VERSION ""

NS_ :

BS_:

BU_: A_IVC BLM CGW VKM

BO_ 32 ACU_A102: 8 CGW
  SG_ AirbagCrashOrder_v3 : 5|6@0+ (1,0) [0|0] "" A_IVC
  SG_ DirectionRear2ndCollision : 8|1@0+ (1,0) [0|0] "" A_IVC
  SG_ DirectionRollover2ndCollision : 9|1@0+ (1,0) [0|0] "" A_IVC
  SG_ DataSetCollisionValidity : 10|1@0+ (1,0) [0|0] "" A_IVC
  SG_ SeatBeltStatusDriver1stCollision : 12|2@0+ (1,0) [0|0] "" A_IVC
  SG_ SeatBeltStatusPass1stCollision : 14|2@0+ (1,0) [0|0] "" A_IVC
  SG_ DirectionLeft1stCollision : 15|1@0+ (1,0) [0|0] "" A_IVC
  SG_ SeatBeltStatusDriver2ndCollision : 18|2@0+ (1,0) [0|0] "" A_IVC
  SG_ SeatBeltStatusPass2ndcollision : 20|2@0+ (1,0) [0|0] "" A_IVC
  SG_ DirectionLeft2ndCollision : 21|1@0+ (1,0) [0|0] "" A_IVC
  SG_ DirectionRight2ndCollision : 22|1@0+ (1,0) [0|0] "" A_IVC
  SG_ DirectionFront2ndCollision : 23|1@0+ (1,0) [0|0] "" A_IVC
  SG_ MaxDeltaVLongi1stCollision : 31|8@0+ (1,-100) [-100|100] "Kph" A_IVC
  SG_ MaxDeltaVLat1stCollision : 39|8@0+ (1,-100) [-100|100] "Kph" A_IVC
  SG_ MaxDeltaVLongi2ndCollision : 47|8@0+ (1,-100) [-100|100] "Kph" A_IVC
  SG_ MaxDeltaVLat2ndCollision : 55|8@0+ (1,-100) [-100|100] "Kph" A_IVC
  SG_ DirectionRollover1stCollision : 56|1@0+ (1,0) [0|0] "" A_IVC
  SG_ RolloverDetection : 57|1@0+ (1,0) [0|0] "" A_IVC
  SG_ DirectionRight1stCollision : 61|1@0+ (1,0) [0|0] "" A_IVC
  SG_ DirectionFront1stCollision : 62|1@0+ (1,0) [0|0] "" A_IVC
  SG_ DirectionRear1stCollision : 63|1@0+ (1,0) [0|0] "" A_IVC

BO_ 116 ECM_A110: 8 CGW
  SG_ PowerTrainSetPoint : 11|10@0+ (0.125,0) [0|125] "%" A_IVC
  SG_ RawSensor : 17|10@0+ (0.125,0) [0|125] "%" A_IVC
  SG_ StopAutoPhase : 47|3@0+ (1,0) [0|0] "" A_IVC

BO_ 117 ECM_A112: 8 CGW
  SG_ ECM_EstimatedPWTWheelTorque : 11|15@0+ (2,-20000) [-20000|20000] "Nm" A_IVC
  SG_ PowerTrainStatus : 25|2@0+ (1,0) [0|0] "" A_IVC
  SG_ EngineStopRequestOrigin : 28|3@0+ (1,0) [0|0] "" A_IVC
  SG_ EngineRPM : 39|16@0+ (0.125,0) [0|8191.75] "rpm" A_IVC
  SG_ MeanEffectiveTorque : 55|12@0+ (0.5,-400) [-400|1647] "Nm" A_IVC

BO_ 168 STRG_A1: 7 CGW
  SG_ SteeringWheelRotationSpeed : 47|16@0+ (0.1,-3276.7) [-3276.7|3276.7] "°/s" A_IVC

BO_ 171 VDC_A6: 8 CGW
  SG_ YawRateCorrected : 10|11@0+ (0.1,-100) [-100|100] "°/s" A_IVC
  SG_ BrakingPressure : 31|8@0+ (0.5,0) [0|126] "bar" A_IVC
  SG_ SteerRackPinionAngleCorrect : 39|15@0+ (0.1,-1080) [-1080|1080] "°" A_IVC
  SG_ YawRateRaw : 55|11@0+ (0.1,-100) [-100|100] "°/s" A_IVC

BO_ 180 VDC_A5: 8 CGW
  SG_ LongitudinalAccelCorrected : 23|12@0+ (0.001,-2) [-2|2] "G" A_IVC
  SG_ LongitudinalAccelRaw : 27|12@0+ (0.001,-2) [-2|2] "G" A_IVC
  SG_ TransversalAccelCorrected : 47|12@0+ (0.001,-2) [-2|2] "G" A_IVC
  SG_ TransversalAccelRaw : 51|12@0+ (0.001,-2) [-2|2] "G" A_IVC

BO_ 255 VDC_A10: 6 CGW
  SG_ MastervacPressure_v2 : 23|7@0+ (1,0) [0|100] "kPa" A_IVC

BO_ 303 ATCU_A108: 7 CGW
  SG_ GearLeverPosition_v2 : 20|4@0+ (1,0) [0|0] "" A_IVC

BO_ 380 STRG_A2: 7 CGW
  SG_ SteeringWheelRotationSpeed_EPS : 47|16@0+ (0.1,-3276.7) [-3276.7|3276.7] "°/s" A_IVC

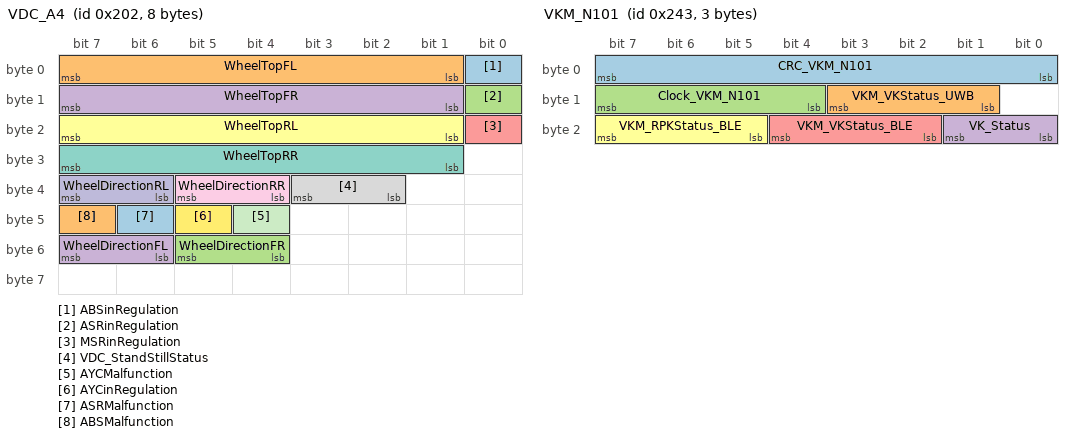
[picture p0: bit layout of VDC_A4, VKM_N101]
BO_ 514 VDC_A4: 8 CGW
  SG_ ABSinRegulation : 0|1@0+ (1,0) [0|0] "" A_IVC
  SG_ WheelTopFL : 7|7@0+ (1,0) [0|96] "top" A_IVC
  SG_ ASRinRegulation : 8|1@0+ (1,0) [0|0] "" A_IVC
  SG_ WheelTopFR : 15|7@0+ (1,0) [0|96] "top" A_IVC
  SG_ MSRinRegulation : 16|1@0+ (1,0) [0|0] "" A_IVC
  SG_ WheelTopRL : 23|7@0+ (1,0) [0|96] "top" A_IVC
  SG_ WheelTopRR : 31|7@0+ (1,0) [0|96] "top" A_IVC
  SG_ VDC_StandStillStatus : 35|2@0+ (1,0) [0|0] "" A_IVC
  SG_ WheelDirectionRR : 37|2@0+ (1,0) [0|0] "" A_IVC
  SG_ WheelDirectionRL : 39|2@0+ (1,0) [0|0] "" A_IVC
  SG_ AYCMalfunction : 44|1@0+ (1,0) [0|0] "" A_IVC
  SG_ AYCinRegulation : 45|1@0+ (1,0) [0|0] "" A_IVC
  SG_ ASRMalfunction : 46|1@0+ (1,0) [0|0] "" A_IVC
  SG_ ABSMalfunction : 47|1@0+ (1,0) [0|0] "" A_IVC
  SG_ WheelDirectionFR : 53|2@0+ (1,0) [0|0] "" A_IVC
  SG_ WheelDirectionFL : 55|2@0+ (1,0) [0|0] "" A_IVC

BO_ 534 EPS_A101: 4 CGW
  SG_ EPSWarning : 19|2@0+ (1,0) [0|0] "" A_IVC

BO_ 546 USM_A102: 4 CGW
  SG_ ProducerVoltageRequest : 7|8@0+ (0.025,11.7) [11.7|16] "V" A_IVC
  SG_ BatteryCurrentSensorValue : 15|10@0+ (1,-320) [-320|320] "A" A_IVC
  SG_ ACCompClutchStatus : 31|1@0+ (1,0) [0|0] "" A_IVC

BO_ 552 TCU_N103: 8 A_IVC
  SG_ TerminationReq_Offboard : 7|64@0+ (1,0) [0|0] "" VKM

BO_ 579 VKM_N101: 3 VKM
  SG_ CRC_VKM_N101 : 7|8@0+ (1,0) [0|255] "" CGW
  SG_ VKM_VKStatus_UWB : 11|3@0+ (1,0) [0|0] "" CGW
  SG_ Clock_VKM_N101 : 15|4@0+ (1,0) [0|15] "" CGW
  SG_ VK_Status : 17|2@0+ (1,0) [0|0] "" CGW
  SG_ VKM_VKStatus_BLE : 20|3@0+ (1,0) [0|0] "" CGW
  SG_ VKM_RPKStatus_BLE : 23|3@0+ (1,0) [0|0] "" CGW

BO_ 649 VDC_A3: 8 CGW
  SG_ WheelSpeedRL : 23|16@0+ (0.0416666667,0) [0|2730.583333] "rpm" A_IVC
  SG_ WheelSpeedRR : 39|16@0+ (0.0416666667,0) [0|2730.583333] "rpm" A_IVC
  SG_ VehicleSpeedBody : 55|16@0+ (0.01,0) [0|655.34] "km/h" A_IVC

BO_ 650 VDC_A9: 8 CGW
  SG_ WheelSpeedFR : 7|16@0+ (0.0416666667,0) [0|2730.583333] "rpm" A_IVC
  SG_ WheelSpeedFL : 23|16@0+ (0.0416666667,0) [0|2730.583333] "rpm" A_IVC
  SG_ VehicleSpeed : 39|16@0+ (0.01,0) [0|655.34] "km/h" A_IVC,BLM,VKM

BO_ 696 ECM_R104: 4 CGW
  SG_ LPGFuelConsumption : 7|8@0+ (0.000020,0) [0|0.00508] "L" A_IVC

BO_ 711 TCU_A105: 8 A_IVC
  SG_ PnCcertificateData_v3 : 7|48@0+ (1,0) [0|2.81474976710655E14] "" CGW
  SG_ PnCcertificateDataBlockNumber_v2 : 51|12@0+ (1,0) [0|4095] "" CGW
  SG_ CertificateDataBlockSize : 55|4@0+ (1,0) [0|15] "byte" CGW

BO_ 748 AVM_N110: 8 CGW
  SG_ RPK_VEHTOVKM_A1 : 7|64@0+ (1,0) [0|0] "" VKM

BO_ 749 AVM_N111: 8 CGW
  SG_ RPK_VEHTOVKM_A2 : 7|64@0+ (1,0) [0|0] "" VKM

BO_ 750 AVM_N112: 8 CGW
  SG_ RPK_VEHTOVKM_A3 : 7|64@0+ (1,0) [0|0] "" VKM

BO_ 751 AVM_N113: 8 CGW
  SG_ RPK_VEHTOVKM_A4 : 7|64@0+ (1,0) [0|0] "" VKM

BO_ 764 VKM_N102: 8 VKM
  SG_ RPK_VKMTOVEH_A1 : 7|64@0+ (1,0) [0|0] "" CGW

BO_ 765 VKM_N103: 8 VKM
  SG_ RPK_VKMTOVEH_A2 : 7|64@0+ (1,0) [0|0] "" CGW

BO_ 766 VKM_N104: 8 VKM
  SG_ RPK_VKMTOVEH_A3 : 7|64@0+ (1,0) [0|0] "" CGW

BO_ 767 VKM_N105: 8 VKM
  SG_ RPK_VKMTOVEH_A4 : 7|64@0+ (1,0) [0|0] "" CGW

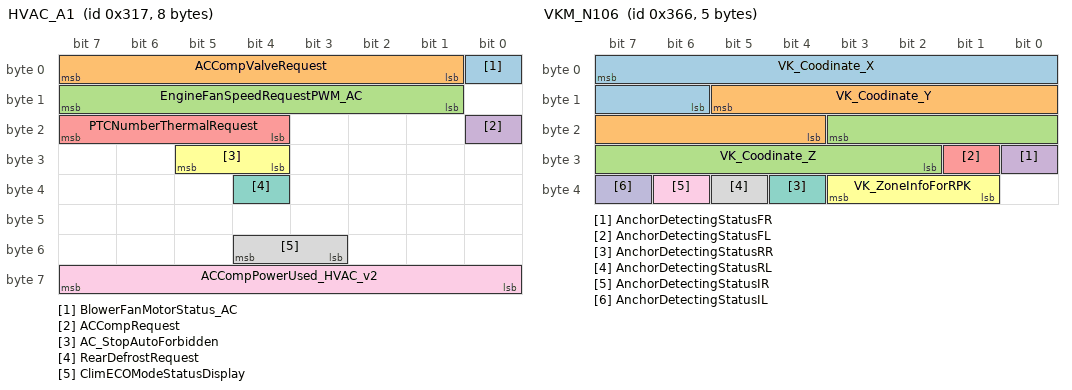
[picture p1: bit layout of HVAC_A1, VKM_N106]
BO_ 791 HVAC_A1: 8 CGW
  SG_ BlowerFanMotorStatus_AC : 0|1@0+ (1,0) [0|0] "" A_IVC
  SG_ ACCompValveRequest : 7|7@0+ (0.01,0) [0|1] "A" A_IVC
  SG_ EngineFanSpeedRequestPWM_AC : 15|7@0+ (1,0) [0|100] "%" A_IVC
  SG_ ACCompRequest : 16|1@0+ (1,0) [0|0] "" A_IVC
  SG_ PTCNumberThermalRequest : 23|4@0+ (1,0) [0|0] "" A_IVC
  SG_ AC_StopAutoForbidden : 29|2@0+ (1,0) [0|0] "" A_IVC
  SG_ RearDefrostRequest : 36|1@0+ (1,0) [0|0] "" A_IVC
  SG_ ClimECOModeStatusDisplay : 52|2@0+ (1,0) [0|0] "" A_IVC
  SG_ ACCompPowerUsed_HVAC_v2 : 63|8@0+ (25,0) [0|6350] "W" A_IVC

BO_ 823 HVAC_R4: 5 CGW
  SG_ ClimForcedRecyDisplay : 17|2@0+ (1,0) [0|0] "" A_IVC
  SG_ ClimAutoRecyclingDisplay : 31|2@0+ (1,0) [0|0] "" A_IVC

BO_ 867 AVM_N109: 1 CGW
  SG_ RPK_UWBRequest : 7|1@0+ (1,0) [0|0] "" VKM

BO_ 870 VKM_N106: 5 VKM
  SG_ VK_Coodinate_X : 7|10@0+ (4,-2048) [-2048|2044] "cm" CGW
  SG_ VK_Coodinate_Y : 13|10@0+ (4,-2048) [-2048|2044] "cm" CGW
  SG_ VK_Coodinate_Z : 19|10@0+ (4,-2048) [-2048|2044] "cm" CGW
  SG_ AnchorDetectingStatusFR : 24|1@0+ (1,0) [0|0] "" CGW
  SG_ AnchorDetectingStatusFL : 25|1@0+ (1,0) [0|0] "" CGW
  SG_ VK_ZoneInfoForRPK : 35|3@0+ (1,0) [0|0] "" CGW
  SG_ AnchorDetectingStatusRR : 36|1@0+ (1,0) [0|0] "" CGW
  SG_ AnchorDetectingStatusRL : 37|1@0+ (1,0) [0|0] "" CGW
  SG_ AnchorDetectingStatusIR : 38|1@0+ (1,0) [0|0] "" CGW
  SG_ AnchorDetectingStatusIL : 39|1@0+ (1,0) [0|0] "" CGW

BO_ 878 ECM_INIT_INFO_RN1: 7 CGW
  SG_ StarterActivationCounter : 7|16@0+ (10,0) [0|600000] "" A_IVC
  SG_ HPPumpActivationCounter : 23|16@0+ (10,0) [0|600000] "" A_IVC
  SG_ BSGActivationCounter : 39|21@0+ (1,0) [0|1500000] "nb of restart" A_IVC

BO_ 893 EPS_A103: 3 CGW
  SG_ LDW_VibrationIntensityState : 2|2@0+ (1,0) [0|0] "" A_IVC
  SG_ CDU_SteeringWheelTorqueLevel : 21|2@0+ (1,0) [0|0] "" A_IVC

BO_ 896 TCO1: 3 CGW
  SG_ DTCO_Driver1TimeRelatedStates : 11|4@0+ (1,0) [0|0] "" A_IVC
  SG_ DTCO_OverSpeed : 15|2@0+ (1,0) [0|0] "" A_IVC
  SG_ DTCO_Driver2TimeRelatedStates : 19|4@0+ (1,0) [0|0] "" A_IVC

BO_ 909 VKM_N113: 8 VKM
  SG_ NFCframe_VKM_to_NFC_Inside : 7|64@0+ (1,0) [0|0] "" CGW

BO_ 944 BCM_A117: 3 CGW
  SG_ HeavyRain_Status : 19|1@0+ (1,0) [0|0] "" A_IVC
  SG_ BCM_ContextSteeringSwitchStatus : 20|1@0+ (1,0) [0|0] "" A_IVC

BO_ 955 ECM_R102: 8 CGW
  SG_ RST_Boost_Duration_MMI : 7|7@0+ (1,0) [0|100] "%" A_IVC
  SG_ RST_Boost_Activation_MMI : 15|2@0+ (1,0) [0|0] "" A_IVC
  SG_ LPGLevelForDisplay : 23|8@0+ (0.25,0) [0|63.5] "L" A_IVC

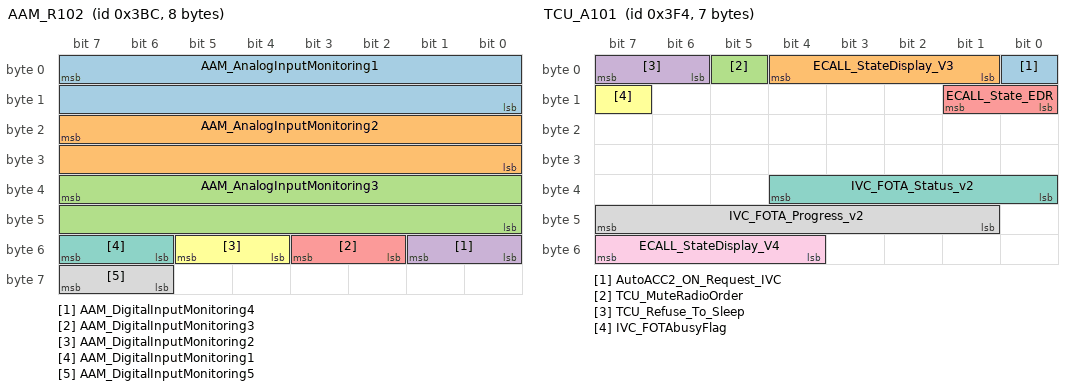
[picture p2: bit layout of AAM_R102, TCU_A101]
BO_ 956 AAM_R102: 8 CGW
  SG_ AAM_AnalogInputMonitoring1 : 7|16@0+ (1,0) [0|65534] "wu" A_IVC
  SG_ AAM_AnalogInputMonitoring2 : 23|16@0+ (1,0) [0|65534] "wu" A_IVC
  SG_ AAM_AnalogInputMonitoring3 : 39|16@0+ (1,0) [0|65534] "wu" A_IVC
  SG_ AAM_DigitalInputMonitoring4 : 49|2@0+ (1,0) [0|0] "" A_IVC
  SG_ AAM_DigitalInputMonitoring3 : 51|2@0+ (1,0) [0|0] "" A_IVC
  SG_ AAM_DigitalInputMonitoring2 : 53|2@0+ (1,0) [0|0] "" A_IVC
  SG_ AAM_DigitalInputMonitoring1 : 55|2@0+ (1,0) [0|0] "" A_IVC
  SG_ AAM_DigitalInputMonitoring5 : 63|2@0+ (1,0) [0|0] "" A_IVC

BO_ 960 PSD_A101: 3 CGW
  SG_ PSD_R_LatchStatus : 9|2@0+ (1,0) [0|0] "" VKM
  SG_ PSD_R_FailureStatus : 12|3@0+ (1,0) [0|0] "" VKM
  SG_ PSD_R_ZoningPosition : 15|3@0+ (1,0) [0|0] "" VKM
  SG_ PSD_R_MovementAuthorizationState : 23|2@0+ (1,0) [0|0] "" VKM

BO_ 967 IVI_A5: 8 CGW
  SG_ SwitchRequest_AVM : 16|1@0+ (1,0) [0|0] "" A_IVC
  SG_ PassengerHeatingRequest : 33|2@0+ (1,0) [0|0] "" A_IVC

BO_ 970 BLM_A101: 1 BLM
  SG_ VirtualKeyState : 4|1@0+ (1,0) [0|0] "" A_IVC,CGW
  SG_ VirtualKeyActivationStatus : 5|1@0+ (1,0) [0|0] "" CGW
  SG_ BLM_RefuseToSleep : 7|2@0+ (1,0) [0|0] "" CGW

BO_ 996 DSMU_A101: 3 CGW
  SG_ DriverMassageProgramState_v3 : 20|4@0+ (1,0) [0|0] "" A_IVC

BO_ 1000 HFM_A101: 7 CGW
  SG_ RemoteLight_HFM : 2|1@0+ (1,0) [0|0] "" A_IVC
  SG_ IKeyRemoteUnProtectStatus : 16|1@0+ (1,0) [0|0] "" A_IVC
  SG_ IkeyfobInsideVehicleFound_VK : 42|3@0+ (1,0) [0|0] "" VKM
  SG_ VKAuthRequest : 45|1@0+ (1,0) [0|0] "" VKM

BO_ 1001 PSCU_A102: 1 CGW
  SG_ PassengerMassageProgramState_v3 : 3|4@0+ (1,0) [0|0] "" A_IVC

BO_ 1011 VKM_N107: 6 VKM
  SG_ VKM_RefuseToSleep : 44|2@0+ (1,0) [0|0] "" CGW
  SG_ NFC_Inside_activation_frame : 45|1@0+ (1,0) [0|0] "" CGW
  SG_ InsideIkeyfobSearchRequest : 47|1@0+ (1,0) [0|0] "" CGW

BO_ 1012 TCU_A101: 7 A_IVC
  SG_ AutoACC2_ON_Request_IVC : 0|1@0+ (1,0) [0|0] "" CGW
  SG_ ECALL_StateDisplay_V3 : 4|4@0+ (1,0) [0|0] "" CGW
  SG_ TCU_MuteRadioOrder : 5|1@0+ (1,0) [0|0] "" CGW
  SG_ TCU_Refuse_To_Sleep : 7|2@0+ (1,0) [0|0] "" CGW
  SG_ ECALL_State_EDR : 9|2@0+ (1,0) [0|0] "" CGW
  SG_ IVC_FOTAbusyFlag : 15|1@0+ (1,0) [0|0] "" CGW
  SG_ IVC_FOTA_Status_v2 : 36|5@0+ (1,0) [0|0] "" CGW
  SG_ IVC_FOTA_Progress_v2 : 47|7@0+ (1,0) [0|100] "%" CGW
  SG_ ECALL_StateDisplay_V4 : 55|4@0+ (1,0) [0|0] "" CGW

BO_ 1030 AVM_N106: 6 CGW
  SG_ RPK_RegistAddress3 : 7|48@0+ (1,0) [0|2.81474976710655E14] "-" VKM

BO_ 1031 AVM_N107: 6 CGW
  SG_ RPK_RegistAddress4 : 7|48@0+ (1,0) [0|2.81474976710655E14] "-" VKM

BO_ 1036 AVM_N108: 6 CGW
  SG_ RPK_RegistAddress5 : 7|48@0+ (1,0) [0|2.81474976710655E14] "-" VKM

BO_ 1047 AVM_A119: 3 CGW
  SG_ HFP_ExtendedInstrContentDisplay2 : 23|5@0+ (1,0) [0|0] "" A_IVC

BO_ 1049 AAM_R101: 2 CGW
  SG_ AAM_StopAutoForbidden : 2|2@0+ (1,0) [0|0] "" A_IVC

BO_ 1055 HEVC_R129: 8 CGW
  SG_ RE_ElecMaxGenTorque_BLMS : 6|10@0+ (0.5,0) [0|500] "Nm" A_IVC
  SG_ RE_ElecMaxMotorTorque_BLMS : 12|10@0+ (0.5,0) [0|500] "Nm" A_IVC

BO_ 1064 HEVC_A104: 7 CGW
  SG_ EcoNavFuelSaving : 0|10@0+ (0.01,0) [0|10] "L" A_IVC
  SG_ HVbatteryTemperature : 7|7@0+ (1,-40) [-40|80] "°C" A_IVC
  SG_ VehicleAutonomyZEV : 22|10@0+ (1,0) [0|1022] "km" A_IVC
  SG_ HVBatConditionningMode : 28|2@0+ (1,0) [0|0] "" A_IVC

BO_ 1065 HEVC_A105: 8 CGW
  SG_ HVBatteryCoolingLoopTemperature : 7|8@0+ (1,-50) [-50|130] "°C" A_IVC
  SG_ HVBatteryLow : 8|1@0+ (1,0) [0|0] "" A_IVC
  SG_ HVBatteryEnergyLevel : 15|7@0+ (1,0) [0|100] "%" A_IVC
  SG_ ChargingPlugConnected_v2 : 23|2@0+ (1,0) [0|0] "" A_IVC
  SG_ EcoNavStatus_v2 : 36|4@0+ (1,0) [0|0] "" A_IVC

BO_ 1066 HEVC_A106: 8 CGW
  SG_ ElecMachineSpeed_EDR : 35|12@0+ (10,-20000) [-20000|20000] "rpm" A_IVC
  SG_ HVbatteryChargeType_v2 : 50|3@0+ (1,0) [0|0] "" A_IVC
  SG_ RegenBrakingLevelDisplay : 53|3@0+ (1,0) [0|0] "" A_IVC
  SG_ RelativeEnginePowerv2 : 63|7@0+ (1,0) [0|100] "%" A_IVC

BO_ 1067 HEVC_A107: 8 CGW
  SG_ RE_ElecMachineTemp_BLMS : 26|8@0+ (1,-40) [-40|210] "°C" A_IVC
  SG_ RE_InverterTemp_BLMS : 34|8@0+ (1,-40) [-40|210] "°C" A_IVC
  SG_ RE_ElecMachineSpeed_BLMS : 42|12@0+ (10,-20000) [-20000|20000] "rpm" A_IVC

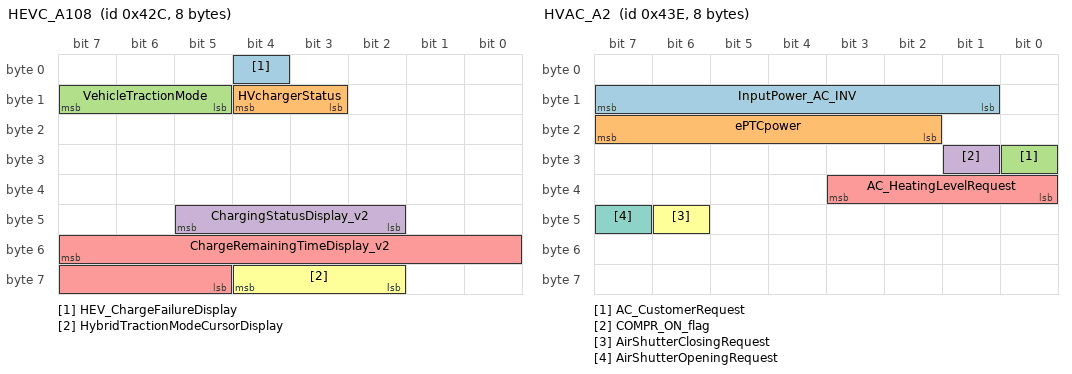
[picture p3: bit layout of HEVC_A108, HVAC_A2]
BO_ 1068 HEVC_A108: 8 CGW
  SG_ HEV_ChargeFailureDisplay : 4|1@0+ (1,0) [0|0] "" A_IVC
  SG_ HVchargerStatus : 12|2@0+ (1,0) [0|0] "" A_IVC
  SG_ VehicleTractionMode : 15|3@0+ (1,0) [0|0] "" A_IVC
  SG_ ChargingStatusDisplay_v2 : 45|4@0+ (1,0) [0|0] "" A_IVC
  SG_ ChargeRemainingTimeDisplay_v2 : 55|11@0+ (1,0) [0|2046] "min" A_IVC
  SG_ HybridTractionModeCursorDisplay : 60|3@0+ (1,0) [0|0] "" A_IVC

BO_ 1070 HEVC_R101: 7 CGW
  SG_ UserSOC : 7|8@0+ (0.392157,0) [0|100] "%" A_IVC

BO_ 1071 HEVC_R103: 3 CGW
  SG_ AvailableEnergy_HEVC : 12|11@0+ (0.05,0) [0|100] "kWh" A_IVC

BO_ 1076 HFM_A104: 8 CGW
  SG_ BadgeBatteryLow : 8|1@0+ (1,0) [0|0] "" A_IVC
  SG_ PushtoStartButton : 51|1@0+ (1,0) [0|0] "" A_IVC

BO_ 1081 VDC_A114: 7 CGW
  SG_ SlopeEstimation : 7|8@0+ (0.2,-15) [-15|15] "°" A_IVC
  SG_ DistanceTotalizer : 15|28@0+ (0.01,0) [0|2600000] "km" A_IVC,BLM,VKM

BO_ 1086 HVAC_A2: 8 CGW
  SG_ InputPower_AC_INV : 15|7@0+ (50,0) [0|5100] "W" A_IVC
  SG_ ePTCpower : 23|6@0+ (250,0) [0|10000] "W" A_IVC
  SG_ AC_CustomerRequest : 24|1@0+ (1,0) [0|0] "" A_IVC
  SG_ COMPR_ON_flag : 25|1@0+ (1,0) [0|0] "" A_IVC
  SG_ AC_HeatingLevelRequest : 35|4@0+ (1,0) [0|10] "wu" A_IVC
  SG_ AirShutterClosingRequest : 46|1@0+ (1,0) [0|0] "" A_IVC
  SG_ AirShutterOpeningRequest : 47|1@0+ (1,0) [0|0] "" A_IVC

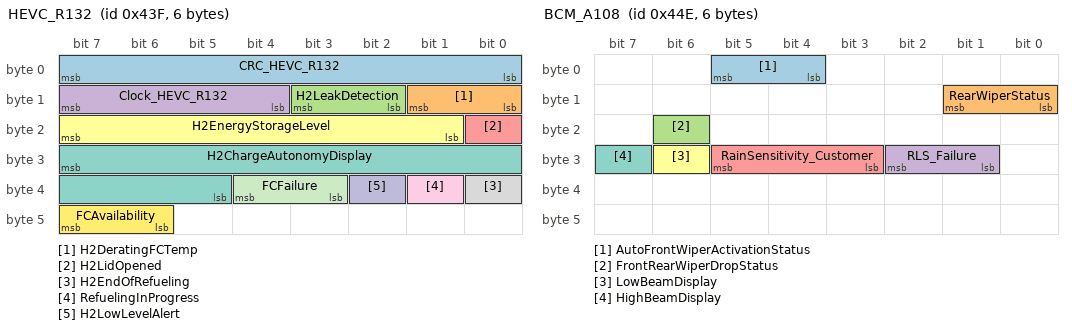
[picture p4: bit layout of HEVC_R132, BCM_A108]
BO_ 1087 HEVC_R132: 6 CGW
  SG_ CRC_HEVC_R132 : 7|8@0+ (1,0) [0|255] "" A_IVC
  SG_ H2DeratingFCTemp : 9|2@0+ (1,0) [0|0] "" A_IVC
  SG_ H2LeakDetection : 11|2@0+ (1,0) [0|0] "" A_IVC
  SG_ Clock_HEVC_R132 : 15|4@0+ (1,0) [0|15] "" A_IVC
  SG_ H2LidOpened : 16|1@0+ (1,0) [0|0] "" A_IVC
  SG_ H2EnergyStorageLevel : 23|7@0+ (1,0) [0|100] "%" A_IVC
  SG_ H2ChargeAutonomyDisplay : 31|11@0+ (1,0) [0|2047] "KM" A_IVC
  SG_ H2EndOfRefueling : 32|1@0+ (1,0) [0|0] "" A_IVC
  SG_ RefuelingInProgress : 33|1@0+ (1,0) [0|0] "" A_IVC
  SG_ H2LowLevelAlert : 34|1@0+ (1,0) [0|0] "" A_IVC
  SG_ FCFailure : 36|2@0+ (1,0) [0|0] "" A_IVC
  SG_ FCAvailability : 47|2@0+ (1,0) [0|0] "" A_IVC

BO_ 1090 PSDL_A101: 3 CGW
  SG_ PSD_L_ZoningPosition : 10|3@0+ (1,0) [0|0] "" VKM
  SG_ PSD_L_MovementAuthorizationState : 15|2@0+ (1,0) [0|0] "" VKM
  SG_ PSD_L_LatchStatus : 20|2@0+ (1,0) [0|0] "" VKM
  SG_ PSD_L_FailureStatus : 23|3@0+ (1,0) [0|0] "" VKM

BO_ 1099 ATCU_A109: 8 CGW
  SG_ RST_LaunchControlReadyMMI : 13|2@0+ (1,0) [0|0] "" A_IVC
  SG_ ATCVT_TowingMode : 14|1@0+ (1,0) [0|0] "" A_IVC
  SG_ ATCVT_RangeIndicationExtended : 44|6@0+ (1,0) [0|0] "" A_IVC

BO_ 1100 ATCU_A110: 6 CGW
  SG_ AT_Parkfailure : 21|1@0+ (1,0) [0|0] "" A_IVC
  SG_ TransmRangeEngaged_Current : 24|4@0+ (1,0) [0|0] "" A_IVC
  SG_ ShifterPosition : 27|3@0+ (1,0) [0|0] "" A_IVC

BO_ 1101 BCM_A107: 5 CGW
  SG_ TurnSwitchStatus : 18|3@0+ (1,0) [0|0] "" A_IVC
  SG_ FlashingIndicatorStatusDisplay : 23|3@0+ (1,0) [0|0] "" A_IVC

BO_ 1102 BCM_A108: 6 CGW
  SG_ AutoFrontWiperActivationStatus : 5|2@0+ (1,0) [0|0] "" A_IVC
  SG_ RearWiperStatus : 9|2@0+ (1,0) [0|0] "" A_IVC
  SG_ FrontRearWiperDropStatus : 22|1@0+ (1,0) [0|0] "" A_IVC
  SG_ RLS_Failure : 26|2@0+ (1,0) [0|0] "" A_IVC
  SG_ RainSensitivity_Customer : 29|3@0+ (1,0) [0|0] "" A_IVC
  SG_ LowBeamDisplay : 30|1@0+ (1,0) [0|0] "" A_IVC
  SG_ HighBeamDisplay : 31|1@0+ (1,0) [0|0] "" A_IVC

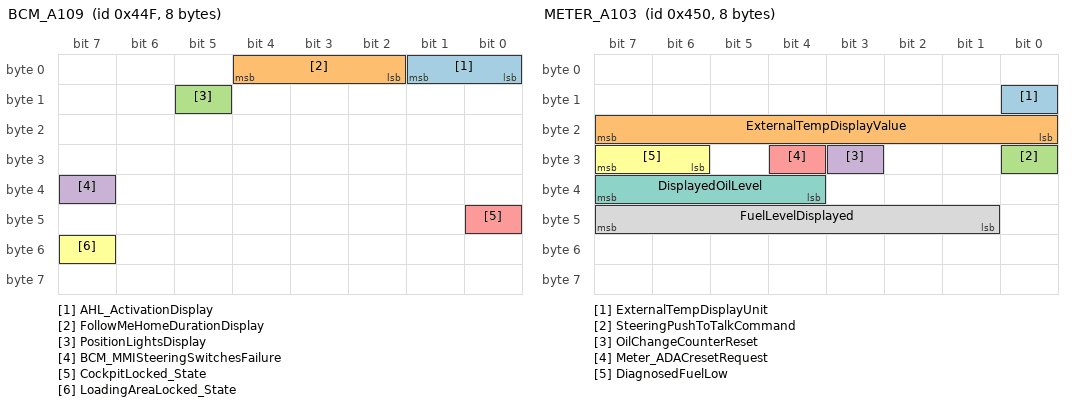
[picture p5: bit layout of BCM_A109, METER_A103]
BO_ 1103 BCM_A109: 8 CGW
  SG_ AHL_ActivationDisplay : 1|2@0+ (1,0) [0|0] "" A_IVC
  SG_ FollowMeHomeDurationDisplay : 4|3@0+ (1,0) [0|0] "" A_IVC
  SG_ PositionLightsDisplay : 13|1@0+ (1,0) [0|0] "" A_IVC
  SG_ BCM_MMISteeringSwitchesFailure : 39|1@0+ (1,0) [0|0] "" A_IVC
  SG_ CockpitLocked_State : 40|1@0+ (1,0) [0|0] "" BLM
  SG_ LoadingAreaLocked_State : 55|1@0+ (1,0) [0|0] "" BLM

BO_ 1104 METER_A103: 8 CGW
  SG_ ExternalTempDisplayUnit : 8|1@0+ (1,0) [0|0] "" A_IVC
  SG_ ExternalTempDisplayValue : 23|8@0+ (1,-40) [-40|140] "" A_IVC
  SG_ SteeringPushToTalkCommand : 24|1@0+ (1,0) [0|0] "" A_IVC
  SG_ OilChangeCounterReset : 27|1@0+ (1,0) [0|0] "" A_IVC
  SG_ Meter_ADACresetRequest : 28|1@0+ (1,0) [0|0] "" A_IVC
  SG_ DiagnosedFuelLow : 31|2@0+ (1,0) [0|0] "" A_IVC
  SG_ DisplayedOilLevel : 39|4@0+ (1,0) [0|0] "" A_IVC
  SG_ FuelLevelDisplayed : 47|7@0+ (1,0) [0|80] "L" A_IVC

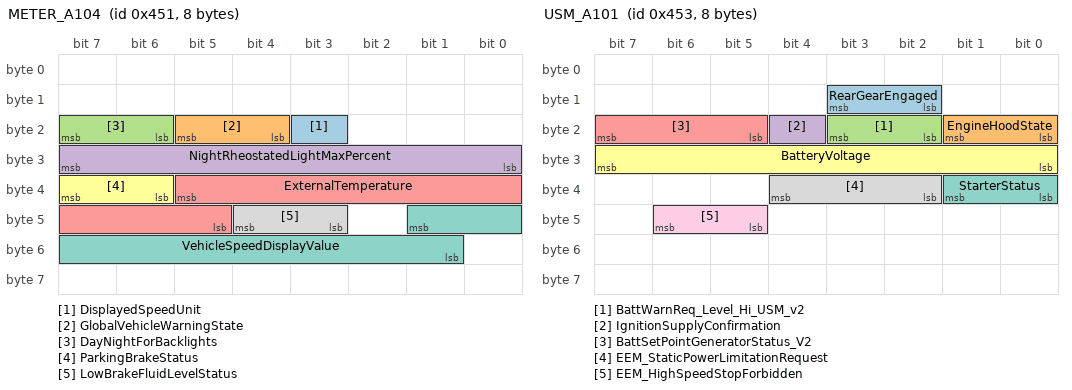
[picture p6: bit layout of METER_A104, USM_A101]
BO_ 1105 METER_A104: 8 CGW
  SG_ DisplayedSpeedUnit : 19|1@0+ (1,0) [0|0] "" A_IVC
  SG_ GlobalVehicleWarningState : 21|2@0+ (1,0) [0|0] "" A_IVC
  SG_ DayNightForBacklights : 23|2@0+ (1,0) [0|0] "" A_IVC
  SG_ NightRheostatedLightMaxPercent : 31|8@0+ (0.4,0) [0|100] "%" A_IVC
  SG_ ExternalTemperature : 37|9@0+ (0.25,-50) [-50|70] "°C" A_IVC
  SG_ ParkingBrakeStatus : 39|2@0+ (1,0) [0|0] "" A_IVC
  SG_ VehicleSpeedDisplayValue : 41|9@0+ (1,0) [0|510] "" A_IVC
  SG_ LowBrakeFluidLevelStatus : 44|2@0+ (1,0) [0|0] "" A_IVC

BO_ 1106 METER_A108: 5 CGW
  SG_ TimeBeforeOverhaul : 15|9@0+ (1,0) [0|511] "day" A_IVC
  SG_ DayNightStatusForB_Switches : 17|1@0+ (1,0) [0|0] "" A_IVC
  SG_ TripAverageSpeed : 31|12@0+ (0.1,0) [0|409.5] "" A_IVC

BO_ 1107 USM_A101: 8 CGW
  SG_ RearGearEngaged : 11|2@0+ (1,0) [0|0] "" A_IVC
  SG_ EngineHoodState : 17|2@0+ (1,0) [0|0] "" A_IVC
  SG_ BattWarnReq_Level_Hi_USM_v2 : 19|2@0+ (1,0) [0|0] "" A_IVC
  SG_ IgnitionSupplyConfirmation : 20|1@0+ (1,0) [0|0] "" A_IVC
  SG_ BattSetPointGeneratorStatus_V2 : 23|3@0+ (1,0) [0|0] "" A_IVC
  SG_ BatteryVoltage : 31|8@0+ (0.06,6) [6|18] "V" A_IVC,BLM,VKM
  SG_ StarterStatus : 33|2@0+ (1,0) [0|0] "" A_IVC
  SG_ EEM_StaticPowerLimitationRequest : 36|3@0+ (1,0) [0|0] "" A_IVC
  SG_ EEM_HighSpeedStopForbidden : 46|2@0+ (1,0) [0|0] "" A_IVC

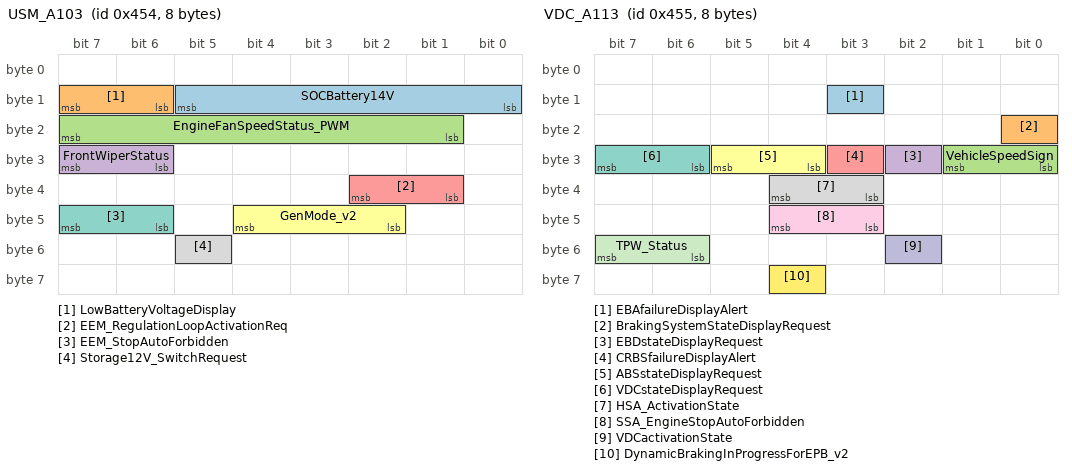
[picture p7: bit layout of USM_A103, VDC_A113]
BO_ 1108 USM_A103: 8 CGW
  SG_ SOCBattery14V : 13|6@0+ (0.5,69) [69|100] "%" A_IVC
  SG_ LowBatteryVoltageDisplay : 15|2@0+ (1,0) [0|0] "" A_IVC
  SG_ EngineFanSpeedStatus_PWM : 23|7@0+ (1,0) [0|100] "%" A_IVC
  SG_ FrontWiperStatus : 31|2@0+ (1,0) [0|0] "" A_IVC
  SG_ EEM_RegulationLoopActivationReq : 34|2@0+ (1,0) [0|0] "" A_IVC
  SG_ GenMode_v2 : 44|3@0+ (1,0) [0|0] "" A_IVC
  SG_ EEM_StopAutoForbidden : 47|2@0+ (1,0) [0|0] "" A_IVC
  SG_ Storage12V_SwitchRequest : 53|1@0+ (1,0) [0|0] "" A_IVC

BO_ 1109 VDC_A113: 8 CGW
  SG_ EBAfailureDisplayAlert : 11|1@0+ (1,0) [0|0] "" A_IVC
  SG_ BrakingSystemStateDisplayRequest : 16|1@0+ (1,0) [0|0] "" A_IVC
  SG_ VehicleSpeedSign : 25|2@0+ (1,0) [0|0] "" A_IVC
  SG_ EBDstateDisplayRequest : 26|1@0+ (1,0) [0|0] "" A_IVC
  SG_ CRBSfailureDisplayAlert : 27|1@0+ (1,0) [0|0] "" A_IVC
  SG_ ABSstateDisplayRequest : 29|2@0+ (1,0) [0|0] "" A_IVC
  SG_ VDCstateDisplayRequest : 31|2@0+ (1,0) [0|0] "" A_IVC
  SG_ HSA_ActivationState : 36|2@0+ (1,0) [0|0] "" A_IVC
  SG_ SSA_EngineStopAutoForbidden : 44|2@0+ (1,0) [0|0] "" A_IVC
  SG_ VDCactivationState : 50|1@0+ (1,0) [0|0] "" A_IVC
  SG_ TPW_Status : 55|2@0+ (1,0) [0|0] "" A_IVC
  SG_ DynamicBrakingInProgressForEPB_v2 : 60|1@0+ (1,0) [0|0] "" A_IVC

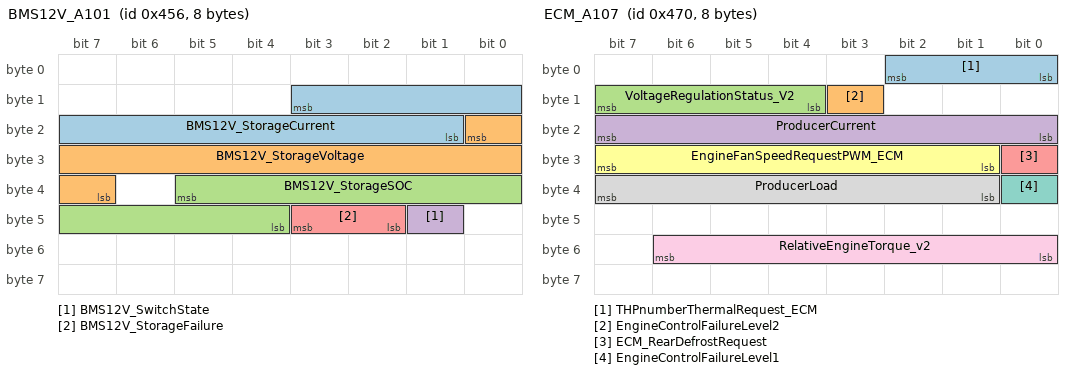
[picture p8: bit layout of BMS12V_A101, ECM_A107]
BO_ 1110 BMS12V_A101: 8 CGW
  SG_ BMS12V_StorageCurrent : 11|11@0+ (0.25,-150) [-150|300] "A" A_IVC
  SG_ BMS12V_StorageVoltage : 16|10@0+ (0.01,9) [9|16] "V" A_IVC
  SG_ BMS12V_StorageSOC : 37|10@0+ (0.1,0) [0|100] "%" A_IVC
  SG_ BMS12V_SwitchState : 41|1@0+ (1,0) [0|0] "" A_IVC
  SG_ BMS12V_StorageFailure : 43|2@0+ (1,0) [0|0] "" A_IVC

BO_ 1119 ECM_A108: 4 CGW
  SG_ BattWarnReq_Level_Hi_ECM_v2 : 11|2@0+ (1,0) [0|0] "" A_IVC
  SG_ EngineCoolantTemp : 23|8@0+ (1,-40) [-40|214] "°C" A_IVC

BO_ 1120 ECM_R101: 8 CGW
  SG_ AccelerationIndicator : 39|7@0+ (1,0) [0|127] "%" A_IVC
  SG_ FluentDrivingIndicator : 47|7@0+ (1,0) [0|127] "%" A_IVC
  SG_ GSI_Respect : 55|7@0+ (1,0) [0|127] "%" A_IVC

BO_ 1136 ECM_A107: 8 CGW
  SG_ THPnumberThermalRequest_ECM : 2|3@0+ (1,0) [0|0] "" A_IVC
  SG_ EngineControlFailureLevel2 : 11|1@0+ (1,0) [0|0] "" A_IVC
  SG_ VoltageRegulationStatus_V2 : 15|4@0+ (1,0) [0|0] "" A_IVC
  SG_ ProducerCurrent : 23|8@0+ (1,0) [0|255] "A" A_IVC
  SG_ ECM_RearDefrostRequest : 24|1@0+ (1,0) [0|0] "" A_IVC
  SG_ EngineFanSpeedRequestPWM_ECM : 31|7@0+ (1,0) [0|100] "%" A_IVC
  SG_ EngineControlFailureLevel1 : 32|1@0+ (1,0) [0|0] "" A_IVC
  SG_ ProducerLoad : 39|7@0+ (1,0) [0|100] "%" A_IVC
  SG_ RelativeEngineTorque_v2 : 54|7@0+ (1,0) [0|100] "%" A_IVC

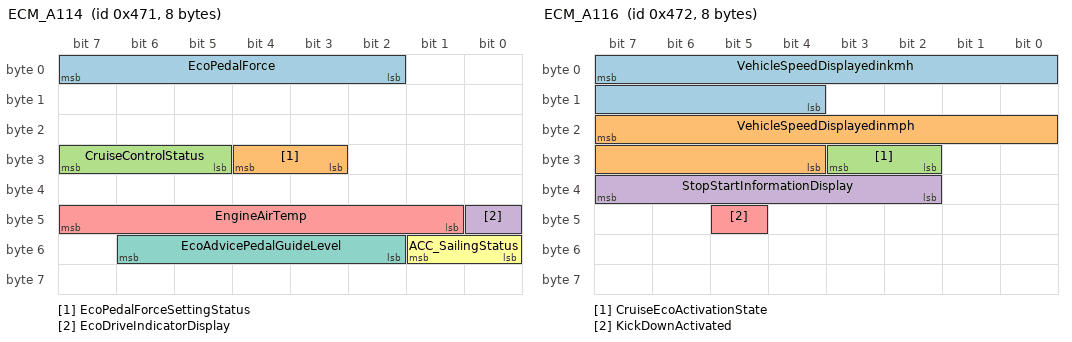
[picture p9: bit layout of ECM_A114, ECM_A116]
BO_ 1137 ECM_A114: 8 CGW
  SG_ EcoPedalForce : 7|6@0+ (0.5,0) [0|15.5] "N" A_IVC
  SG_ EcoPedalForceSettingStatus : 28|2@0+ (1,0) [0|0] "" A_IVC
  SG_ CruiseControlStatus : 31|3@0+ (1,0) [0|0] "" A_IVC
  SG_ EcoDriveIndicatorDisplay : 40|1@0+ (1,0) [0|0] "" A_IVC
  SG_ EngineAirTemp : 47|7@0+ (1,-40) [-40|86] "°C" A_IVC
  SG_ ACC_SailingStatus : 49|2@0+ (1,0) [0|0] "" A_IVC
  SG_ EcoAdvicePedalGuideLevel : 54|5@0+ (1,0) [0|30] "wu" A_IVC

BO_ 1138 ECM_A116: 8 CGW
  SG_ VehicleSpeedDisplayedinkmh : 7|12@0+ (0.1,0) [0|409.4] "km/h" A_IVC
  SG_ VehicleSpeedDisplayedinmph : 23|12@0+ (0.1,0) [0|409.4] "m/h" A_IVC
  SG_ CruiseEcoActivationState : 27|2@0+ (1,0) [0|0] "" A_IVC
  SG_ StopStartInformationDisplay : 39|6@0+ (1,0) [0|0] "" A_IVC
  SG_ KickDownActivated : 45|1@0+ (1,0) [0|0] "" A_IVC

BO_ 1139 ECM_A117: 6 CGW
  SG_ AtmoPressure : 7|10@0+ (0.1,10) [10|110] "kPa" A_IVC
  SG_ DBC_FailureStatus_v2 : 13|2@0+ (1,0) [0|0] "" A_IVC
  SG_ LowPressureACCut : 19|1@0+ (1,0) [0|0] "" A_IVC
  SG_ StopStartActivationStatus : 20|1@0+ (1,0) [0|0] "" A_IVC

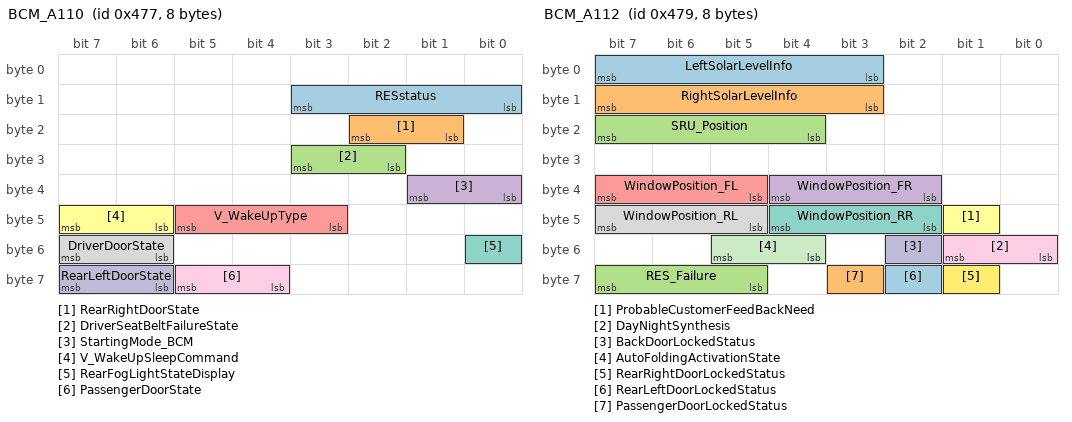
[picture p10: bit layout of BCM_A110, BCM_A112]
BO_ 1143 BCM_A110: 8 CGW
  SG_ RESstatus : 11|4@0+ (1,0) [0|0] "" A_IVC
  SG_ RearRightDoorState : 18|2@0+ (1,0) [0|0] "" A_IVC,BLM,VKM
  SG_ DriverSeatBeltFailureState : 27|2@0+ (1,0) [0|0] "" A_IVC
  SG_ StartingMode_BCM : 33|2@0+ (1,0) [0|0] "" A_IVC
  SG_ V_WakeUpType : 45|3@0+ (1,0) [0|0] "" A_IVC
  SG_ V_WakeUpSleepCommand : 47|2@0+ (1,0) [0|0] "" A_IVC,BLM,VKM
  SG_ RearFogLightStateDisplay : 48|1@0+ (1,0) [0|0] "" A_IVC
  SG_ DriverDoorState : 55|2@0+ (1,0) [0|0] "" A_IVC,BLM,VKM
  SG_ PassengerDoorState : 61|2@0+ (1,0) [0|0] "" A_IVC,BLM,VKM
  SG_ RearLeftDoorState : 63|2@0+ (1,0) [0|0] "" A_IVC,BLM,VKM

BO_ 1144 BCM_A111: 8 CGW
  SG_ ElectricalPowerDrived : 7|5@0+ (100,0) [0|3000] "W" A_IVC
  SG_ TailGateButtonPushed : 10|2@0+ (1,0) [0|0] "" A_IVC
  SG_ WakeUpType : 13|3@0+ (1,0) [0|0] "" A_IVC,BLM,VKM
  SG_ RearDefrostEngaged : 16|1@0+ (1,0) [0|0] "" A_IVC
  SG_ PositionLightsRequest : 17|1@0+ (1,0) [0|0] "" A_IVC
  SG_ FrontFogLightsRequest : 18|1@0+ (1,0) [0|0] "" A_IVC
  SG_ SmartKeylessInformationDisplay : 23|5@0+ (1,0) [0|0] "" BLM
  SG_ PTCNumberThermalStatus : 31|4@0+ (1,0) [0|0] "" A_IVC
  SG_ DriverDoorLockedStatus : 32|1@0+ (1,0) [0|0] "" A_IVC,BLM,VKM
  SG_ DayTimeRunningLightRequest : 33|1@0+ (1,0) [0|0] "" A_IVC
  SG_ HornRequest : 36|3@0+ (1,0) [0|0] "" A_IVC
  SG_ WarningLightsStatus : 41|1@0+ (1,0) [0|0] "" A_IVC
  SG_ VehicleOutsideLockedState : 42|1@0+ (1,0) [0|0] "" A_IVC,BLM,VKM
  SG_ DriverSidePosition : 43|1@0+ (1,0) [0|0] "" A_IVC
  SG_ FrontFogLightsDisplay : 48|1@0+ (1,0) [0|0] "" A_IVC
  SG_ FrontDefrostEngaged : 49|1@0+ (1,0) [0|0] "" A_IVC
  SG_ ManualShiftLeverPosition : 51|2@0+ (1,0) [0|0] "" A_IVC
  SG_ StopStartSwitch : 53|2@0+ (1,0) [0|0] "" A_IVC
  SG_ ShiftPaddleRequest : 55|2@0+ (1,0) [0|0] "" A_IVC
  SG_ BrakeLampStatus : 57|1@0+ (1,0) [0|0] "" A_IVC
  SG_ HeadLampsWasherRequest : 60|1@0+ (1,0) [0|0] "" A_IVC

BO_ 1145 BCM_A112: 8 CGW
  SG_ LeftSolarLevelInfo : 7|5@0+ (50,0) [0|1500] "W" A_IVC
  SG_ RightSolarLevelInfo : 15|5@0+ (50,0) [0|1500] "W" A_IVC
  SG_ SRU_Position : 23|4@0+ (1,0) [0|0] "" A_IVC,VKM
  SG_ WindowPosition_FR : 36|3@0+ (1,0) [0|0] "" A_IVC
  SG_ WindowPosition_FL : 39|3@0+ (1,0) [0|0] "" A_IVC
  SG_ ProbableCustomerFeedBackNeed : 41|1@0+ (1,0) [0|0] "" A_IVC
  SG_ WindowPosition_RR : 44|3@0+ (1,0) [0|0] "" A_IVC
  SG_ WindowPosition_RL : 47|3@0+ (1,0) [0|0] "" A_IVC
  SG_ DayNightSynthesis : 49|2@0+ (1,0) [0|0] "" A_IVC
  SG_ BackDoorLockedStatus : 50|1@0+ (1,0) [0|0] "" A_IVC,BLM,VKM
  SG_ AutoFoldingActivationState : 53|2@0+ (1,0) [0|0] "" A_IVC
  SG_ RearRightDoorLockedStatus : 57|1@0+ (1,0) [0|0] "" A_IVC,BLM,VKM
  SG_ RearLeftDoorLockedStatus : 58|1@0+ (1,0) [0|0] "" A_IVC,BLM,VKM
  SG_ PassengerDoorLockedStatus : 59|1@0+ (1,0) [0|0] "" A_IVC,BLM,VKM
  SG_ RES_Failure : 63|3@0+ (1,0) [0|0] "" A_IVC

BO_ 1146 BCM_A113: 8 CGW
  SG_ IgnitionSwitchPosition : 8|1@0+ (1,0) [0|0] "" A_IVC
  SG_ DriverSafetyBeltBuckleState : 11|2@0+ (1,0) [0|0] "" A_IVC
  SG_ ClutchSwitchMinimumTravel : 17|2@0+ (1,0) [0|0] "" A_IVC
  SG_ TailGateStatus : 19|2@0+ (1,0) [0|0] "" A_IVC,BLM
  SG_ VehicleStates : 23|4@0+ (1,0) [0|0] "" A_IVC,BLM,VKM
  SG_ BrakeInfoStatus : 26|3@0+ (1,0) [0|0] "" A_IVC
  SG_ DeliveryModeInformation_v2 : 28|2@0+ (1,0) [0|0] "" A_IVC
  SG_ FlashingIndicatorCommandPosition : 33|2@0+ (1,0) [0|0] "" A_IVC
  SG_ FlashingIndicatorStatus : 36|3@0+ (1,0) [0|0] "" A_IVC
  SG_ GADE_v2 : 39|3@0+ (1,0) [0|0] "" A_IVC,BLM,VKM
  SG_ StopLampDiagnosis : 41|2@0+ (1,0) [0|0] "" A_IVC
  SG_ FrontWiperStatus_BCM : 43|2@0+ (1,0) [0|0] "" A_IVC
  SG_ FrontWipingRequest : 47|3@0+ (1,0) [0|0] "" A_IVC
  SG_ HighBeamRequest : 49|1@0+ (1,0) [0|0] "" A_IVC
  SG_ HighBeamPassingRequest : 50|1@0+ (1,0) [0|0] "" A_IVC
  SG_ THPNumberThermalRequest : 61|3@0+ (1,0) [0|0] "" A_IVC
  SG_ ClutchSwitchMaximumTravel : 63|2@0+ (1,0) [0|0] "" A_IVC

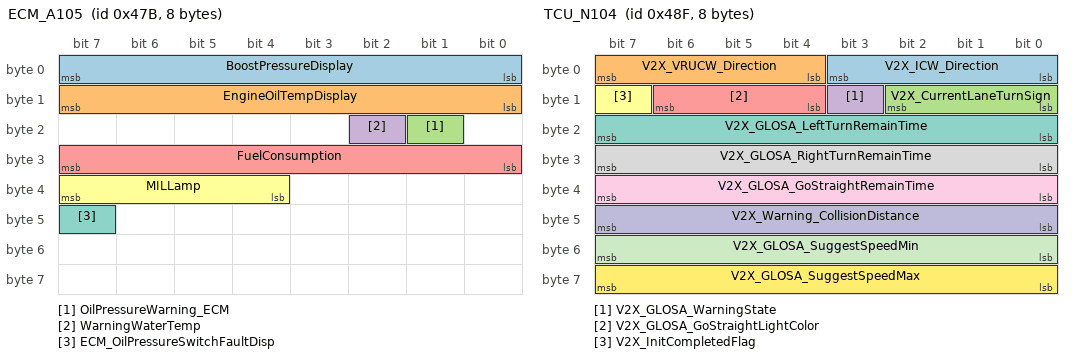
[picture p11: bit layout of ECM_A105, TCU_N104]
BO_ 1147 ECM_A105: 8 CGW
  SG_ BoostPressureDisplay : 7|8@0+ (2,-100) [-100|408] "kPa" A_IVC
  SG_ EngineOilTempDisplay : 15|8@0+ (1,-50) [-50|204] "°C" A_IVC
  SG_ OilPressureWarning_ECM : 17|1@0+ (1,0) [0|0] "" A_IVC
  SG_ WarningWaterTemp : 18|1@0+ (1,0) [0|0] "" A_IVC
  SG_ FuelConsumption : 31|8@0+ (80,0) [0|20400] "mm3" A_IVC
  SG_ MILLamp : 39|4@0+ (1,0) [0|0] "" A_IVC
  SG_ ECM_OilPressureSwitchFaultDisp : 47|1@0+ (1,0) [0|0] "" A_IVC

BO_ 1167 TCU_N104: 8 A_IVC
  SG_ V2X_ICW_Direction : 3|4@0+ (1,0) [0|0] "" CGW
  SG_ V2X_VRUCW_Direction : 7|4@0+ (1,0) [0|0] "" CGW
  SG_ V2X_CurrentLaneTurnSign : 10|3@0+ (1,0) [0|0] "" CGW
  SG_ V2X_GLOSA_WarningState : 11|1@0+ (1,0) [0|0] "" CGW
  SG_ V2X_GLOSA_GoStraightLightColor : 14|3@0+ (1,0) [0|0] "" CGW
  SG_ V2X_InitCompletedFlag : 15|1@0+ (1,0) [0|0] "" CGW
  SG_ V2X_GLOSA_LeftTurnRemainTime : 23|8@0+ (1,0) [0|254] "s" CGW
  SG_ V2X_GLOSA_RightTurnRemainTime : 31|8@0+ (1,0) [0|254] "s" CGW
  SG_ V2X_GLOSA_GoStraightRemainTime : 39|8@0+ (1,0) [0|254] "s" CGW
  SG_ V2X_Warning_CollisionDistance : 47|8@0+ (1,0) [0|254] "m" CGW
  SG_ V2X_GLOSA_SuggestSpeedMin : 55|8@0+ (1,0) [0|254] "km/h" CGW
  SG_ V2X_GLOSA_SuggestSpeedMax : 63|8@0+ (1,0) [0|254] "km/h" CGW

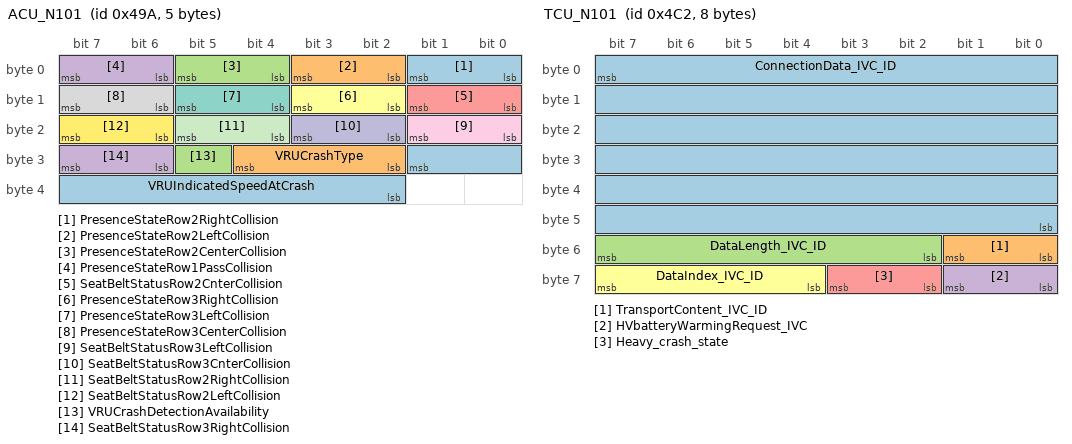
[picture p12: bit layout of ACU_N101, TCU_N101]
BO_ 1178 ACU_N101: 5 CGW
  SG_ PresenceStateRow2RightCollision : 1|2@0+ (1,0) [0|0] "" A_IVC
  SG_ PresenceStateRow2LeftCollision : 3|2@0+ (1,0) [0|0] "" A_IVC
  SG_ PresenceStateRow2CenterCollision : 5|2@0+ (1,0) [0|0] "" A_IVC
  SG_ PresenceStateRow1PassCollision : 7|2@0+ (1,0) [0|0] "" A_IVC
  SG_ SeatBeltStatusRow2CnterCollision : 9|2@0+ (1,0) [0|0] "" A_IVC
  SG_ PresenceStateRow3RightCollision : 11|2@0+ (1,0) [0|0] "" A_IVC
  SG_ PresenceStateRow3LeftCollision : 13|2@0+ (1,0) [0|0] "" A_IVC
  SG_ PresenceStateRow3CenterCollision : 15|2@0+ (1,0) [0|0] "" A_IVC
  SG_ SeatBeltStatusRow3LeftCollision : 17|2@0+ (1,0) [0|0] "" A_IVC
  SG_ SeatBeltStatusRow3CnterCollision : 19|2@0+ (1,0) [0|0] "" A_IVC
  SG_ SeatBeltStatusRow2RightCollision : 21|2@0+ (1,0) [0|0] "" A_IVC
  SG_ SeatBeltStatusRow2LeftCollision : 23|2@0+ (1,0) [0|0] "" A_IVC
  SG_ VRUIndicatedSpeedAtCrash : 25|8@0+ (1,0) [0|200] "km/h" A_IVC
  SG_ VRUCrashType : 28|3@0+ (1,0) [0|0] "" A_IVC
  SG_ VRUCrashDetectionAvailability : 29|1@0+ (1,0) [0|0] "" A_IVC
  SG_ SeatBeltStatusRow3RightCollision : 31|2@0+ (1,0) [0|0] "" A_IVC

BO_ 1182 HEVC_N108: 2 CGW
  SG_ AvailableEnergy_HEVC_v2 : 3|11@0+ (0.1,0) [0|200] "kWh" A_IVC

BO_ 1188 WCBS_N101: 8 CGW
  SG_ NFCframe_NFC_Inside_to_VKM : 7|64@0+ (1,0) [0|0] "" VKM

BO_ 1189 BCM_N101: 8 CGW
  SG_ BCM_Window_SwitchState_FL : 2|3@0+ (1,0) [0|0] "" VKM
  SG_ BCM_Window_SwitchState_FR : 10|3@0+ (1,0) [0|0] "" VKM
  SG_ BCM_Window_SwitchState_RL : 18|3@0+ (1,0) [0|0] "" VKM
  SG_ BCM_Window_SwitchState_RR : 27|3@0+ (1,0) [0|0] "" VKM
  SG_ VK_SSU_SwitchState : 31|4@0+ (1,0) [0|0] "" VKM
  SG_ WindowNormalized_RR : 32|1@0+ (1,0) [0|0] "" VKM
  SG_ WindowNormalized_RL : 33|1@0+ (1,0) [0|0] "" VKM
  SG_ WindowNormalized_FR : 34|1@0+ (1,0) [0|0] "" VKM
  SG_ WindowNormalized_FL : 35|1@0+ (1,0) [0|0] "" VKM
  SG_ UserIdentification_IKeyLink_v2 : 39|4@0+ (1,0) [0|0] "" VKM
  SG_ BCM_Window_ECUDefect_RR : 40|1@0+ (1,0) [0|0] "" VKM
  SG_ BCM_Window_ECUDefect_RL : 41|1@0+ (1,0) [0|0] "" VKM
  SG_ BCM_Window_ECUDefect_FR : 42|1@0+ (1,0) [0|0] "" VKM
  SG_ BCM_Window_ECUDefect_FL : 43|1@0+ (1,0) [0|0] "" VKM
  SG_ WindowThermoprotection_RR : 44|1@0+ (1,0) [0|0] "" VKM
  SG_ WindowThermoprotection_RL : 45|1@0+ (1,0) [0|0] "" VKM
  SG_ WindowThermoprotection_FR : 46|1@0+ (1,0) [0|0] "" VKM
  SG_ WindowThermoprotection_FL : 47|1@0+ (1,0) [0|0] "" VKM
  SG_ VK_SSU_ECUDefect : 48|1@0+ (1,0) [0|0] "" VKM
  SG_ VK_SRU_Normalized : 49|1@0+ (1,0) [0|0] "" VKM
  SG_ VK_SSU_Normalized : 50|1@0+ (1,0) [0|0] "" VKM
  SG_ VK_SSU_Thermoprotection : 51|1@0+ (1,0) [0|0] "" VKM
  SG_ VK_SRU_Thermoprotection : 52|1@0+ (1,0) [0|0] "" VKM

BO_ 1218 TCU_N101: 8 A_IVC
  SG_ ConnectionData_IVC_ID : 7|48@0+ (1,0) [0|0] "" CGW
  SG_ TransportContent_IVC_ID : 49|2@0+ (1,0) [0|0] "" CGW
  SG_ DataLength_IVC_ID : 55|6@0+ (1,0) [0|0] "" CGW
  SG_ HVbatteryWarmingRequest_IVC : 57|2@0+ (1,0) [0|0] "" CGW
  SG_ Heavy_crash_state : 59|2@0+ (1,0) [0|0] "" CGW
  SG_ DataIndex_IVC_ID : 63|4@0+ (1,0) [0|0] "" CGW

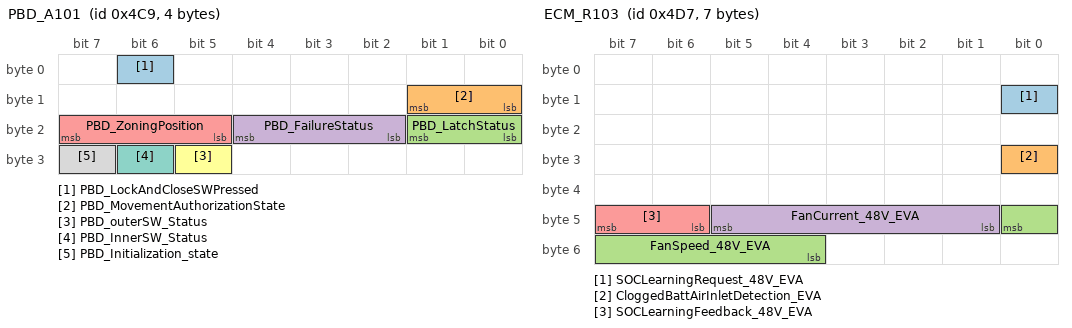
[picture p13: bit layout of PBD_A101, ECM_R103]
BO_ 1225 PBD_A101: 4 CGW
  SG_ PBD_LockAndCloseSWPressed : 6|1@0+ (1,0) [0|0] "" VKM
  SG_ PBD_MovementAuthorizationState : 9|2@0+ (1,0) [0|0] "" VKM
  SG_ PBD_LatchStatus : 17|2@0+ (1,0) [0|0] "" VKM
  SG_ PBD_FailureStatus : 20|3@0+ (1,0) [0|0] "" VKM
  SG_ PBD_ZoningPosition : 23|3@0+ (1,0) [0|0] "" VKM
  SG_ PBD_outerSW_Status : 29|1@0+ (1,0) [0|0] "" VKM
  SG_ PBD_InnerSW_Status : 30|1@0+ (1,0) [0|0] "" VKM
  SG_ PBD_Initialization_state : 31|1@0+ (1,0) [0|0] "" VKM

BO_ 1239 ECM_R103: 7 CGW
  SG_ SOCLearningRequest_48V_EVA : 8|1@0+ (1,0) [0|0] "" A_IVC
  SG_ CloggedBattAirInletDetection_EVA : 24|1@0+ (1,0) [0|0] "" A_IVC
  SG_ FanSpeed_48V_EVA : 40|5@0+ (50,4500) [4500|5500] "rpm" A_IVC
  SG_ FanCurrent_48V_EVA : 45|5@0+ (0.05,0) [0|1] "A" A_IVC
  SG_ SOCLearningFeedback_48V_EVA : 47|2@0+ (1,0) [0|0] "" A_IVC

BO_ 1241 HFM_A9: 1 CGW
  SG_ CustomerIdentType : 7|1@0+ (1,0) [0|0] "" BLM

BO_ 1247 DVR_N103: 7 CGW
  SG_ RecordVideoQuality_HSL : 7|2@0+ (1,0) [0|0] "" A_IVC
  SG_ DVR_CommandRespList_Passenger : 15|5@0+ (1,0) [0|0] "" A_IVC

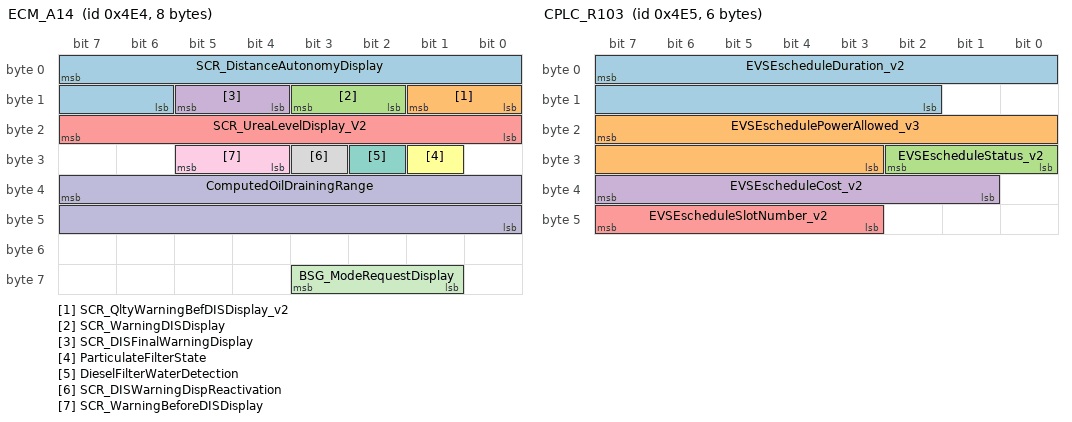
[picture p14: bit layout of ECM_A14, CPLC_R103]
BO_ 1252 ECM_A14: 8 CGW
  SG_ SCR_DistanceAutonomyDisplay : 7|10@0+ (1,0) [0|1022] "km" A_IVC
  SG_ SCR_QltyWarningBefDISDisplay_v2 : 9|2@0+ (1,0) [0|0] "" A_IVC
  SG_ SCR_WarningDISDisplay : 11|2@0+ (1,0) [0|0] "" A_IVC
  SG_ SCR_DISFinalWarningDisplay : 13|2@0+ (1,0) [0|0] "" A_IVC
  SG_ SCR_UreaLevelDisplay_V2 : 23|8@0+ (0.5,0) [0|100] "%" A_IVC
  SG_ ParticulateFilterState : 25|1@0+ (1,0) [0|0] "" A_IVC
  SG_ DieselFilterWaterDetection : 26|1@0+ (1,0) [0|0] "" A_IVC
  SG_ SCR_DISWarningDispReactivation : 27|1@0+ (1,0) [0|0] "" A_IVC
  SG_ SCR_WarningBeforeDISDisplay : 29|2@0+ (1,0) [0|0] "" A_IVC
  SG_ ComputedOilDrainingRange : 39|16@0+ (1,0) [0|65534] "km" A_IVC
  SG_ BSG_ModeRequestDisplay : 59|3@0+ (1,0) [0|0] "" A_IVC

BO_ 1253 CPLC_R103: 6 CGW
  SG_ EVSEscheduleDuration_v2 : 7|14@0+ (10,0) [0|86400] "s" A_IVC
  SG_ EVSEschedulePowerAllowed_v3 : 23|13@0+ (100,0) [0|800000] "W" A_IVC
  SG_ EVSEscheduleStatus_v2 : 26|3@0+ (1,0) [0|0] "" A_IVC
  SG_ EVSEscheduleCost_v2 : 39|7@0+ (1,0) [0|100] "%" A_IVC
  SG_ EVSEscheduleSlotNumber_v2 : 47|5@0+ (1,0) [0|24] "-" A_IVC

BO_ 1255 IVI_N110: 8 CGW
  SG_ IVI_VK_Menu_operation : 20|5@0+ (1,0) [0|0] "" VKM

BO_ 1259 BMS_A104: 4 CGW
  SG_ HVB_ProbeTemp21 : 7|7@0+ (1,-40) [-40|80] "°C" A_IVC
  SG_ HVB_ProbeTemp22 : 15|7@0+ (1,-40) [-40|80] "°C" A_IVC
  SG_ HVB_ProbeTemp23 : 23|7@0+ (1,-40) [-40|80] "°C" A_IVC
  SG_ HVB_ProbeTemp24 : 31|7@0+ (1,-40) [-40|80] "°C" A_IVC

BO_ 1262 IVC_NAV_CARTO_R101: 8 A_IVC
  SG_ CartoData_IVC : 4|61@0+ (1,0) [0|0] "" CGW
  SG_ OSPDataType_IVC : 7|3@0+ (1,0) [0|0] "" CGW

BO_ 1265 HVAC_R101: 1 CGW
  SG_ HeatLoopWaterValveRequest_EVA : 0|1@0+ (1,0) [0|0] "" A_IVC
  SG_ HeatLoopWaterPumpRequest_EVA : 7|7@0+ (1,0) [0|100] "%" A_IVC

BO_ 1269 HEVC_N109: 8 CGW
  SG_ OBMParameter : 7|64@0+ (1,0) [0|0] "" A_IVC

BO_ 1271 HEVC_R134: 4 CGW
  SG_ H2_Consumption_kg100km : 7|10@0+ (0.01,0) [0|10] "Kg/100Km" A_IVC

BO_ 1276 ADAS_A6: 8 CGW
  SG_ DistanceToPrecedingVehicle : 15|11@0+ (0.1,0) [0|150] "m" A_IVC
  SG_ ACC_Status_Slow : 45|4@0+ (1,0) [0|0] "" A_IVC
  SG_ ACC_LCA_DeactivationType : 63|4@0+ (1,0) [0|0] "" A_IVC

BO_ 1277 HEVC_R126: 8 CGW
  SG_ RE_TorqueRequest_HV_EVA : 7|13@0+ (0.1,-300) [-300|500] "Nm" A_IVC
  SG_ CAV_Position_FeedBack_EVA : 10|3@0+ (1,0) [0|0] "" A_IVC
  SG_ HeatLoopWaterTemp_EVA : 23|8@0+ (1,-40) [-40|214] "°C" A_IVC
  SG_ EngineFanSpeedRequestPWM_ECM_EVA : 31|7@0+ (1,0) [0|100] "%" A_IVC
  SG_ DriveLineStatus_EVA : 63|5@0+ (1,0) [0|0] "" A_IVC

BO_ 1279 IVI_A132: 8 CGW
  SG_ SOCPredictedAtQCStation : 63|7@0+ (1,0) [0|100] "%" A_IVC

BO_ 1281 VKM_N110: 8 VKM
  SG_ VKM_Security_Log : 7|64@0+ (1,0) [0|0] "" A_IVC

BO_ 1282 SONAR_A1: 5 CGW
  SG_ FrontParkAssistState : 36|1@0+ (1,0) [0|0] "" A_IVC
  SG_ RearParkAssistState : 37|1@0+ (1,0) [0|0] "" A_IVC

BO_ 1292 IVI_R106: 2 CGW
  SG_ SportUsageRequest2 : 9|2@0+ (1,0) [0|0] "" A_IVC

BO_ 1294 BLM_A102: 1 BLM
  SG_ PersonalDevice_LowBatteryDisplay : 5|1@0+ (1,0) [0|0] "" CGW
  SG_ VirtualKeyMenuState : 7|2@0+ (1,0) [0|0] "" CGW

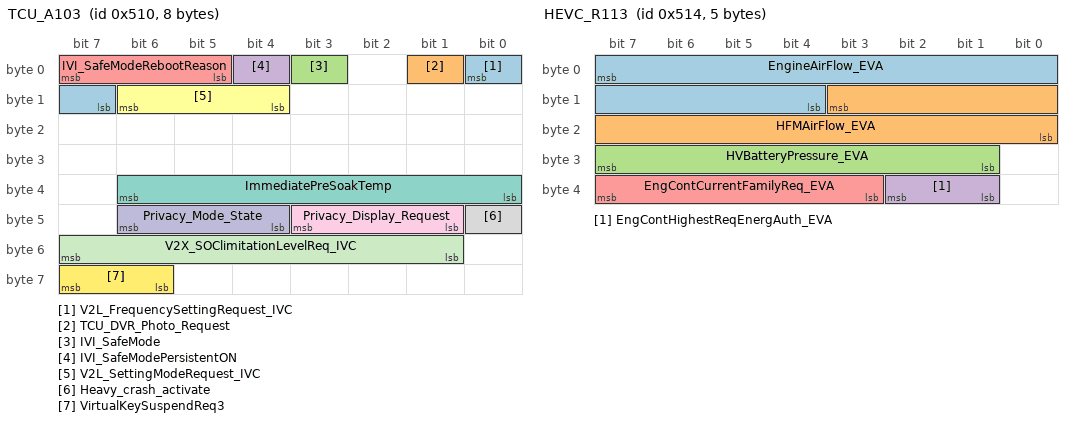
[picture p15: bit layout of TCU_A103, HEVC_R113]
BO_ 1296 TCU_A103: 8 A_IVC
  SG_ V2L_FrequencySettingRequest_IVC : 0|2@0+ (1,0) [0|0] "" CGW
  SG_ TCU_DVR_Photo_Request : 1|1@0+ (1,0) [0|0] "" CGW
  SG_ IVI_SafeMode : 3|1@0+ (1,0) [0|0] "" CGW
  SG_ IVI_SafeModePersistentON : 4|1@0+ (1,0) [0|0] "" CGW
  SG_ IVI_SafeModeRebootReason : 7|3@0+ (1,0) [0|0] "" CGW
  SG_ V2L_SettingModeRequest_IVC : 14|3@0+ (1,0) [0|0] "" CGW
  SG_ ImmediatePreSoakTemp : 38|7@0+ (0.5,16) [16|32] "°C" CGW
  SG_ Heavy_crash_activate : 40|1@0+ (1,0) [0|0] "" CGW
  SG_ Privacy_Display_Request : 43|3@0+ (1,0) [0|0] "" CGW
  SG_ Privacy_Mode_State : 46|3@0+ (1,0) [0|0] "" CGW
  SG_ V2X_SOClimitationLevelReq_IVC : 55|7@0+ (1,0) [0|100] "%" CGW
  SG_ VirtualKeySuspendReq3 : 63|2@0+ (1,0) [0|0] "" BLM

BO_ 1300 HEVC_R113: 5 CGW
  SG_ EngineAirFlow_EVA : 7|12@0+ (0.1,0) [0|300] "g/s" A_IVC
  SG_ HFMAirFlow_EVA : 11|12@0+ (0.1,0) [0|300] "g/s" A_IVC
  SG_ HVBatteryPressure_EVA : 31|7@0+ (10,500) [500|1500] "mBar" A_IVC
  SG_ EngContHighestReqEnergAuth_EVA : 34|2@0+ (1,0) [0|0] "" A_IVC
  SG_ EngContCurrentFamilyReq_EVA : 39|5@0+ (1,0) [0|0] "" A_IVC

BO_ 1301 RemoteFunctionService_HFM_to_BLM_Frame: 8 CGW
  SG_ RemoteFunctionService_HFM_to_BLM : 7|64@0+ (1,0) [0|0] "" BLM

BO_ 1302 RemoteFunctionService_BLM_to_HFM_Frame: 8 BLM
  SG_ RemoteFunctionService_BLM_to_HFM : 7|64@0+ (1,0) [0|0] "" CGW

BO_ 1303 FRCAMERA_A2: 8 CGW
  SG_ OverSpeedWarningSound : 0|1@0+ (1,0) [0|0] "" A_IVC
  SG_ TSR_OSP_SpeedSignalZone1 : 23|8@0+ (1,0) [0|200] "wu" A_IVC
  SG_ TSR_OSP_SpeedSignalZone2 : 31|8@0+ (1,0) [0|200] "wu" A_IVC
  SG_ OSPOverSpeedDisplayRequest : 47|1@0+ (1,0) [0|0] "" A_IVC
  SG_ TSR_OSP_FailureDisplay : 49|2@0+ (1,0) [0|0] "" A_IVC

BO_ 1305 ECM_A125: 8 CGW
  SG_ BattCoolingLoopTemperature_48V : 7|8@0+ (1,-50) [-50|130] "°C" A_IVC
  SG_ BatteryTemperatureMin_48V : 16|7@0+ (1,-40) [-40|80] "°C" A_IVC
  SG_ BatteryTemperatureMax_48V : 23|7@0+ (1,-40) [-40|80] "°C" A_IVC

BO_ 1306 HFM_BLM_pairing_Frame: 8 CGW
  SG_ HFM_BLM_pairing : 7|64@0+ (1,0) [0|0] "" BLM

BO_ 1308 BLM_HFM_pairing_Frame: 8 BLM
  SG_ BLM_HFM_pairing : 7|64@0+ (1,0) [0|0] "" CGW

BO_ 1315 BCM_A8: 3 CGW
  SG_ AbsoluteTimeSince1rstIgnition : 7|24@0+ (1,0) [0|1.677E7] "min" A_IVC,VKM

BO_ 1316 HEVC_A41: 7 CGW
  SG_ UserSOC_BMS : 47|13@0+ (0.02,0) [0|100] "%" A_IVC

BO_ 1319 ADAS_N101: 7 CGW
  SG_ DMC_AlertStatus : 39|2@0+ (1,0) [0|0] "" A_IVC

BO_ 1326 ACU_A103: 1 CGW
  SG_ SmallCrash_Impact : 7|3@0+ (1,0) [0|0] "" A_IVC

BO_ 1328 HEVC_A167: 8 CGW
  SG_ ME_ElecMaxMotorTorque_BLMS_v2 : 7|10@0+ (1,-300) [-300|500] "Nm" A_IVC
  SG_ ME_ElecTorqueEstimation_BLMS_v2 : 13|10@0+ (1,-300) [-300|500] "Nm" A_IVC
  SG_ ME_ElecMaxGenTorque_BLMS_v2 : 19|9@0+ (1,0) [0|500] "Nm" A_IVC
  SG_ ME_TorqueRequest_BLMS_v2 : 26|9@0+ (2,-300) [-300|500] "Nm" A_IVC

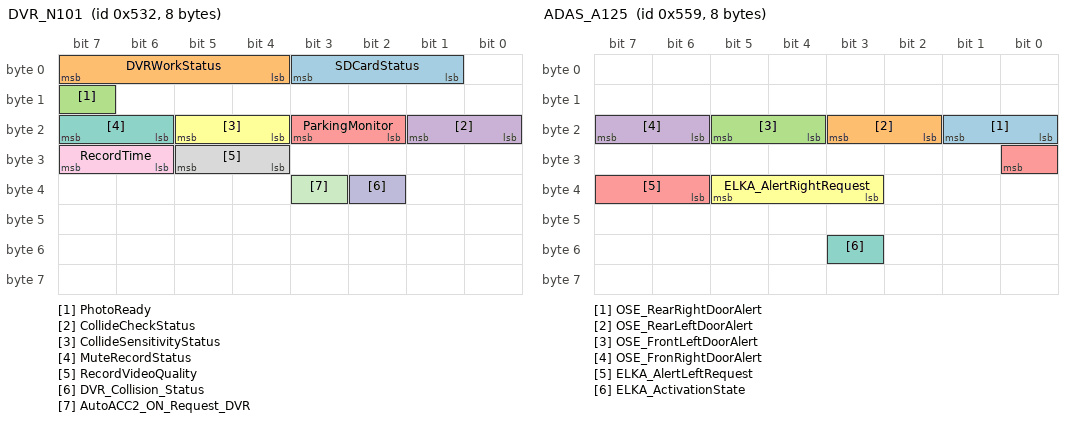
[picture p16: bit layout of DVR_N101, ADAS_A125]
BO_ 1330 DVR_N101: 8 CGW
  SG_ SDCardStatus : 3|3@0+ (1,0) [0|0] "" A_IVC
  SG_ DVRWorkStatus : 7|4@0+ (1,0) [0|0] "" A_IVC
  SG_ PhotoReady : 15|1@0+ (1,0) [0|0] "" A_IVC
  SG_ CollideCheckStatus : 17|2@0+ (1,0) [0|0] "" A_IVC
  SG_ ParkingMonitor : 19|2@0+ (1,0) [0|0] "" A_IVC
  SG_ CollideSensitivityStatus : 21|2@0+ (1,0) [0|0] "" A_IVC
  SG_ MuteRecordStatus : 23|2@0+ (1,0) [0|0] "" A_IVC
  SG_ RecordVideoQuality : 29|2@0+ (1,0) [0|0] "" A_IVC
  SG_ RecordTime : 31|2@0+ (1,0) [0|0] "" A_IVC
  SG_ DVR_Collision_Status : 34|1@0+ (1,0) [0|0] "" A_IVC
  SG_ AutoACC2_ON_Request_DVR : 35|1@0+ (1,0) [0|0] "" A_IVC

BO_ 1331 DVR_N2: 4 CGW
  SG_ DVR_CommandResult : 2|3@0+ (1,0) [0|0] "" A_IVC
  SG_ DVR_CommandRespList_2 : 29|5@0+ (1,0) [0|0] "" A_IVC
  SG_ DVR_RemoteCommandResult : 31|2@0+ (1,0) [0|0] "" A_IVC

BO_ 1332 ACU_A101: 8 CGW
  SG_ AIRBAGMalfunction : 8|1@0+ (1,0) [0|0] "" A_IVC
  SG_ CrashDetectionOutOfOrder_v2 : 20|2@0+ (1,0) [0|0] "" A_IVC
  SG_ CrashDetected_v2 : 22|2@0+ (1,0) [0|0] "" A_IVC
  SG_ SecondRowCenterPresenceState : 26|2@0+ (1,0) [0|0] "" A_IVC
  SG_ RolloverDetectionMalfunction : 27|1@0+ (1,0) [0|0] "" A_IVC
  SG_ PassengerSafetyBeltBuckleState : 29|2@0+ (1,0) [0|0] "" A_IVC
  SG_ PassengerPresenceState : 31|2@0+ (1,0) [0|0] "" A_IVC
  SG_ SecondRowRightPresenceState : 33|2@0+ (1,0) [0|0] "" A_IVC
  SG_ SecondRowLeftSafetyBeltState : 35|2@0+ (1,0) [0|0] "" A_IVC
  SG_ SecondRowLeftPresenceState : 37|2@0+ (1,0) [0|0] "" A_IVC
  SG_ SecondRowCenterSafetyBeltState : 39|2@0+ (1,0) [0|0] "" A_IVC
  SG_ ThirdRowLeftPresenceState : 41|2@0+ (1,0) [0|0] "" A_IVC
  SG_ ThirdRowCenterSafetyBeltState : 43|2@0+ (1,0) [0|0] "" A_IVC
  SG_ ThirdRowCenterPresenceState : 45|2@0+ (1,0) [0|0] "" A_IVC
  SG_ SecondRowRightSafetyBeltState : 47|2@0+ (1,0) [0|0] "" A_IVC
  SG_ FirstRowCenterPresenceState : 49|2@0+ (1,0) [0|0] "" A_IVC
  SG_ ThirdRowRightSafetyBeltState : 51|2@0+ (1,0) [0|0] "" A_IVC
  SG_ ThirdRowRightPresenceState : 53|2@0+ (1,0) [0|0] "" A_IVC
  SG_ ThirdRowLeftSafetyBeltState : 55|2@0+ (1,0) [0|0] "" A_IVC
  SG_ PassengerAIRBAG_Inhibition_v2 : 61|2@0+ (1,0) [0|0] "" A_IVC
  SG_ FirstRowCenterSafetyBeltState : 63|2@0+ (1,0) [0|0] "" A_IVC

BO_ 1339 TIME_R1: 8 CGW
  SG_ TimeHour : 7|5@0+ (1,0) [0|23] "h" A_IVC
  SG_ TimeMinute : 15|6@0+ (1,0) [0|59] "min" A_IVC
  SG_ TimeWeekDay : 42|3@0+ (1,0) [0|0] "" A_IVC

BO_ 1343 HEVC_A110: 4 CGW
  SG_ HEVC_PresoakRequest : 6|2@0+ (1,0) [0|0] "" A_IVC
  SG_ V2L_InstantPower : 23|7@0+ (0.1,0) [0|12] "kW" A_IVC

BO_ 1345 FrCamADAS_R112: 8 CGW
  SG_ ISA_ActivationDuration : 7|16@0+ (1,0) [0|43200] "s" A_IVC
  SG_ ISA_SpeedLimitNoSoundRatio : 23|10@0+ (0.1,0) [0|100] "-" A_IVC
  SG_ ISA_SpeedLimitSoundRatio : 29|10@0+ (0.1,0) [0|100] "-" A_IVC
  SG_ ISA_ReportingDistance : 47|18@0+ (1,0) [0|200000] "Km" A_IVC

BO_ 1349 TCU_R102: 3 A_IVC
  SG_ PnCcertifInstallTrigger : 2|4@0+ (1,0) [0|15] "-" CGW
  SG_ PnCactivationRequest_IVC : 4|2@0+ (1,0) [0|0] "" CGW
  SG_ LastReceivedSetOBMCpt : 10|11@0+ (1,0) [0|2047] "wu" CGW

BO_ 1354 PSD_A102: 4 CGW
  SG_ PSD_R_ActivationState : 4|3@0+ (1,0) [0|0] "" VKM

BO_ 1358 HEVC_R131: 8 CGW
  SG_ V2G_TotalChargedEnergy_EVA : 7|15@0+ (5,0) [0|150000] "KWh" A_IVC
  SG_ V2L_TotalDischargedEnergy_EVA : 23|15@0+ (5,0) [0|150000] "KWh" A_IVC
  SG_ ME_PwtThermalControlRequest_EVA : 33|3@0+ (1,0) [0|0] "" A_IVC
  SG_ ME_OilPumpSpeed_EVA : 39|6@0+ (100,0) [0|6300] "rpm" A_IVC

BO_ 1367 TCU_N105: 6 A_IVC
  SG_ V2X_ID8_CLW_ActivationState : 0|1@0+ (1,0) [0|0] "" CGW
  SG_ V2X_Warning_VehicleType : 3|3@0+ (1,0) [0|0] "" CGW
  SG_ V2X_LTA_WarningState : 4|1@0+ (1,0) [0|0] "" CGW
  SG_ V2X_ICW_WarningState : 5|1@0+ (1,0) [0|0] "" CGW
  SG_ V2X_CLW_WarningState : 6|1@0+ (1,0) [0|0] "" CGW
  SG_ V2X_FCW_WarningState : 7|1@0+ (1,0) [0|0] "" CGW
  SG_ V2X_ID12_VRUCW_ActivationState : 8|1@0+ (1,0) [0|0] "" CGW
  SG_ V2X_ID11_RLVW_ActivationState : 9|1@0+ (1,0) [0|0] "" CGW
  SG_ V2X_CLW_ControlLossType : 12|3@0+ (1,0) [0|0] "" CGW
  SG_ V2X_RLVW_WarningState : 13|1@0+ (1,0) [0|0] "" CGW
  SG_ V2X_VRUCW_WarningState : 14|1@0+ (1,0) [0|0] "" CGW
  SG_ V2X_AVW_WarningState : 15|1@0+ (1,0) [0|0] "" CGW
  SG_ V2X_MalfunctionState : 16|1@0+ (1,0) [0|0] "" CGW
  SG_ V2X_ID16_GLOSA_ActivationState : 17|1@0+ (1,0) [0|0] "" CGW
  SG_ V2X_ID7_AVW_ActivationState : 18|1@0+ (1,0) [0|0] "" CGW
  SG_ V2X_ID3_LTA_ActivationState : 19|1@0+ (1,0) [0|0] "" CGW
  SG_ V2X_ID2_ICW_ActivationState : 20|1@0+ (1,0) [0|0] "" CGW
  SG_ V2X_ID1_FCW_ActivationState : 21|1@0+ (1,0) [0|0] "" CGW
  SG_ V2X_VRUCW_UserType : 23|2@0+ (1,0) [0|0] "" CGW
  SG_ V2X_SubFunctionSwitchState : 31|8@0+ (1,0) [0|0] "" CGW
  SG_ PnCContCertifInstMng : 36|5@0+ (1,0) [0|0] "" CGW
  SG_ V2X_GLOSA_LeftTurnLightColor : 39|3@0+ (1,0) [0|0] "" CGW
  SG_ V2X_GLOSA_RightTurnLightColor : 42|3@0+ (1,0) [0|0] "" CGW
  SG_ V2X_MainFunctionSwitchState : 43|1@0+ (1,0) [0|0] "" CGW
  SG_ PnCProV2GCertifInstMng : 47|4@0+ (1,0) [0|0] "" CGW

BO_ 1369 ADAS_A125: 8 CGW
  SG_ OSE_RearRightDoorAlert : 17|2@0+ (1,0) [0|0] "" A_IVC
  SG_ OSE_RearLeftDoorAlert : 19|2@0+ (1,0) [0|0] "" A_IVC
  SG_ OSE_FrontLeftDoorAlert : 21|2@0+ (1,0) [0|0] "" A_IVC
  SG_ OSE_FronRightDoorAlert : 23|2@0+ (1,0) [0|0] "" A_IVC
  SG_ ELKA_AlertLeftRequest : 24|3@0+ (1,0) [0|0] "" A_IVC
  SG_ ELKA_AlertRightRequest : 37|3@0+ (1,0) [0|0] "" A_IVC
  SG_ ELKA_ActivationState : 51|1@0+ (1,0) [0|0] "" A_IVC

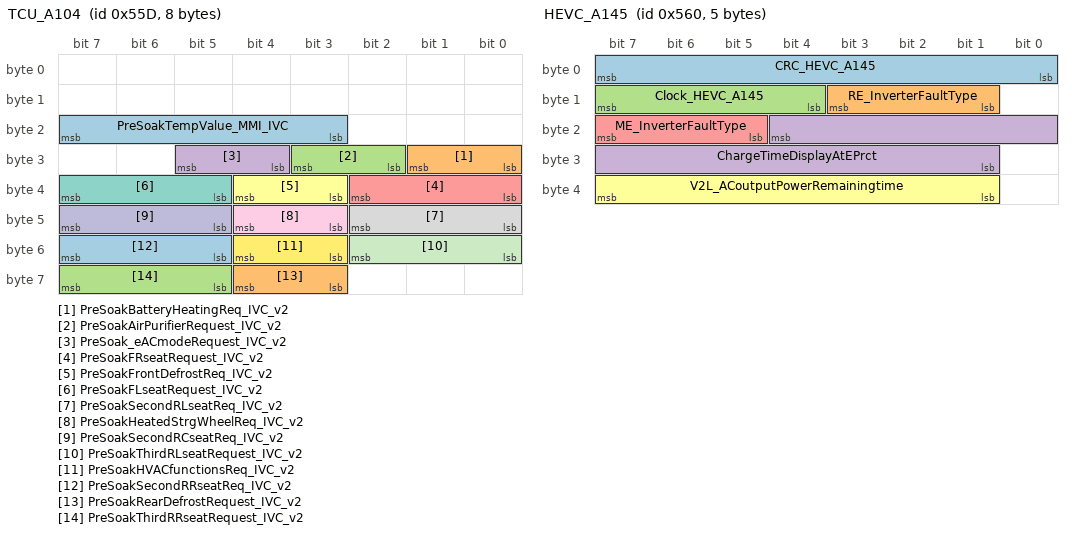
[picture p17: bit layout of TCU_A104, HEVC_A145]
BO_ 1373 TCU_A104: 8 A_IVC
  SG_ PreSoakTempValue_MMI_IVC : 23|5@0+ (0.5,16) [16|32] "°C" CGW
  SG_ PreSoakBatteryHeatingReq_IVC_v2 : 25|2@0+ (1,0) [0|0] "" CGW
  SG_ PreSoakAirPurifierRequest_IVC_v2 : 27|2@0+ (1,0) [0|0] "" CGW
  SG_ PreSoak_eACmodeRequest_IVC_v2 : 29|2@0+ (1,0) [0|0] "" CGW
  SG_ PreSoakFRseatRequest_IVC_v2 : 34|3@0+ (1,0) [0|0] "" CGW
  SG_ PreSoakFrontDefrostReq_IVC_v2 : 36|2@0+ (1,0) [0|0] "" CGW
  SG_ PreSoakFLseatRequest_IVC_v2 : 39|3@0+ (1,0) [0|0] "" CGW
  SG_ PreSoakSecondRLseatReq_IVC_v2 : 42|3@0+ (1,0) [0|0] "" CGW
  SG_ PreSoakHeatedStrgWheelReq_IVC_v2 : 44|2@0+ (1,0) [0|0] "" CGW
  SG_ PreSoakSecondRCseatReq_IVC_v2 : 47|3@0+ (1,0) [0|0] "" CGW
  SG_ PreSoakThirdRLseatRequest_IVC_v2 : 50|3@0+ (1,0) [0|0] "" CGW
  SG_ PreSoakHVACfunctionsReq_IVC_v2 : 52|2@0+ (1,0) [0|0] "" CGW
  SG_ PreSoakSecondRRseatReq_IVC_v2 : 55|3@0+ (1,0) [0|0] "" CGW
  SG_ PreSoakRearDefrostRequest_IVC_v2 : 60|2@0+ (1,0) [0|0] "" CGW
  SG_ PreSoakThirdRRseatRequest_IVC_v2 : 63|3@0+ (1,0) [0|0] "" CGW

BO_ 1374 BMS_R3: 2 CGW
  SG_ HVB_Cell116Voltage : 7|12@0+ (0.001,2) [2|4.6] "V" A_IVC

BO_ 1376 HEVC_A145: 5 CGW
  SG_ CRC_HEVC_A145 : 7|8@0+ (1,0) [0|255] "" A_IVC
  SG_ RE_InverterFaultType : 11|3@0+ (1,0) [0|0] "" A_IVC
  SG_ Clock_HEVC_A145 : 15|4@0+ (1,0) [0|15] "" A_IVC
  SG_ ChargeTimeDisplayAtEPrct : 20|12@0+ (1,0) [1|4094] "min" A_IVC
  SG_ ME_InverterFaultType : 23|3@0+ (1,0) [0|0] "" A_IVC
  SG_ V2L_ACoutputPowerRemainingtime : 39|7@0+ (0.1,0) [0|10] "kW" A_IVC

BO_ 1380 METER_A106: 8 CGW
  SG_ TripAverageConsumption : 7|10@0+ (0.1,0) [0|102.3] "" A_IVC
  SG_ TripUnitConsumption : 10|3@0+ (1,0) [0|0] "" A_IVC
  SG_ TripUnitDistance : 13|2@0+ (1,0) [0|0] "" A_IVC
  SG_ TripDistance : 31|17@0+ (0.1,0) [0|13107.1] "" A_IVC

BO_ 1381 SRRR_A106: 6 CGW
  SG_ CTA_AlertStatus : 7|2@0+ (1,0) [0|0] "" A_IVC

BO_ 1384 IVI_A123: 8 CGW
  SG_ MexModeState_v3 : 3|4@0+ (1,0) [0|0] "" A_IVC

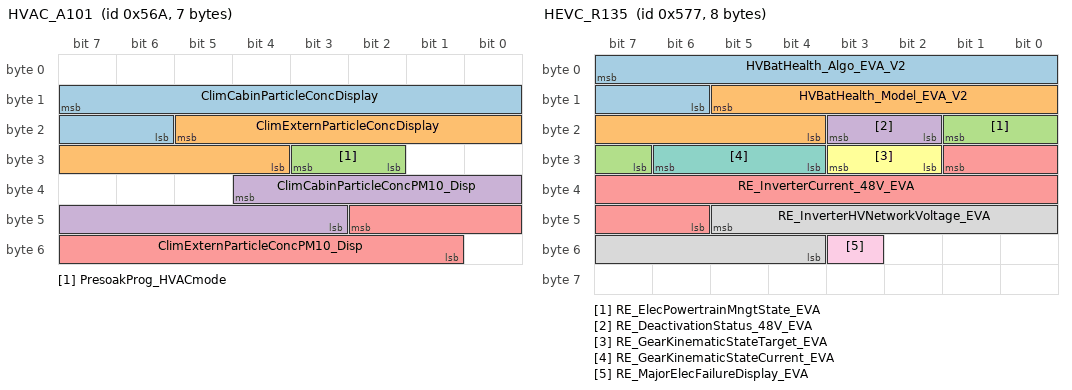
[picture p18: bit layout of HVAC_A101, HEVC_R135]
BO_ 1386 HVAC_A101: 7 CGW
  SG_ ClimCabinParticleConcDisplay : 15|10@0+ (5,0) [0|4095] "µg/m3" A_IVC
  SG_ ClimExternParticleConcDisplay : 21|10@0+ (5,0) [0|4095] "µg/m3" A_IVC
  SG_ PresoakProg_HVACmode : 27|2@0+ (1,0) [0|0] "" A_IVC
  SG_ ClimCabinParticleConcPM10_Disp : 36|10@0+ (5,0) [0|4095] "µg/m3" A_IVC
  SG_ ClimExternParticleConcPM10_Disp : 42|10@0+ (5,0) [0|4095] "µg/m3" A_IVC

BO_ 1390 HEVC_A148: 8 CGW
  SG_ CumulatedBalancingTime : 7|15@0+ (1,0) [0|32000] "h" A_IVC
  SG_ BusbarUnscrewingAlert : 8|1@0+ (1,0) [0|0] "" A_IVC
  SG_ CumulatedCapacityBalanced : 23|9@0+ (1,0) [0|500] "Ah" A_IVC
  SG_ NumACsmartcharging_BLMS : 42|10@0+ (10,0) [0|10000] "" A_IVC
  SG_ AccumulatedCurrentCharge_BLMS : 48|9@0+ (1,0) [0|500] "Ah" A_IVC

BO_ 1392 IVI_A119: 8 CGW
  SG_ IVI_SafeModeAck : 48|1@0+ (1,0) [0|0] "" A_IVC
  SG_ WDA_ActivationRequest2 : 50|2@0+ (1,0) [0|0] "" A_IVC
  SG_ VirtualKeySuspendReq2 : 57|2@0+ (1,0) [0|0] "" BLM

BO_ 1395 HEVC_A137: 6 CGW
  SG_ ePedalModeDisplayRequest : 11|1@0+ (1,0) [0|0] "" A_IVC

BO_ 1398 HEVC_A155: 7 CGW
  SG_ ChargingStationComType : 11|3@0+ (1,0) [0|0] "" A_IVC
  SG_ V2G_ActivationState : 51|3@0+ (1,0) [0|0] "" A_IVC

BO_ 1399 HEVC_R135: 8 CGW
  SG_ HVBatHealth_Algo_EVA_V2 : 7|10@0+ (0.1,0) [0|100] "%" A_IVC
  SG_ HVBatHealth_Model_EVA_V2 : 13|10@0+ (0.1,0) [0|100] "%" A_IVC
  SG_ RE_ElecPowertrainMngtState_EVA : 17|3@0+ (1,0) [0|0] "" A_IVC
  SG_ RE_DeactivationStatus_48V_EVA : 19|2@0+ (1,0) [0|0] "" A_IVC
  SG_ RE_InverterCurrent_48V_EVA : 25|12@0+ (0.5,-1023) [-1023|1024] "A" A_IVC
  SG_ RE_GearKinematicStateTarget_EVA : 27|2@0+ (1,0) [0|0] "" A_IVC
  SG_ RE_GearKinematicStateCurrent_EVA : 30|3@0+ (1,0) [0|0] "" A_IVC
  SG_ RE_InverterHVNetworkVoltage_EVA : 45|10@0+ (0.1,0) [0|80] "V" A_IVC
  SG_ RE_MajorElecFailureDisplay_EVA : 51|1@0+ (1,0) [0|0] "" A_IVC

BO_ 1402 ADAS_A103: 8 CGW
  SG_ LDW_SensibilityState : 29|2@0+ (1,0) [0|0] "" A_IVC
  SG_ LDW_ActivationState_v3 : 31|2@0+ (1,0) [0|0] "" A_IVC
  SG_ LDW_StatusDisplay_v2 : 45|3@0+ (1,0) [0|0] "" A_IVC
  SG_ EcallRequest : 46|1@0+ (1,0) [0|0] "" A_IVC

BO_ 1405 AVM_N104: 7 CGW
  SG_ RPK_RegistAddress1 : 7|48@0+ (1,0) [0|2.81474976710655E14] "-" VKM
  SG_ RPK_VKActivateRequest : 53|1@0+ (1,0) [0|0] "" VKM
  SG_ RPK_ModeRequest : 55|2@0+ (1,0) [0|0] "" VKM

BO_ 1408 HEVC_R111: 3 CGW
  SG_ RecoverySinceMissionStart : 7|10@0+ (0.1,0) [0|100] "kWh" A_IVC
  SG_ HVNetworkVoltage : 13|9@0+ (1,0) [0|500] "V" A_IVC

BO_ 1415 IVI_R101: 5 CGW
  SG_ FAPK_SelectedManeuverTypeRequest : 6|3@0+ (1,0) [0|0] "" A_IVC
  SG_ Distract_ShieldActivationState2 : 16|1@0+ (1,0) [0|0] "" A_IVC
  SG_ AVM_LayoutDisplayRequest_3 : 28|5@0+ (1,0) [0|0] "" A_IVC
  SG_ Fatigue_ShieldActivationState2 : 29|1@0+ (1,0) [0|0] "" A_IVC
  SG_ AVM_LayoutVideoStatus_3 : 39|5@0+ (1,0) [0|0] "" A_IVC

BO_ 1422 DSMU_A102: 5 CGW
  SG_ MC_ActivationState : 3|1@0+ (1,0) [0|0] "" A_IVC
  SG_ MC_TutorialState : 19|1@0+ (1,0) [0|0] "" A_IVC

BO_ 1435 HEVC_A31: 8 CGW
  SG_ HSG_InverterTemp_BLMS : 7|13@0+ (0.02,0) [0|100] "%" A_IVC
  SG_ HSG_ElecMachineTemp_BLMS : 10|13@0+ (0.02,0) [0|100] "%" A_IVC
  SG_ HVIsolationImpedance_BLMS : 35|14@0+ (100,0) [0|1000000] "Ohm" A_IVC
  SG_ HVBatHealth_BLMS_V3 : 53|11@0+ (0.1,0) [0|126] "%" A_IVC

BO_ 1436 HFP_R5: 6 CGW
  SG_ HFP_SelectedManeuverType : 11|3@0+ (1,0) [0|0] "" A_IVC
  SG_ HFP_DefaultManeuverType : 14|3@0+ (1,0) [0|0] "" A_IVC
  SG_ HFP_MapContentDisplay : 31|3@0+ (1,0) [0|0] "" A_IVC
  SG_ HFP_ExtendedInstrContentDisplay : 36|5@0+ (1,0) [0|0] "" A_IVC

BO_ 1439 HEVC_A133: 7 CGW
  SG_ InstantChargingApparentPower : 28|12@0+ (0.1,0) [0|400] "kW" A_IVC

BO_ 1441 BMS_A28: 8 CGW
  SG_ HVB_Cell91Voltage : 7|12@0+ (0.001,2) [2|4.6] "V" A_IVC
  SG_ HVB_Cell92Voltage : 11|12@0+ (0.001,2) [2|4.6] "V" A_IVC
  SG_ HVB_Cell93Voltage : 31|12@0+ (0.001,2) [2|4.6] "V" A_IVC
  SG_ HVB_Cell94Voltage : 35|12@0+ (0.001,2) [2|4.6] "V" A_IVC
  SG_ HVB_Cell95Voltage : 55|12@0+ (0.001,2) [2|4.6] "V" A_IVC

BO_ 1443 HEVC_R104: 8 CGW
  SG_ AuxConsumption_LastTrip : 7|12@0+ (0.1,0) [0|409.4] "kWh" A_IVC
  SG_ AverageConsumptionZEV_LastTrip : 11|10@0+ (0.1,0) [0|102.2] "" A_IVC
  SG_ VehicleAutonomyZEVdisplay : 17|10@0+ (1,0) [0|1022] "wu" A_IVC
  SG_ VehicleAutonomyHEVdisplay : 49|10@0+ (1,0) [0|1022] "" A_IVC

BO_ 1446 BMS_R1: 8 CGW
  SG_ HVB_Cell106Voltage : 7|12@0+ (0.001,2) [2|4.6] "V" A_IVC
  SG_ HVB_Cell107Voltage : 11|12@0+ (0.001,2) [2|4.6] "V" A_IVC
  SG_ HVB_Cell108Voltage : 31|12@0+ (0.001,2) [2|4.6] "V" A_IVC
  SG_ HVB_Cell109Voltage : 35|12@0+ (0.001,2) [2|4.6] "V" A_IVC
  SG_ HVB_Cell110Voltage : 55|12@0+ (0.001,2) [2|4.6] "V" A_IVC

BO_ 1452 BMS_A26: 8 CGW
  SG_ HVB_Cell81Voltage : 7|12@0+ (0.001,2) [2|4.6] "V" A_IVC
  SG_ HVB_Cell82Voltage : 11|12@0+ (0.001,2) [2|4.6] "V" A_IVC
  SG_ HVB_Cell83Voltage : 31|12@0+ (0.001,2) [2|4.6] "V" A_IVC
  SG_ HVB_Cell84Voltage : 35|12@0+ (0.001,2) [2|4.6] "V" A_IVC
  SG_ HVB_Cell85Voltage : 55|12@0+ (0.001,2) [2|4.6] "V" A_IVC

BO_ 1453 BMS_A27: 8 CGW
  SG_ HVB_Cell86Voltage : 7|12@0+ (0.001,2) [2|4.6] "V" A_IVC
  SG_ HVB_Cell87Voltage : 11|12@0+ (0.001,2) [2|4.6] "V" A_IVC
  SG_ HVB_Cell88Voltage : 31|12@0+ (0.001,2) [2|4.6] "V" A_IVC
  SG_ HVB_Cell89Voltage : 35|12@0+ (0.001,2) [2|4.6] "V" A_IVC
  SG_ HVB_Cell90Voltage : 55|12@0+ (0.001,2) [2|4.6] "V" A_IVC

BO_ 1454 USM_A104: 4 CGW
  SG_ BatteryTemperature : 7|7@0+ (1,-40) [-40|80] "°C" A_IVC
  SG_ BatteryDiagnosisDeltaU : 10|9@0+ (0.05,0) [0|17] "V" A_IVC
  SG_ BatteryUminByPulse : 17|9@0+ (0.05,0) [0|17] "V" A_IVC

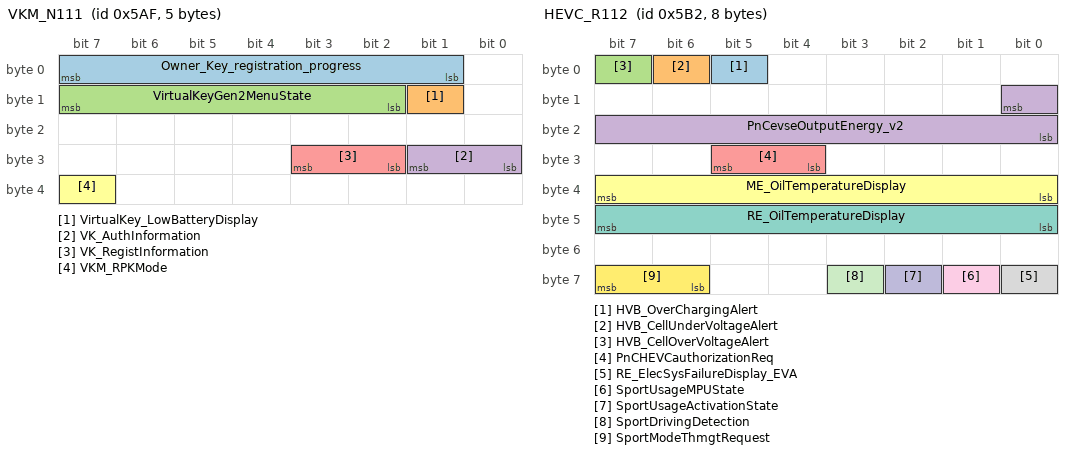
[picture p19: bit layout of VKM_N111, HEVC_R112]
BO_ 1455 VKM_N111: 5 VKM
  SG_ Owner_Key_registration_progress : 7|7@0+ (1,0) [0|100] "wu" CGW
  SG_ VirtualKey_LowBatteryDisplay : 9|1@0+ (1,0) [0|0] "" CGW
  SG_ VirtualKeyGen2MenuState : 15|6@0+ (1,0) [0|0] "" CGW
  SG_ VK_AuthInformation : 25|2@0+ (1,0) [0|0] "" CGW
  SG_ VK_RegistInformation : 27|2@0+ (1,0) [0|0] "" CGW
  SG_ VKM_RPKMode : 39|1@0+ (1,0) [0|0] "" CGW

BO_ 1456 HEVC_A126: 8 CGW
  SG_ HSG_InverterCurrent_BLMS_v2 : 7|12@0+ (0.5,-550) [-550|550] "A" A_IVC
  SG_ RE_InverterCurrent_BLMS : 11|12@0+ (0.5,-550) [-550|550] "A" A_IVC
  SG_ HVbatInstantCurrent_BLMS_v2 : 31|15@0+ (0.125,-1200) [-1200|1200] "A" A_IVC
  SG_ ElecBrakeWheelTorqueRequest_EVA : 32|13@0+ (1,0) [0|8190] "Nm" A_IVC
  SG_ State_of_ImmediateChargingSW : 56|1@0+ (1,0) [0|0] "" A_IVC

BO_ 1458 HEVC_R112: 8 CGW
  SG_ HVB_OverChargingAlert : 5|1@0+ (1,0) [0|0] "" A_IVC
  SG_ HVB_CellUnderVoltageAlert : 6|1@0+ (1,0) [0|0] "" A_IVC
  SG_ HVB_CellOverVoltageAlert : 7|1@0+ (1,0) [0|0] "" A_IVC
  SG_ PnCevseOutputEnergy_v2 : 8|9@0+ (0.5,0) [0|150] "kWh" A_IVC
  SG_ PnCHEVCauthorizationReq : 29|2@0+ (1,0) [0|0] "" A_IVC
  SG_ ME_OilTemperatureDisplay : 39|8@0+ (1,-40) [-40|150] "°C" A_IVC
  SG_ RE_OilTemperatureDisplay : 47|8@0+ (1,-40) [-40|150] "°C" A_IVC
  SG_ RE_ElecSysFailureDisplay_EVA : 56|1@0+ (1,0) [0|0] "" A_IVC
  SG_ SportUsageMPUState : 57|1@0+ (1,0) [0|0] "" A_IVC
  SG_ SportUsageActivationState : 58|1@0+ (1,0) [0|0] "" A_IVC
  SG_ SportDrivingDetection : 59|1@0+ (1,0) [0|0] "" A_IVC
  SG_ SportModeThmgtRequest : 63|2@0+ (1,0) [0|0] "" A_IVC

BO_ 1459 AVM_A1: 4 CGW
  SG_ AVM_LayoutVideoStatus : 20|5@0+ (1,0) [0|0] "" A_IVC
  SG_ AVM_LayoutDisplayRequest : 31|5@0+ (1,0) [0|0] "" A_IVC

BO_ 1460 BMS_A25: 8 CGW
  SG_ HVB_Cell76Voltage : 7|12@0+ (0.001,2) [2|4.6] "V" A_IVC
  SG_ HVB_Cell77Voltage : 11|12@0+ (0.001,2) [2|4.6] "V" A_IVC
  SG_ HVB_Cell78Voltage : 31|12@0+ (0.001,2) [2|4.6] "V" A_IVC
  SG_ HVB_Cell79Voltage : 35|12@0+ (0.001,2) [2|4.6] "V" A_IVC
  SG_ HVB_Cell80Voltage : 55|12@0+ (0.001,2) [2|4.6] "V" A_IVC

BO_ 1461 BMS_A24: 8 CGW
  SG_ HVB_Cell71Voltage : 7|12@0+ (0.001,2) [2|4.6] "V" A_IVC
  SG_ HVB_Cell72Voltage : 11|12@0+ (0.001,2) [2|4.6] "V" A_IVC
  SG_ HVB_Cell73Voltage : 31|12@0+ (0.001,2) [2|4.6] "V" A_IVC
  SG_ HVB_Cell74Voltage : 35|12@0+ (0.001,2) [2|4.6] "V" A_IVC
  SG_ HVB_Cell75Voltage : 55|12@0+ (0.001,2) [2|4.6] "V" A_IVC

BO_ 1462 HVAC_A105: 8 CGW
  SG_ ClimFrontDefrostDisplay : 14|2@0+ (1,0) [0|0] "" A_IVC

BO_ 1463 BMS_A23: 8 CGW
  SG_ HVB_Cell66Voltage : 7|12@0+ (0.001,2) [2|4.6] "V" A_IVC
  SG_ HVB_Cell67Voltage : 11|12@0+ (0.001,2) [2|4.6] "V" A_IVC
  SG_ HVB_Cell68Voltage : 31|12@0+ (0.001,2) [2|4.6] "V" A_IVC
  SG_ HVB_Cell69Voltage : 35|12@0+ (0.001,2) [2|4.6] "V" A_IVC
  SG_ HVB_Cell70Voltage : 55|12@0+ (0.001,2) [2|4.6] "V" A_IVC

BO_ 1464 IVI_UserSetPref_A5: 7 CGW
  SG_ DriverSeatMemoRecallReq : 20|3@0+ (1,0) [0|0] "" A_IVC
  SG_ DriverSeatMemoRequest : 23|3@0+ (1,0) [0|0] "" A_IVC
  SG_ DriverEasyAccessRequest2 : 25|2@0+ (1,0) [0|0] "" A_IVC

BO_ 1465 IVI_A110: 8 CGW
  SG_ PreSoakTempValue_MMI_v2 : 7|7@0+ (0.5,16) [16|32] "°C" A_IVC
  SG_ FrontRightSeatRequest : 51|4@0+ (1,0) [0|0] "" A_IVC
  SG_ FrontLeftSeatRequest : 55|4@0+ (1,0) [0|0] "" A_IVC
  SG_ Dccharge_NextStationTimeArrival : 63|7@0+ (1,0) [0|120] "min" A_IVC

BO_ 1466 BCM_A2: 5 CGW
  SG_ FrontLeftWheelPressure_V2 : 7|8@0+ (30,0) [0|7620] "mbar" A_IVC
  SG_ FrontRightWheelPressure_V2 : 15|8@0+ (30,0) [0|7620] "mbar" A_IVC
  SG_ RearLeftWheelPressure_V2 : 23|8@0+ (30,0) [0|7620] "mbar" A_IVC
  SG_ RearRightWheelPressure_V2 : 31|8@0+ (30,0) [0|7620] "mbar" A_IVC

BO_ 1468 DSMU_A1: 7 CGW
  SG_ DriverMassageVelocityState : 2|3@0+ (1,0) [0|0] "" A_IVC
  SG_ DriverMassageIntensityState : 7|3@0+ (1,0) [0|0] "" A_IVC
  SG_ DriverMassageActivationState : 29|1@0+ (1,0) [0|0] "" A_IVC

CM_ BO_ 1386 "[C1AHS-T3-2017]: Specific C1A  frame";

VAL_ 32 AirbagCrashOrder_v3 0 "Crash not detected" 15 "Medium crash" 31 "Violent crash" 47 "Rear crash";
VAL_ 32 DirectionRear2ndCollision 0 "No detect" 1 "Detect";
VAL_ 32 DirectionRollover2ndCollision 0 "No detect" 1 "Detect";
VAL_ 32 DataSetCollisionValidity 0 "First collision" 1 "Second collision";
VAL_ 32 SeatBeltStatusDriver1stCollision 0 "SB Not monitored" 1 "SB unfastened" 2 "SB fastened" 3 "Unavailable";
VAL_ 32 SeatBeltStatusPass1stCollision 0 "SB Not monitored" 1 "SB unfastened" 2 "SB fastened" 3 "Unavailable";
VAL_ 32 DirectionLeft1stCollision 0 "No detect" 1 "Detect";
VAL_ 32 SeatBeltStatusDriver2ndCollision 0 "SB Not monitored" 1 "SB unfastened" 2 "SB fastened" 3 "Unavailable";
VAL_ 32 SeatBeltStatusPass2ndcollision 0 "SB Not monitored" 1 "SB unfastened" 2 "SB fastened" 3 "Unavailable";
VAL_ 32 DirectionLeft2ndCollision 0 "No detect" 1 "Detect";
VAL_ 32 DirectionRight2ndCollision 0 "No detect" 1 "Detect";
VAL_ 32 DirectionFront2ndCollision 0 "No detect" 1 "Detect";
VAL_ 32 DirectionRollover1stCollision 0 "No detect" 1 "Detect";
VAL_ 32 RolloverDetection 0 "Rollover not detected" 1 "Rollover detected";
VAL_ 32 DirectionRight1stCollision 0 "No detect" 1 "Detect";
VAL_ 32 DirectionFront1stCollision 0 "No detect" 1 "Detect";
VAL_ 32 DirectionRear1stCollision 0 "No detect" 1 "Detect";
VAL_ 116 StopAutoPhase 0 "NotInAutoPhase" 1 "StartAuto" 2 "StopAuto" 3 "Not Used" 4 "StopAutoOngoing" 5 "StartByInjectionOnly" 6 "ReflexStart" 7 "Unavailable";
VAL_ 117 PowerTrainStatus 0 "Powertrain Stopped" 1 "Reserved" 2 "Powertrain Running" 3 "Powertrain Starting";
VAL_ 117 EngineStopRequestOrigin 0 "No engine stop request (initial stop or independant engine running)" 1 "Engine stopped by other causes" 2 "Engine stopped by normal system request" 3 "Engine stopped by normal driver request" 4 "Engine stopped by emergency request" 5 "Not used" 6 "Not used" 7 "Not used";
VAL_ 303 GearLeverPosition_v2 0 "Parking - P" 1 "Reverse - R" 2 "Neutral - N" 3 "Drive - D" 4 "Manual mode - M" 5 "L" 6 "Ds" 7 "Confirmed lever position (no switch signal)" 8 "B (Brake)" 9 "Not used" 10 "Not used" 11 "Not used" 12 "Not used" 13 "Not used" 14 "Not used" 15 "Not available (init or lever switched failure)";
VAL_ 514 ABSinRegulation 0 "no ABS regulation" 1 "ABS in regulation";
VAL_ 514 WheelTopFL 96 "Max Nissan Value for 96 pulses" 108 "Max Nissan Value for 108 pulses";
VAL_ 514 ASRinRegulation 0 "no ASR regulation" 1 "ASR in regulation";
VAL_ 514 WheelTopFR 96 "Max Nissan Value for 96 pulses" 108 "Max Nissan Value for 108 pulses";
VAL_ 514 MSRinRegulation 0 "no MSR regulation" 1 "MSR in regulation";
VAL_ 514 WheelTopRL 96 "Max Nissan Value for 96 pulses" 108 "Max Nissan Value for 108 pulses";
VAL_ 514 WheelTopRR 96 "Max Nissan Value for 96 pulses" 108 "Max Nissan Value for 108 pulses";
VAL_ 514 VDC_StandStillStatus 0 "Vehicle not hold" 1 "Vehicle hold" 2 "Vehicle hold not possible" 3 "Not used";
VAL_ 514 WheelDirectionRR 0 "No movement detected yet" 1 "Wheel Front Direction" 2 "Wheel Rear Direction" 3 "Unavailable";
VAL_ 514 WheelDirectionRL 0 "No movement detected yet" 1 "Wheel Front Direction" 2 "Wheel Rear Direction" 3 "Unavailable";
VAL_ 514 AYCMalfunction 0 "no AYC malfunction" 1 "AYC malfunction";
VAL_ 514 AYCinRegulation 0 "no AYC regulation" 1 "AYC in regulation";
VAL_ 514 ASRMalfunction 0 "No ASR malfunction" 1 "ASR malfunction";
VAL_ 514 ABSMalfunction 0 "no ABS malfunction" 1 "ABS malfunction";
VAL_ 514 WheelDirectionFR 0 "No movement detected yet" 1 "Wheel Front Direction" 2 "Wheel Rear Direction" 3 "Unavailable";
VAL_ 514 WheelDirectionFL 0 "No movement detected yet" 1 "Wheel Front Direction" 2 "Wheel Rear Direction" 3 "Unavailable";
VAL_ 534 EPSWarning 0 "No EPS warning" 1 "EPS failure level 1" 2 "EPS failure level 2" 3 "EPS meter lamp check";
VAL_ 546 ACCompClutchStatus 0 "Compressor clutch off" 1 "Compressor clutch on";
VAL_ 552 TerminationReq_Offboard 0 "Table Value609470";
VAL_ 579 VKM_VKStatus_UWB 0 "Not ready" 1 "Ready" 2 "Advertising" 3 "Connecting" 4 "Connected" 5 "Disconnecting" 6 "Temporary fail" 7 "Fail";
VAL_ 579 VK_Status 0 "Not Available" 1 "Inside The Car" 2 "Outside The Car" 3 "Out Of Range";
VAL_ 579 VKM_VKStatus_BLE 0 "Not ready" 1 "Ready" 2 "Advertising" 3 "Connecting" 4 "Connected" 5 "Disconnecting" 6 "Temporary fail" 7 "Fail";
VAL_ 579 VKM_RPKStatus_BLE 0 "Not ready" 1 "Ready" 2 "Advertising" 3 "Connecting" 4 "Connected" 5 "Disconnecting" 6 "Temporary fail" 7 "Fail";
VAL_ 748 RPK_VEHTOVKM_A1 0 "Table Value604888";
VAL_ 749 RPK_VEHTOVKM_A2 0 "Table Value604889";
VAL_ 750 RPK_VEHTOVKM_A3 0 "Table Value604890";
VAL_ 751 RPK_VEHTOVKM_A4 0 "Table Value604891";
VAL_ 764 RPK_VKMTOVEH_A1 0 "Table Value609466";
VAL_ 765 RPK_VKMTOVEH_A2 0 "Table Value609467";
VAL_ 766 RPK_VKMTOVEH_A3 0 "Table Value609468";
VAL_ 767 RPK_VKMTOVEH_A4 0 "Table Value609469";
VAL_ 791 BlowerFanMotorStatus_AC 0 "Blower fan motor off" 1 "Blower fan motor on";
VAL_ 791 ACCompValveRequest 127 "No AC_Comp valve Request";
VAL_ 791 ACCompRequest 0 "No air conditionning requested" 1 "Air Conditioning Requested";
VAL_ 791 PTCNumberThermalRequest 0 "0 PTC requested" 1 "1 PTC requested" 2 "2 PTC requested" 3 "3 PTC requested" 4 "4 PTC requested" 5 "5 PTC requested" 6 "6 PTC requested" 7 "7 PTC requested" 8 "8 PTC requested" 9 "9 PTC requested" 10 "10 PTC requested" 11 "Not used" 12 "Not used" 13 "Not used" 14 "Not used" 15 "No request for PTC number thermal request";
VAL_ 791 AC_StopAutoForbidden 0 "Not used" 1 "Auto Stop forbidden" 2 "Auto stop authorized" 3 "Not used";
VAL_ 791 RearDefrostRequest 0 "No rear defrost Requested" 1 "Rear defrost requested";
VAL_ 791 ClimECOModeStatusDisplay 0 "No display" 1 "Activated" 2 "Not Activated" 3 "Unavailable";
VAL_ 823 ClimForcedRecyDisplay 0 "No display" 1 "Recycling On" 2 "Recycling OFF" 3 "Not Used";
VAL_ 823 ClimAutoRecyclingDisplay 0 "Unavailable value" 1 "Automatic Recycling not in progress" 2 "Automatic Recycling in progress" 3 "Not Used";
VAL_ 867 RPK_UWBRequest 0 "No Request" 1 "UWB Request";
VAL_ 870 AnchorDetectingStatusFR 0 "No Detection" 1 "Detecting";
VAL_ 870 AnchorDetectingStatusFL 0 "No Detection" 1 "Detecting";
VAL_ 870 VK_ZoneInfoForRPK 0 "No Detection" 1 "Inside the Car" 2 "ZoneUnder3m" 3 "Zone3to4m" 4 "Zone4to5m" 5 "Zone5to6m" 6 "Zone6to7m" 7 "ZoneOver7m";
VAL_ 870 AnchorDetectingStatusRR 0 "No Detection" 1 "Detecting";
VAL_ 870 AnchorDetectingStatusRL 0 "No Detection" 1 "Detecting";
VAL_ 870 AnchorDetectingStatusIR 0 "No Detection" 1 "Detecting";
VAL_ 870 AnchorDetectingStatusIL 0 "No Detection" 1 "Detecting";
VAL_ 893 LDW_VibrationIntensityState 0 "Unavailable" 1 "Low Intensity" 2 "Middle Intensity" 3 "High Intensity";
VAL_ 893 CDU_SteeringWheelTorqueLevel 0 "Driver steering wheel torque < threshold 1" 1 "threshold 1 <= Driver steering wheel torque < threshold 2" 2 "threshold 2 <= Driver steering wheel torque" 3 "Unavailable";
VAL_ 896 DTCO_Driver1TimeRelatedStates 0 "Normal_No Limits Reached" 1 "Limit1_15Min Before 4h30" 2 "Limit2_4h30 Reached" 3 "Limit3_15Min Before 9h" 4 "Limit4_9h Reached" 5 "Limit5_15Min Before 16h" 6 "Limit6_16h Reached" 7 "WeeklyDrivingTimePreWarningActive" 8 "WeeklyDrivingTimeWarningActive" 9 "2WeeksDrivingTimePreWarningActive" 10 "2WeeksDrivingTimeWarningActive" 11 "Driver1CardExpiryWarningActive" 12 "NextMandatoryDriver1CardDownloadWarningActive" 13 "Other" 14 "Error" 15 "NotAvailable";
VAL_ 896 DTCO_OverSpeed 0 "No Overspeed" 1 "Overspeed" 2 "Error" 3 "Not Available";
VAL_ 896 DTCO_Driver2TimeRelatedStates 0 "no time related warning detected." 1 "Reserved" 2 "Reserved" 3 "Reserved" 4 "Reserved" 5 "daily/weekly rest pre-warning active" 6 "daily/weekly rest warning active" 7 "Reserved" 8 "Reserved" 9 "Reserved" 10 "Reserved" 11 "driver 2 card expiry warning active" 12 "next mandatory driver 2 card download warning active" 13 "Other" 14 "Error" 15 "Not available";
VAL_ 909 NFCframe_VKM_to_NFC_Inside 0 "Table Value609510";
VAL_ 944 HeavyRain_Status 0 "no heavy rain" 1 "heavy rain";
VAL_ 944 BCM_ContextSteeringSwitchStatus 0 "Switch released" 1 "Switch pressed";
VAL_ 955 RST_Boost_Activation_MMI 0 "No Display" 1 "Boost Deactivated" 2 "Boost Activated" 3 "Boost Unavailable";
VAL_ 956 AAM_DigitalInputMonitoring4 0 "Not used" 1 "ON" 2 "OFF" 3 "Unavailable";
VAL_ 956 AAM_DigitalInputMonitoring3 0 "Not used" 1 "ON" 2 "OFF" 3 "Unavailable";
VAL_ 956 AAM_DigitalInputMonitoring2 0 "Not used" 1 "ON" 2 "OFF" 3 "Unavailable";
VAL_ 956 AAM_DigitalInputMonitoring1 0 "Not used" 1 "ON" 2 "OFF" 3 "Unavailable";
VAL_ 956 AAM_DigitalInputMonitoring5 0 "Not used" 1 "ON" 2 "OFF" 3 "Unavailable";
VAL_ 960 PSD_R_LatchStatus 0 "Unavailable" 1 "Unlatched" 2 "Latched" 3 "Half Latched";
VAL_ 960 PSD_R_FailureStatus 0 "No Failure" 1 "Motor Failure" 2 "Motor Overheating" 3 "Position Failure" 4 "Touch Sens Failure" 5 "ECU Failure" 6 "Supply Failure" 7 "Not Used";
VAL_ 960 PSD_R_ZoningPosition 0 "Unavailable" 1 "Full Close" 2 "Mechanical Close" 3 "Middle" 4 "Soft Full Open" 5 "Mechanical Full Open" 6 "Not Used" 7 "Not Used";
VAL_ 960 PSD_R_MovementAuthorizationState 0 "Unavailable" 1 "Authorized" 2 "Closing Authorize" 3 "Inhibit";
VAL_ 967 SwitchRequest_AVM 0 "Switch released" 1 "Switch pushed";
VAL_ 967 PassengerHeatingRequest 0 "No Request" 1 "Heating 1 request" 2 "Heating 2 request" 3 "Off request";
VAL_ 970 VirtualKeyState 0 "VK Suspended" 1 "VK Resumed";
VAL_ 970 VirtualKeyActivationStatus 0 "Virtual Key is deactivated" 1 "Virtual Key is activated";
VAL_ 970 BLM_RefuseToSleep 0 "Reserved" 1 "BLM refuse to sleep" 2 "BLM ready to sleep" 3 "Reserved";
VAL_ 996 DriverMassageProgramState_v3 0 "Massage is not running" 1 "Program massage 1 is runnning" 2 "Program massage 2 is runnning" 3 "Program massage 3 is runnning" 4 "Program massage 4 is runnning" 5 "Program massage 5 is runnning" 6 "Program massage 6 is runnning" 7 "Program massage 7 is runnning" 8 "Program massage 8 is runnning" 9 "Program massage 9 is runnning" 10 "Program massage 10 is runnning" 11 "Program massage 11 is runnning" 12 "Program massage 12 is runnning" 13 "Program massage 13 is runnning" 14 "Program massage 14 is runnning" 15 "Not used";
VAL_ 1000 RemoteLight_HFM 0 "No request" 1 "Remote lighting request";
VAL_ 1000 IKeyRemoteUnProtectStatus 0 "Protect" 1 "UnProtect";
VAL_ 1000 IkeyfobInsideVehicleFound_VK 0 "No ikeyfob inside vehicle" 1 "1 ikeyfob found inside vehicle" 2 "2 ikeyfob found inside vehicle" 3 "3 ikeyfob found inside vehicle" 4 "4 ikeyfob found inside vehicle" 5 "Not used" 6 "Not used" 7 "Unavailable";
VAL_ 1000 VKAuthRequest 0 "No Request" 1 "VK authentication request";
VAL_ 1001 PassengerMassageProgramState_v3 0 "Massage is not running" 1 "Program massage 1 is runnning" 2 "Program massage 2 is runnning" 3 "Program massage 3 is runnning" 4 "Program massage 4 is runnning" 5 "Program massage 5 is runnning" 6 "Program massage 6 is runnning" 7 "Program massage 7 is runnning" 8 "Program massage 8 is runnning" 9 "Program massage 9 is runnning" 10 "Program massage 10 is runnning" 11 "Program massage 11 is runnning" 12 "Program massage 12 is runnning" 13 "Program massage 13 is runnning" 14 "Program massage 14 is runnning" 15 "Not used";
VAL_ 1011 VKM_RefuseToSleep 0 "Reserved" 1 "VKM refuse to sleep" 2 "VKM ready to sleep" 3 "Reserved";
VAL_ 1011 NFC_Inside_activation_frame 0 "Not activate" 1 "Activate";
VAL_ 1011 InsideIkeyfobSearchRequest 0 "No Request (default value)" 1 "ikeyfob inside vehicle search request";
VAL_ 1012 AutoACC2_ON_Request_IVC 0 "No request" 1 "AutoACC2 requested";
VAL_ 1012 ECALL_StateDisplay_V3 0 "No message" 1 "Not used" 2 "Not used" 3 "Not used" 4 "Manual Ecall launch" 5 "Ecall auto launch" 6 "Manual Ecall failure" 7 "Ecall launch cancelled" 8 "Ecall on going" 9 "Voice communication on going - MSD not sent" 10 "Voice communication on going - MSD sent" 11 "Voice call failure" 12 "End of voice communication" 13 "Incoming call" 14 "Not used" 15 "Ecall malfunction";
VAL_ 1012 TCU_MuteRadioOrder 0 "No mute radio order" 1 "Mute radio order";
VAL_ 1012 TCU_Refuse_To_Sleep 0 "reserved" 1 "TCU refuse to sleep " 2 "TCU ready to sleep" 3 "reserved";
VAL_ 1012 ECALL_State_EDR 0 "Operational" 1 "Malfunction" 2 "Reserved" 3 "Unavailable";
VAL_ 1012 IVC_FOTAbusyFlag 0 "IVC FOTA Busy" 1 "IVC FOTA Ready";
VAL_ 1012 IVC_FOTA_Status_v2 0 "idle" 1 "Inventory read in progress" 2 "Inventory read complete" 3 "Distribution in progress" 4 "Integrity check in progress" 5 "Distribution complete" 6 "Installation in progress" 7 "Installation complete" 8 "Vehicle Condition check in progress" 9 "Ready for activation" 10 "Activation in progress" 11 "Activation complete" 12 "Cancel in progress" 13 "Cancel complete" 14 "Rollback in progress" 15 "Rollback complete" 16 "Reboot in progress" 17 "Setting in progress" 18 "Setting completed" 19 "Inventory upload in progress" 20 "Inventory upload completed" 21 "Not used" 22 "Not used" 23 "Not used" 24 "Not used" 25 "Not used" 26 "Not used" 27 "Not used" 28 "Not used" 29 "Not used" 30 "Not used" 31 "invalid";
VAL_ 1012 ECALL_StateDisplay_V4 0 "No message" 1 "Not used" 2 "Not used" 3 "Manual Ecall - push to cancel" 4 "Manual Ecall launch" 5 "Ecall auto launch" 6 "Manual Ecall failure" 7 "Ecall launch cancelled" 8 "Ecall on going" 9 "Voice communication on going - MSD not sent" 10 "Voice communication on going - MSD sent" 11 "Voice call failure" 12 "End of voice communication" 13 "Incoming call" 14 "Not used" 15 "Ecall malfunction";
VAL_ 1047 HFP_ExtendedInstrContentDisplay2 0 "instruction 1" 1 "instruction 2" 2 "instruction 3" 3 "instruction 4" 4 "instruction 5" 5 "instruction 6" 6 "instruction 7" 7 "instruction 8" 8 "instruction 9" 9 "instruction 10" 10 "instruction 11" 11 "instruction 12" 12 "instruction 13" 13 "instruction 14" 14 "instruction 15" 15 "instruction 16" 16 "instruction 17" 17 "instruction 18" 18 "instruction 19" 19 "instruction 20" 20 "instruction 21" 21 "instruction 22" 22 "instruction 23" 23 "instruction 24" 24 "instruction 25" 25 "instruction 26" 26 "instruction 27" 27 "instruction 28" 28 "instruction 29" 29 "instruction 30" 30 "instruction 31" 31 "unavailable";
VAL_ 1049 AAM_StopAutoForbidden 0 "Not used" 1 "Auto Stop forbidden" 2 "Auto stop authorized" 3 "Not used";
VAL_ 1064 HVBatConditionningMode 0 "Blowing Requested" 1 "Cooling Conditionning Requested" 2 "Heating Conditionning requested" 3 "Unavailable";
VAL_ 1065 HVBatteryLow 0 "No HV Battery Low Display Requested" 1 "HV Battery Low Display Requested";
VAL_ 1065 ChargingPlugConnected_v2 0 "No display request (Charging Plug is NOT Connected)" 1 "Charging Plug is Connected" 2 "PWT Start impossible - Plug Connected" 3 "Unavailable value";
VAL_ 1065 EcoNavStatus_v2 0 "Function not activated" 1 "Awaiting data transmission" 2 "On computing" 3 "On regulation" 4 "On updating" 5 "Failed to compute" 6 "Solution with ask to recharge on driving" 7 "Solution with ask to recharge at station" 8 "No ZEV Zone Function" 9 "Not Used" 10 "Not Used" 11 "Not Used" 12 "Not Used" 13 "Not Used" 14 "Not Used" 15 "Not Used";
VAL_ 1066 HVbatteryChargeType_v2 0 "No charge" 1 "Normal charge" 2 "Accelerated charge" 3 "Fast charge" 4 "Quick charge" 5 "Ultra fast" 6 "V2H" 7 "V2G";
VAL_ 1066 RegenBrakingLevelDisplay 0 "Regenerative braking level 0" 1 "Regenerative braking level 1" 2 "Regenerative braking level 2" 3 "Regenerative braking level 3" 4 "Regenerative braking level 4" 5 "Regenerative braking level 5" 6 "Not Used" 7 "No display";
VAL_ 1068 HEV_ChargeFailureDisplay 0 "No Alert" 1 "Alert";
VAL_ 1068 HVchargerStatus 0 "No HV charge" 1 "HV battery charge" 2 "HV consumers charge" 3 "Not used";
VAL_ 1068 VehicleTractionMode 0 "Vehicle not in traction mode" 1 "Vehicle in charge" 2 "Vehicle in full electric mode" 3 "Vehicle in hybrid serial mode" 4 "Vehicle in thermic mode" 5 "Vehicle in hybrid parallel mode" 6 "Not Used" 7 "Unavailable value";
VAL_ 1068 ChargingStatusDisplay_v2 0 "No charge" 1 "Waiting a planned charge" 2 "Ended charge" 3 "Charge in progress" 4 "Charge failure" 5 "Waiting for current charge" 6 "Energy Flap opened: welcome MMI" 7 "Stopped charge(SOC is not full)" 8 "Charging is continue with full SOC" 9 "V2G" 10 "V2L Outside" 11 "V2G in discharge" 12 "V2G in charge" 13 "Not used" 14 "Not used" 15 "Not used";
VAL_ 1068 HybridTractionModeCursorDisplay 0 "No display" 1 "EV mode selected" 2 "Auto mode selected" 3 "Sport mode selected" 4 "Charge Battery selected" 5 "Save Battery level selected" 6 "Not Used" 7 "Not Used";
VAL_ 1076 BadgeBatteryLow 0 " No Display request (badge battery OK)" 1 "badge battery low";
VAL_ 1076 PushtoStartButton 0 "No Button pressed" 1 "Push to Start button is pressed";
VAL_ 1086 AC_CustomerRequest 0 "No AC customer request" 1 "AC customer request";
VAL_ 1086 COMPR_ON_flag 0 "Compressor OFF" 1 "Compressor ON";
VAL_ 1086 AirShutterClosingRequest 0 "No Air Shutters Closure Request" 1 "Air Shutters Closure Request";
VAL_ 1086 AirShutterOpeningRequest 0 "No Air Shutters Opening Request" 1 "Air Shutters Opening Request";
VAL_ 1087 H2DeratingFCTemp 0 "No Display" 1 "Temperature of Fuel cell too high" 2 "Temperature of Fuel cell too low" 3 "Not Used";
VAL_ 1087 H2LeakDetection 0 "No Display" 1 "Light H2 Leak" 2 "Heavy H2 Leak" 3 "Not Used";
VAL_ 1087 H2LidOpened 0 "No Display" 1 "Lid Opened Display";
VAL_ 1087 H2EndOfRefueling 0 "No Display" 1 "End of Refueling Display";
VAL_ 1087 RefuelingInProgress 0 "No Display" 1 "Refueling In Progress";
VAL_ 1087 H2LowLevelAlert 0 "No Display" 1 "Alert Display";
VAL_ 1087 FCFailure 0 "No Display" 1 "Defect fuel cell" 2 "System Failure H2" 3 "Not Used";
VAL_ 1087 FCAvailability 0 "No Display" 1 "Fuel Cell Activated" 2 "Fuel Cell Not Activated" 3 "Not Used";
VAL_ 1090 PSD_L_ZoningPosition 0 "Unavailable" 1 "Full Close" 2 "Mechanical Close" 3 "Middle" 4 "Soft Full Open" 5 "Mechanical Full Open" 6 "Not Used" 7 "Not Used";
VAL_ 1090 PSD_L_MovementAuthorizationState 0 "Unavailable" 1 "Authorized" 2 "Closing Authorize" 3 "Inhibit";
VAL_ 1090 PSD_L_LatchStatus 0 "Unavailable" 1 "Unlatched" 2 "Latched" 3 "Half Latched";
VAL_ 1090 PSD_L_FailureStatus 0 "No Failure" 1 "Motor Failure" 2 "Motor Overheating" 3 "Position Failure" 4 "Touch Sens Failure" 5 "ECU Failure" 6 "Supply Failure" 7 "Not Used";
VAL_ 1099 RST_LaunchControlReadyMMI 0 "No display" 1 "Launch Control Not Active" 2 "Display Launch Control Active" 3 "reserved";
VAL_ 1099 ATCVT_TowingMode 0 "Towing switch OFF or not existant" 1 "Towing switch ON";
VAL_ 1099 ATCVT_RangeIndicationExtended 0 "OFF" 1 "P range" 2 "R range" 3 "N range" 4 "D range" 5 "S range" 6 "L range" 7 "B range" 8 "1st range" 9 "2nd range" 10 "3rd range" 11 "4th range" 12 "5th range" 13 "6th range" 14 "7th range" 15 "8th range" 16 "9th range" 17 "10th range" 18 "Not used" 19 "Not used" 20 "M1st" 21 "M2nd" 22 "M3rd" 23 "M4th" 24 "M5th" 25 "M6th" 26 "M7th" 27 "M8th" 28 "M9th" 29 "M10th" 30 "Not used" 31 "Not used" 32 "Auto 1st" 33 "Auto 2nd" 34 "Auto 3rd" 35 "Auto 4th" 36 "Auto 5th" 37 "Auto 6th" 38 "Auto 7th" 39 "Auto 8th" 40 "Auto 9th" 41 "Auto 10th" 42 "Not used" 43 "Not used" 44 "Not used" 45 "Not used" 46 "Not used" 47 "Not used" 48 "Not used" 49 "Not used" 50 "Not used" 51 "Not used" 52 "Not used" 53 "Not used" 54 "Not used" 55 "Not used" 56 "Not used" 57 "Not used" 58 "Not used" 59 "Not used" 60 "Not used" 61 "Not used" 62 "Not used" 63 "Not used";
VAL_ 1100 AT_Parkfailure 0 "No park failure" 1 "Park Failure";
VAL_ 1100 TransmRangeEngaged_Current 0 "declutched at rest" 1 "1st range" 2 "2nd range" 3 "3rd range" 4 "4th range" 5 "5th range" 6 "6th range" 7 "7th range" 8 "8th range" 9 "reverse" 10 "neutral or parking" 11 "CVT in continuous mode" 12 "9th range" 13 "10th range" 14 "Not used" 15 "AT in limphome";
VAL_ 1100 ShifterPosition 0 "Home" 1 "Rear" 2 "Neutral" 3 "Drive" 4 "Manual +" 5 "Manual -" 6 "Not used" 7 "Not used";
VAL_ 1101 TurnSwitchStatus 0 "No Flasher" 1 "Left Flasher" 2 "Right Flasher" 3 "Left Motorway Flasher" 4 "Right Motorway Flasher" 5 "Not Used" 6 "Not Used" 7 "Unavailable";
VAL_ 1101 FlashingIndicatorStatusDisplay 0 "left and right flashing indicators OFF" 1 "left flashing indicator ON and right flashing indicator OFF" 2 "left flashing indicator OFF and right flashing indicator ON" 3 "left flashing indicator ON and right flashing indicator ON" 4 "Not used" 5 "Not used" 6 "Not used" 7 "Unavailable";
VAL_ 1102 AutoFrontWiperActivationStatus 0 "Auto Front wiper de-activation requested" 1 "Auto Front wiper activation requested" 2 "Not used" 3 "Not used";
VAL_ 1102 RearWiperStatus 0 "Unavailable" 1 "Rear wiper activation requested" 2 "Rear wiper de-activation requested" 3 "Not used";
VAL_ 1102 FrontRearWiperDropStatus 0 "Wiper Drop Deactivated" 1 "Wiper Drop Activated";
VAL_ 1102 RLS_Failure 0 "No failure" 1 "rain sensor failure" 2 "Not Used" 3 "Unvailable";
VAL_ 1102 RainSensitivity_Customer 0 "low sensitivity" 1 "low-medium sensitivity" 2 "medium-high sensitivity" 3 "high sensitivity" 4 "very high sensitivity" 5 "Not Used" 6 "Not Used" 7 "Not Used";
VAL_ 1102 LowBeamDisplay 0 "low beam display not requested" 1 "low beam display requested";
VAL_ 1102 HighBeamDisplay 0 "High beam display not requested" 1 "High beam display requested";
VAL_ 1103 AHL_ActivationDisplay 0 "Not used" 1 "AHL activated" 2 "AHL NOT activated" 3 "Unavailable";
VAL_ 1103 FollowMeHomeDurationDisplay 0 "No Follow me home duration Display" 1 "Follow me home duration : 30s" 2 "Follow me home duration : 60s" 3 "Follow me home duration : 90s" 4 "Follow me home duration : 120s" 5 "Not Used" 6 "Not Used" 7 "Not Used";
VAL_ 1103 PositionLightsDisplay 0 "position lights display not requested" 1 "position lights display requested";
VAL_ 1103 BCM_MMISteeringSwitchesFailure 0 "No MMI steering switches failure" 1 "MMI steering switches failure";
VAL_ 1103 CockpitLocked_State 0 "Not Locked" 1 "Locked";
VAL_ 1103 LoadingAreaLocked_State 0 "Loading area Not Locked" 1 "Loading area Locked";
VAL_ 1104 ExternalTempDisplayUnit 0 "display mode in °C" 1 "display mode in °F";
VAL_ 1104 SteeringPushToTalkCommand 0 "Button released" 1 "Button pressed";
VAL_ 1104 OilChangeCounterReset 0 "No request" 1 "Oil change counter reset";
VAL_ 1104 Meter_ADACresetRequest 0 "Reset  METER not requested" 1 "Reset  METER requested";
VAL_ 1104 DiagnosedFuelLow 0 "Unavailable" 1 "Not empty" 2 "Empty" 3 "Not used";
VAL_ 1104 DisplayedOilLevel 0 "warning" 1 "1 bargraph element displayed" 2 "2 bargraph element displayed" 3 "3 bargraph element displayed" 4 "4 bargraph element displayed" 5 "5 bargraph element displayed" 6 "6 bargraph element displayed" 7 "7 bargraph element displayed" 8 "8 bargraph element displayed" 9 "Not used" 10 "Not used" 11 "Not used" 12 "Not used" 13 "Not used" 14 "Not used" 15 "not available";
VAL_ 1104 FuelLevelDisplayed 0 "petrol tank reserve";
VAL_ 1105 DisplayedSpeedUnit 0 "Speed Unit in kmph" 1 "Speed Unit in mph";
VAL_ 1105 GlobalVehicleWarningState 0 "No global  vehicle  Fault" 1 "SERV is ON (alert type R3)" 2 "STOP is ON (alert type D3)" 3 "SERV and STOP are ON (alert type R3& D3)";
VAL_ 1105 DayNightForBacklights 0 "Day" 1 "Twilight" 2 "Night" 3 "Unavailable";
VAL_ 1105 ParkingBrakeStatus 0 "Not used" 1 "Automatic or manual Parking brake not applied" 2 "Automatic or manual Parking brake applied" 3 "Unavailable";
VAL_ 1105 LowBrakeFluidLevelStatus 0 "Unavailable" 1 "No brake system malfunction" 2 "Brake system malfunction" 3 "Not used";
VAL_ 1106 DayNightStatusForB_Switches 0 "Conditionned backlight" 1 "Permanent backlight";
VAL_ 1107 RearGearEngaged 0 "Not used" 1 "Rear Gear not Engaged" 2 "Rear Gear Engaged" 3 "unavailable";
VAL_ 1107 EngineHoodState 0 "Unvailable value" 1 "Hood opened" 2 "Hood closed" 3 "Not used";
VAL_ 1107 BattWarnReq_Level_Hi_USM_v2 0 "Not used" 1 "No Alert" 2 "Alert" 3 "Unavailable value";
VAL_ 1107 IgnitionSupplyConfirmation 0 "no primary ignition supply" 1 "primary ignition supply on";
VAL_ 1107 BattSetPointGeneratorStatus_V2 0 "Nominal mode" 1 "Relative undervoltage confirmed" 2 "Absolute undervoltage confirmed" 3 "Overvoltage confirmed" 4 "Voltage measurement fault confirmed" 5 "Battery disconnected confirmed" 6 "Performances undervoltage confirmed" 7 "Not used";
VAL_ 1107 StarterStatus 0 "cranking relay switched off" 1 "short relaxation active" 2 "long relaxation active" 3 "cranking relay switched on";
VAL_ 1107 EEM_StaticPowerLimitationRequest 0 "No Request" 1 "Life on Board Low SOC power limitation" 2 "Delivery Mode power limitation" 3 "Battery Disconnection power limitation" 4 "Producer failure power limitation" 5 "Not used" 6 "Not used" 7 "Not used";
VAL_ 1107 EEM_HighSpeedStopForbidden 0 "High Speed stop forbidden - EEM malfunction detected" 1 "High Speed stop forbidden" 2 "High Speed stop authorized" 3 "High Speed stop forbidden - EEM malfunction - recranking forbidden";
VAL_ 1108 LowBatteryVoltageDisplay 0 "No display request" 1 "Battery weak" 2 "Battery weak : start engine" 3 "Battery in charge";
VAL_ 1108 FrontWiperStatus 0 "front wiper stopped" 1 "low speed active" 2 "high speed active" 3 "not used";
VAL_ 1108 EEM_RegulationLoopActivationReq 0 "No Activation Request" 1 "Activation Request Level1" 2 "Activation Request Level2" 3 "Not used";
VAL_ 1108 GenMode_v2 0 "GENMODE0 Limitation requested by Engine" 1 "GENMODE1 Nominal strategy Mode" 2 "GENMODE2 ESM intermediate Mode" 3 "GENMODE3 Battery protection" 4 "GENMODE4 ESM Discharge Mode" 5 "GENMODE5 ESM Regeneration Mode" 6 "GENMODE7 ESM inhibited by actuator" 7 "GENMODE9 MinimumVoltageByECM";
VAL_ 1108 EEM_StopAutoForbidden 0 "Stop Auto Forbidden - EEM malfunction detected" 1 "Stop Auto forbidden" 2 "Stop Auto authorized" 3 "Not used";
VAL_ 1108 Storage12V_SwitchRequest 0 "Disconnection request" 1 "Connection request";
VAL_ 1109 EBAfailureDisplayAlert 0 "No Failure" 1 "Failure";
VAL_ 1109 BrakingSystemStateDisplayRequest 0 "No failure" 1 "Failure";
VAL_ 1109 VehicleSpeedSign 0 "nul vehicle speed" 1 "Positive vehicle speed (= Forward motion)" 2 "Negative vehicle speed (= reverse motion)" 3 "Unavailable";
VAL_ 1109 EBDstateDisplayRequest 0 "No failure" 1 "Failure";
VAL_ 1109 CRBSfailureDisplayAlert 0 "No Failure" 1 "Failure";
VAL_ 1109 ABSstateDisplayRequest 0 "No failure" 1 "Failure" 2 "In ext diag session" 3 "To be calibrated";
VAL_ 1109 VDCstateDisplayRequest 0 "No failure and no control" 1 "Failure" 2 "In active control" 3 "Not used";
VAL_ 1109 HSA_ActivationState 0 "Unavailable" 1 "HSA  not activated" 2 "HSA  activated" 3 "not Used";
VAL_ 1109 SSA_EngineStopAutoForbidden 0 "No request" 1 "Auto stop authorized" 2 "Auto stop forbidden" 3 "Not used";
VAL_ 1109 VDCactivationState 0 "VDC function activated" 1 "VDC function deactivated";
VAL_ 1109 TPW_Status 0 "System OK" 1 "Tyre under inflated" 2 "Failure" 3 "TPW not operational";
VAL_ 1109 DynamicBrakingInProgressForEPB_v2 0 "EPB dynamic braking in progress" 1 "EPB dynamic braking not in progress";
VAL_ 1110 BMS12V_SwitchState 0 "Opened" 1 "Closed";
VAL_ 1110 BMS12V_StorageFailure 0 "Limit mode" 1 "Failure mode" 2 "Nominal mode" 3 "Not used";
VAL_ 1119 BattWarnReq_Level_Hi_ECM_v2 0 "Unavailable" 1 "No alert" 2 "Alert" 3 "Not used";
VAL_ 1136 THPnumberThermalRequest_ECM 0 "0 THP requested" 1 "1 THP requested" 2 "2 THP requested" 3 "3 THP requested" 4 "4 THP requested" 5 "5 THP requested" 6 "6 THP requested" 7 "Not used";
VAL_ 1136 EngineControlFailureLevel2 0 "no Engine Control Failure Level 2 create by stoping the engine" 1 "Engine Control Failure Level 2 create by stoping the engine";
VAL_ 1136 VoltageRegulationStatus_V2 0 "Not initialized" 1 "Starting sequence" 2 "Nominal Mode" 3 "Producer power limitation" 4 "Producer communication fault is detected" 5 "Producer communication fault is confirmed" 6 "Producer fault is detected" 7 "Producer fault is confirmed" 8 "Undervoltage is detected" 9 "Undervoltage is confirmed" 10 "Overvoltage is detected" 11 "Overvoltage is confirmed" 12 "CAN fault is detected" 13 "CAN fault is confirmed" 14 "Not used" 15 "Unavailable";
VAL_ 1136 ECM_RearDefrostRequest 0 "no rear defrost request" 1 "rear defrost request";
VAL_ 1136 EngineControlFailureLevel1 0 "no Engine Control Failure Level 1" 1 "Engine Control Failure Level 1";
VAL_ 1137 EcoPedalForceSettingStatus 0 "No request" 1 "ECO Pedal Force setting status OFF" 2 "ECO Pedal Force setting status Soft" 3 "ECO Pedal Force setting status Standard";
VAL_ 1137 CruiseControlStatus 0 "Cruise Control (CC) and Speed Limit (SL) OFF" 1 "SL active" 2 "SL on and (awaiting or suspended)" 3 "SL requested and in failure" 4 "CC active" 5 "CC ON and ( awaiting  or suspended)" 6 "CC requested and in failure" 7 "Vehicle not equipped with CC/SL / Not available";
VAL_ 1137 EcoDriveIndicatorDisplay 0 "OFF status" 1 "ON status";
VAL_ 1137 ACC_SailingStatus 0 "Normal driving" 1 "Sailing Idle" 2 "Sailing Stop" 3 "Unavailable";
VAL_ 1138 CruiseEcoActivationState 0 "Unavailable" 1 "ECO activated" 2 "ECO deactivated" 3 "Not used";
VAL_ 1138 StopStartInformationDisplay 0 "No display" 1 "Stop inhibition - Vehicle malfunction" 2 "Stop inhibition - Slope" 3 "Stop inhibition - Vehicle" 4 "Stop inhibition - EEM" 5 "Stop inhibition - Engine" 6 "Stop inhibition - Braking" 7 "Stop inhibition - Hood" 8 "Stop inhibition - Door" 9 "Stop inhibition - Seatbelt" 10 "Stop inhibition - Maneuver" 11 "Stop inhibition - Air conditionning" 12 "Stop inhibition - Steering" 13 "Stop inhibition - i-key not detected" 14 "Stop inhibition - Others" 15 "Not used" 16 "Not used" 17 "Forced restart - Vehicle malfunction" 18 "Not used" 19 "Not used" 20 "Forced restart - EEM" 21 "Forced restart - Engine" 22 "Forced restart - Braking" 23 "Not used" 24 "Forced restart - Door" 25 "Forced restart - Seatbelt" 26 "Forced restart - Maneuver" 27 "Forced restart - Air conditionning" 28 "Forced restart - Steering" 29 "Forced restart - i-key not detected" 30 "Forced restart - Others" 31 "Impossible restart" 32 "Stop &Start failure" 33 "Stop Auto" 34 "Driving tip - Release clutch" 35 "Driving tip - Press brake" 36 "Stop&Start deactivated" 37 "Stop &Start activated" 38 "Not used" 39 "Not used" 40 "Not used" 41 "Not used" 42 "xEV Hood Open Alert" 43 "xEV Seatbelt Not Fastened" 44 "xEV Driver Exit Alert level 1" 45 "xEV Driver Exit Alert level 2" 46 "Driver exit alert" 47 "Hood open alert" 48 "Not used" 49 "Not used" 50 "Not used" 51 "Not used" 52 "Not used" 53 "Not used" 54 "Not used" 55 "Not used" 56 "Not used" 57 "Not used" 58 "Not used" 59 "Not used" 60 "Not used" 61 "Not used" 62 "Not used" 63 "Not used";
VAL_ 1138 KickDownActivated 0 "kick down off" 1 "kick down activated";
VAL_ 1139 DBC_FailureStatus_v2 0 "No DBC failure" 1 "DBC minor failure" 2 "DBC major failure" 3 "Not used";
VAL_ 1139 LowPressureACCut 0 "Low Pressure Gaz cut state" 1 "Not low Pressure Gaz cut state";
VAL_ 1139 StopStartActivationStatus 0 "Stop Start Setting OFF" 1 "Stop Start Setting ON";
VAL_ 1143 RESstatus 0 "Unavailable" 1 "Reserved for safety" 2 "Reserved for safety" 3 "Normal engine start only" 4 "Reserved for safety" 5 "Reserved for safety" 6 "wait for RES / Presoak" 7 "Reserved for safety" 8 "Reserved for safety" 9 "Customer Starting" 10 "Reserved for safety" 11 "Reserved for safety" 12 "Remote Engine Start" 13 "Reserved for safety" 14 "Reserved for safety" 15 "Vehicle without RES";
VAL_ 1143 RearRightDoorState 0 "Unavailable Value" 1 "Rear Right door closed" 2 "Rear Right door open" 3 "Not Used";
VAL_ 1143 DriverSeatBeltFailureState 0 "No Monitoring" 1 "Supposed Driver Seat Belt Failure" 2 "Driver Seat Belt OK" 3 "Not used";
VAL_ 1143 StartingMode_BCM 0 "Powertrain Stopped Request" 1 "No request" 2 "Ignition Request" 3 "Starting Request";
VAL_ 1143 V_WakeUpType 0 "Full Wake-Up Mode" 1 "Selective Wake-Up Mode 1" 2 "Selective Wake-Up Mode 2" 3 "Selective Wake-Up Mode 3" 4 "Selective Wake-Up Mode 4" 5 "Selective Wake-Up Mode 5" 6 "Selective Wake-Up Mode 6" 7 "Unavailable";
VAL_ 1143 V_WakeUpSleepCommand 0 "Go to Sleep" 1 "reserved" 2 "reserved" 3 "WakeUp";
VAL_ 1143 RearFogLightStateDisplay 0 "rear fog light OFF" 1 "rear fog light ON";
VAL_ 1143 DriverDoorState 0 "Unavailable Value" 1 "Driver door closed" 2 "Driver door open" 3 "Not Used";
VAL_ 1143 PassengerDoorState 0 "Unavailable Value" 1 "Passenger door closed" 2 "Passenger door open" 3 "Not used";
VAL_ 1143 RearLeftDoorState 0 "Unavailable Value" 1 "Rear left door closed" 2 "Rear left door open" 3 "Not Used";
VAL_ 1144 TailGateButtonPushed 0 "Unvailable Value" 1 "No TailGate Button is Pushed" 2 "TailGate Button is Pushed" 3 "Not Used";
VAL_ 1144 WakeUpType 0 "Full Wake-Up Mode" 1 "Selective Wake-Up Mode 1" 2 "Selective Wake-Up Mode 2" 3 "Selective Wake-Up Mode 3" 4 "Selective Wake-Up Mode 4" 5 "Selective Wake-Up Mode 5" 6 "Selective Wake-Up Mode 6" 7 "Unavailable";
VAL_ 1144 RearDefrostEngaged 0 "Rear Defrost not engaged" 1 "Rear Defrost engaged";
VAL_ 1144 PositionLightsRequest 0 "position lights not requested" 1 "position lights requested";
VAL_ 1144 FrontFogLightsRequest 0 "front fog lights not requested" 1 "front fog lights requested";
VAL_ 1144 SmartKeylessInformationDisplay 0 "No Display Request" 1 "Brake Pedal and Start Requested" 2 "Declutch and start requested" 3 "Kazashi - Card not detected" 4 "Kazashi separated - Card not detected" 5 "Turn Wheel + Start" 6 "MT gear level on neutral position requested" 7 "AT gear lever on Park requested" 8 "AT gear lever on neutral position requested" 9 "Push" 10 "Engine Running - Card not detected" 11 "Confirm engine Stop on Card not detected" 12 "Confirm engine Stop at Vehicle Speed Unavailable" 13 "Not Used" 14 "Permanent Ignition Alert" 15 "Keylock alert" 16 "Confirm engine stop warning on disconnected 12V battery" 17 "Kazashi authentication succeed" 18 "Emergency engine stop" 19 "Do long press to start" 20 "Keep pedal pressed to start" 21 "Declutch" 22 "FOTA Activation Software" 23 "Not Used" 24 "Not Used" 25 "Not Used" 26 "Not Used" 27 "Not Used" 28 "Not Used" 29 "Not Used" 30 "Not Used" 31 "Not Used";
VAL_ 1144 PTCNumberThermalStatus 0 "0 PTC activated" 1 "1 PTC activated" 2 "2 PTC activated" 3 "3 PTC activated" 4 "4 PTC activated" 5 "5 PTC activated" 6 "6 PTC activated" 7 "7 PTC activated" 8 "8 PTC activated" 9 "9 PTC activated" 10 "10 PTC activated" 11 "Not used" 12 "Not used" 13 "Not used" 14 "Not used" 15 "Unavailable";
VAL_ 1144 DriverDoorLockedStatus 0 "Driver Door Unlocked" 1 "Driver Door Locked";
VAL_ 1144 DayTimeRunningLightRequest 0 "Day time running light not requested" 1 "Day time running light request";
VAL_ 1144 HornRequest 0 "No Request" 1 "Horn OFF Request" 2 "Panic Horn Request" 3 "Lock Horn Request" 4 "Not used" 5 "Perimetric Alarm Horn Request" 6 "Silent Mode Deactivation Horn Request" 7 "Unavailable";
VAL_ 1144 WarningLightsStatus 0 "Warning Lights OFF" 1 "Warning Lights ON";
VAL_ 1144 VehicleOutsideLockedState 0 "Vehicle not locked from the outside by the customer" 1 "Vehicle Locked from the outside by the customer";
VAL_ 1144 DriverSidePosition 0 "Left side" 1 "Right side";
VAL_ 1144 FrontFogLightsDisplay 0 "front fog lights display not requested" 1 "front fog lights display requested";
VAL_ 1144 FrontDefrostEngaged 0 "Front Defrost not engaged" 1 "Front Defrost engaged";
VAL_ 1144 ManualShiftLeverPosition 0 "No manual shift lever request" 1 "Up Manual shift lever pressed" 2 "Down Manual shift lever pressed" 3 "Manual mode activation";
VAL_ 1144 StopStartSwitch 0 "Unavailable" 1 "Switch Pressed" 2 "Switch Released" 3 "Not Used";
VAL_ 1144 ShiftPaddleRequest 0 "No paddle request" 1 "Up paddle pressed" 2 "Down paddle pressed" 3 "Up and Down paddles pressed";
VAL_ 1144 BrakeLampStatus 0 "Brake Lamp Off" 1 "Brake Lamp On";
VAL_ 1144 HeadLampsWasherRequest 0 "headlamps washer not requested" 1 "headlamps washer requested";
VAL_ 1145 SRU_Position 0 "Window position invalid" 1 "Window position 0 (closed)" 2 "Window sector 01" 3 "Window position 1" 4 "Window sector 12" 5 "Window position 2" 6 "Window sector 23" 7 "Window position 3" 8 "Window sector 34" 9 "Window position 4" 10 "Window sector 45" 11 "Window position 5" 12 "Window sector 56" 13 "Window position 6" 14 "Window sector 67" 15 "Window position 7";
VAL_ 1145 WindowPosition_FR 0 "Window position invalid" 1 "Window fully closed (HW or SW block position)" 2 "Window Short Drop position" 3 "Window in intermediate position (upper than RCU position)" 4 "Window RCU Drop position" 5 "Window in intermediate position (default or lower than RCU position)" 6 "Window fully open (SW block position)" 7 "Window fully open (HW block position)";
VAL_ 1145 WindowPosition_FL 0 "Window position invalid" 1 "Window fully closed (HW or SW block position)" 2 "Window Short Drop position" 3 "Window in intermediate position (upper than RCU position)" 4 "Window RCU Drop position" 5 "Window in intermediate position (default or lower than RCU position)" 6 "Window fully open (SW block position)" 7 "Window fully open (HW block position)";
VAL_ 1145 ProbableCustomerFeedBackNeed 0 "Customer feedback probably not needed" 1 "Customer feedback needed";
VAL_ 1145 WindowPosition_RR 0 "Window position invalid" 1 "Window fully closed (HW or SW block position)" 2 "Window Short Drop position" 3 "Window in intermediate position (upper than RCU position)" 4 "Window RCU Drop position" 5 "Window in intermediate position (default or lower than RCU position)" 6 "Window fully open (SW block position)" 7 "Window fully open (HW block position)";
VAL_ 1145 WindowPosition_RL 0 "Window position invalid" 1 "Window fully closed (HW or SW block position)" 2 "Window Short Drop position" 3 "Window in intermediate position (upper than RCU position)" 4 "Window RCU Drop position" 5 "Window in intermediate position (default or lower than RCU position)" 6 "Window fully open (SW block position)" 7 "Window fully open (HW block position)";
VAL_ 1145 DayNightSynthesis 0 "Day" 1 "Twilight" 2 "Night" 3 "Not used";
VAL_ 1145 BackDoorLockedStatus 0 "Back Door is Unlocked" 1 "Back Door is Locked";
VAL_ 1145 AutoFoldingActivationState 0 "Unavailable" 1 "Disable" 2 "IGN Unfold" 3 "Unlock + IGN Unfold";
VAL_ 1145 RearRightDoorLockedStatus 0 "Rear Right Door is Unlocked" 1 "Rear Right Door is Locked";
VAL_ 1145 RearLeftDoorLockedStatus 0 "Rear Left Door is Unlocked" 1 "Rear Left Door is Locked";
VAL_ 1145 PassengerDoorLockedStatus 0 "Passenger Door is Unlocked" 1 "Passenger Door is Locked";
VAL_ 1145 RES_Failure 0 "No Failure" 1 "Car not secured" 2 "Door Open" 3 "Hazard Lamp activated" 4 "Vehicle moving" 5 "Engine Problem" 6 "Gearbox Engaged" 7 "Other state";
VAL_ 1146 IgnitionSwitchPosition 0 "Out of Ignition position" 1 "Turned to Ignition or Starting position";
VAL_ 1146 DriverSafetyBeltBuckleState 0 "SB Not monitored" 1 "SB unfastened" 2 "SB fastened" 3 "Unavailable";
VAL_ 1146 ClutchSwitchMinimumTravel 0 "Not used" 1 "Clutch pedal not pressed" 2 "Clutch pedal pressed at minimum" 3 "Unavailable";
VAL_ 1146 TailGateStatus 0 "Unvailable Value" 1 "TailGate is closed" 2 "TailGate is open" 3 "Not Used";
VAL_ 1146 VehicleStates 0 "Sleeping" 1 "Not used" 2 "CutoffPending" 3 "AutoACC  - BatTempoLevel" 4 "Not used" 5 "IgnitionLevel" 6 "StartingInProgress" 7 "PowertrainRunning" 8 "AutoStart" 9 "EngineSystemStop" 10 "Not used" 11 "Not used" 12 "Not used" 13 "Not used" 14 "Not used" 15 "Unavailable";
VAL_ 1146 BrakeInfoStatus 0 "Not used" 1 "Brake pedal not pressed" 2 "Brake pedal pressed" 3 "Not used" 4 "Brake pedal confirmed pressed" 5 "Not used" 6 "Not used" 7 "unavailable";
VAL_ 1146 DeliveryModeInformation_v2 0 "customer mode" 1 "delivery mode level 1" 2 "delivery mode level 2" 3 "Not used";
VAL_ 1146 FlashingIndicatorCommandPosition 0 "No direction indicator request" 1 "Left Flashing Indicators command ON" 2 "Right Flashing Indicators command ON" 3 "Not used";
VAL_ 1146 FlashingIndicatorStatus 0 "left and right flashing indicators OFF" 1 "left flashing indicator ON and right flashing indicator OFF" 2 "left flashing indicator OFF and right flashing indicator ON" 3 "left flashing indicator ON and right flashing indicator ON" 4 "Not used" 5 "Not used" 6 "Not used" 7 "Unavailable";
VAL_ 1146 GADE_v2 0 "Sleep or Crank fault, Disable DiagMuxDTC" 1 "AutoACC fault, Disable DiagMuxDTC" 2 "ALL fault, Disable DiagMuxDTC" 3 "ALL fault, Enable DiagMuxDTC" 4 "FOTA switch fault, Disable DiagMuxDTC" 5 "Not used" 6 "Not used" 7 "Unavailable";
VAL_ 1146 StopLampDiagnosis 0 "Not used" 1 "No failure" 2 "Failure" 3 "Unavailable";
VAL_ 1146 FrontWiperStatus_BCM 0 "front wiper stopped" 1 "low speed active" 2 "high speed active" 3 "Unavailable";
VAL_ 1146 FrontWipingRequest 0 "front wiper in stop position" 1 "front wiper forced to stop" 2 "Not used" 3 "Not used" 4 "unavailable" 5 "Not used" 6 "low speed wiping requested" 7 "high speed wiping requested";
VAL_ 1146 HighBeamRequest 0 "high beam not requested" 1 "high beam requested";
VAL_ 1146 HighBeamPassingRequest 0 "no passing requested" 1 "High Beam passing requested";
VAL_ 1146 THPNumberThermalRequest 0 "0 THP requested" 1 "1 THP requested" 2 "2 THP requested" 3 "3 THP requested" 4 "4 THP requested" 5 "5 THP requested" 6 "6 THP requested" 7 "Not used";
VAL_ 1146 ClutchSwitchMaximumTravel 0 "Not used" 1 "Clutch pedal not pressed at maximum" 2 "Clutch pedal pressed at maximum" 3 "Unavailable";
VAL_ 1147 OilPressureWarning_ECM 0 "No Oil Pressure Warning" 1 "Oil Pressure Warning";
VAL_ 1147 WarningWaterTemp 0 "no water temperature warning" 1 "water temperature warning";
VAL_ 1147 MILLamp 0 "No test of readiness codes status and Readiness Codes completed and MIL lamp off request" 1 "No test of readiness codes status and Readiness Codes completed and MIL Lamp on request" 2 "No test of readiness codes status and Readiness Codes completed and MIL lamp flash request" 3 "No test of readiness codes status and Readiness Codes completed and MIL lamp auto-test" 4 "No test of readiness codes status and Readiness codes not completed and MIL lamp off request" 5 "No test of readiness codes status and Readiness codes not completed and MIL Lamp on request" 6 "No test of readiness codes status and Readiness codes not completed and MIL lamp flash request" 7 "No test of readiness codes status and Readiness codes not completed and MIL lamp auto-test" 8 "Test of readiness codes status and Readiness Codes completed and MIL lamp off request" 9 "Test of readiness codes status and Readiness Codes completed and MIL Lamp on request" 10 "Test of readiness codes status and Readiness Codes completed and MIL lamp flash request" 11 "Test of readiness codes status and Readiness Codes completed and MIL lamp auto-test" 12 "Test of readiness codes status and Readiness codes not completed and MIL lamp off request" 13 "Test of readiness codes status and Readiness codes not completed and MIL Lamp on request" 14 "Test of readiness codes status and Readiness codes not completed and MIL lamp flash request" 15 "Test of readiness codes status and Readiness codes not completed and MIL lamp auto-test";
VAL_ 1147 ECM_OilPressureSwitchFaultDisp 0 "No oil pressure switch fault warning requested" 1 "Oil pressure switch fault warning requested";
VAL_ 1167 V2X_ICW_Direction 0 "Invalid" 1 "Left" 2 "LeftFront" 3 "Front" 4 "RightFront" 5 "Right" 6 "RightRear" 7 "Rear" 8 "LeftRear" 9 "Not used" 10 "Not used" 11 "Not used" 12 "Not used" 13 "Not used" 14 "Not used" 15 "Not used";
VAL_ 1167 V2X_VRUCW_Direction 0 "Invalid" 1 "Left" 2 "LeftFront" 3 "Front" 4 "RightFront" 5 "Right" 6 "RightRear" 7 "Rear" 8 "LeftRear" 9 "Not used" 10 "Not used" 11 "Not used" 12 "Not used" 13 "Not used" 14 "Not used" 15 "Not used";
VAL_ 1167 V2X_CurrentLaneTurnSign 0 "Invalid" 1 "Straight-Lane" 2 "Left-Lane" 3 "Right-Lane" 4 "U-turn lane" 5 "Not used" 6 "Not used" 7 "Not used";
VAL_ 1167 V2X_GLOSA_WarningState 0 "Unactivated" 1 "Activated";
VAL_ 1167 V2X_GLOSA_GoStraightLightColor 0 "Invalid" 1 "Red Light" 2 "Green Light" 3 "Yellow Light" 4 "Yellow Light Flash" 5 "Not used" 6 "Not used" 7 "Not used";
VAL_ 1167 V2X_InitCompletedFlag 0 "V2X Initialization is not complete" 1 "V2X Initialization is completed";
VAL_ 1178 PresenceStateRow2RightCollision 0 "Crash Not Detected" 1 "Absent" 2 "Present" 3 "Unknown";
VAL_ 1178 PresenceStateRow2LeftCollision 0 "Crash Not Detected" 1 "Absent" 2 "Present" 3 "Unknown";
VAL_ 1178 PresenceStateRow2CenterCollision 0 "Crash Not Detected" 1 "Absent" 2 "Present" 3 "Unknown";
VAL_ 1178 PresenceStateRow1PassCollision 0 "Crash Not Detected" 1 "Absent" 2 "Present" 3 "Unknown";
VAL_ 1178 SeatBeltStatusRow2CnterCollision 0 "SB Not monitored" 1 "SB unfastened" 2 "SB fastened" 3 "Unavailable";
VAL_ 1178 PresenceStateRow3RightCollision 0 "Crash Not Detected" 1 "Absent" 2 "Present" 3 "Unknown";
VAL_ 1178 PresenceStateRow3LeftCollision 0 "Crash Not Detected" 1 "Absent" 2 "Present" 3 "Unknown";
VAL_ 1178 PresenceStateRow3CenterCollision 0 "Crash Not Detected" 1 "Absent" 2 "Present" 3 "Unknown";
VAL_ 1178 SeatBeltStatusRow3LeftCollision 0 "SB Not monitored" 1 "SB unfastened" 2 "SB fastened" 3 "Unavailable";
VAL_ 1178 SeatBeltStatusRow3CnterCollision 0 "SB Not monitored" 1 "SB unfastened" 2 "SB fastened" 3 "Unavailable";
VAL_ 1178 SeatBeltStatusRow2RightCollision 0 "SB Not monitored" 1 "SB unfastened" 2 "SB fastened" 3 "Unavailable";
VAL_ 1178 SeatBeltStatusRow2LeftCollision 0 "SB Not monitored" 1 "SB unfastened" 2 "SB fastened" 3 "Unavailable";
VAL_ 1178 VRUCrashType 0 "VRU Crash Not Detected" 1 "Not Used" 2 "Motorcyclist" 3 "Bicyclist" 4 "Pedestrian" 5 "Unknown" 6 "Not Used" 7 "Not Used";
VAL_ 1178 VRUCrashDetectionAvailability 0 "VRU Crash Detection Unavailable" 1 "VRU Crash Deteciton Operational";
VAL_ 1178 SeatBeltStatusRow3RightCollision 0 "SB Not monitored" 1 "SB unfastened" 2 "SB fastened" 3 "Unavailable";
VAL_ 1188 NFCframe_NFC_Inside_to_VKM 0 "Table Value609465";
VAL_ 1189 BCM_Window_SwitchState_FL 0 "Window local Switch not active" 1 "Window local Switch manual up active" 2 "Window local Switch manual down active" 3 "not used" 4 "not used" 5 "Window local Switch auto up active" 6 "Window local Switch auto down active" 7 "Unavailable";
VAL_ 1189 BCM_Window_SwitchState_FR 0 "Window local Switch not active" 1 "Window local Switch manual up active" 2 "Window local Switch manual down active" 3 "not used" 4 "not used" 5 "Window local Switch auto up active" 6 "Window local Switch auto down active" 7 "Unavailable";
VAL_ 1189 BCM_Window_SwitchState_RL 0 "Window local Switch not active" 1 "Window local Switch manual up active" 2 "Window local Switch manual down active" 3 "not used" 4 "not used" 5 "Window local Switch auto up active" 6 "Window local Switch auto down active" 7 "Unavailable";
VAL_ 1189 BCM_Window_SwitchState_RR 0 "Window local Switch not active" 1 "Window local Switch manual up active" 2 "Window local Switch manual down active" 3 "not used" 4 "not used" 5 "Window local Switch auto up active" 6 "Window local Switch auto down active" 7 "Unavailable";
VAL_ 1189 VK_SSU_SwitchState 0 "Switch position invalid" 1 "SunShade Switch position 0" 2 "SunShade Switch position 1" 3 "SunShade Switch position 2" 4 "SunShade Switch position 3" 5 "SunShade Switch position 4" 6 "SunShade Switch position 5" 7 "SunShade Switch position 6" 8 "SunShade Switch position 7" 9 "SunShade Switch position 8" 10 "SunShade Switch position 9" 11 "SunShade Switch position 10" 12 "SunShade Switch position 11" 13 "SunShade Switch position 12" 14 "SunShade Switch position 13" 15 "SunShade Switch recall";
VAL_ 1189 WindowNormalized_RR 0 "LVI-AP not normalised" 1 "LVI-AP normalised (position valid)";
VAL_ 1189 WindowNormalized_RL 0 "LVI-AP not normalised" 1 "LVI-AP normalised (position valid)";
VAL_ 1189 WindowNormalized_FR 0 "LVI-AP not normalised" 1 "LVI-AP normalised (position valid)";
VAL_ 1189 WindowNormalized_FL 0 "LVI-AP not normalised" 1 "LVI-AP normalised (position valid)";
VAL_ 1189 UserIdentification_IKeyLink_v2 0 "No request" 1 "Key No. 1" 2 "Key No. 2" 3 "Key No. 3" 4 "Key No. 4" 5 "Owner Key" 6 "Friend Key ID 1" 7 "Friend Key ID 2" 8 "Friend Key ID 3" 9 "Friend Key ID 4" 10 "Friend Key ID 5" 11 "Not used" 12 "Not used" 13 "Not used" 14 "Not used" 15 "Unavailable";
VAL_ 1189 BCM_Window_ECUDefect_RR 0 "Error ECU, Relay, Hall or Motor; defect not active" 1 "Error ECU, Relay, Hall or Motor; defect active";
VAL_ 1189 BCM_Window_ECUDefect_RL 0 "Error ECU, Relay, Hall or Motor; defect not active" 1 "Error ECU, Relay, Hall or Motor; defect active";
VAL_ 1189 BCM_Window_ECUDefect_FR 0 "Error ECU, Relay, Hall or Motor; defect not active" 1 "Error ECU, Relay, Hall or Motor; defect active";
VAL_ 1189 BCM_Window_ECUDefect_FL 0 "Error ECU, Relay, Hall or Motor; defect not active" 1 "Error ECU, Relay, Hall or Motor; defect active";
VAL_ 1189 WindowThermoprotection_RR 0 "LVI-AP Thermoprotection not active" 1 "LVI-AP Thermoprotection active";
VAL_ 1189 WindowThermoprotection_RL 0 "LVI-AP Thermoprotection not active" 1 "LVI-AP Thermoprotection active";
VAL_ 1189 WindowThermoprotection_FR 0 "LVI-AP Thermoprotection not active" 1 "LVI-AP Thermoprotection active";
VAL_ 1189 WindowThermoprotection_FL 0 "LVI-AP Thermoprotection not active" 1 "LVI-AP Thermoprotection active";
VAL_ 1189 VK_SSU_ECUDefect 0 "Error ECU, Relay, Hall or Motor; defect not active" 1 "Error ECU, Relay, Hall or Motor; defect active";
VAL_ 1189 VK_SRU_Normalized 0 "SunRoof not normalized" 1 "SunRoof normalized (position valid)";
VAL_ 1189 VK_SSU_Normalized 0 "SunShade not normalized" 1 "SunShade normalized (position valid)";
VAL_ 1189 VK_SSU_Thermoprotection 0 "Thermoprotection not active" 1 "Thermoprotection active";
VAL_ 1189 VK_SRU_Thermoprotection 0 "Thermoprotection not active" 1 "Thermoprotection active";
VAL_ 1218 ConnectionData_IVC_ID 0 "Table Value420477";
VAL_ 1218 TransportContent_IVC_ID 0 "VIN" 1 "PhotoUploadPath" 2 "PhotoUploadID" 3 "Invalid value";
VAL_ 1218 DataLength_IVC_ID 0 "0" 1 "1" 2 "2" 3 "3" 4 "4" 5 "5" 6 "6" 7 "7" 8 "8" 9 "9" 10 "10" 11 "11" 12 "12" 13 "13" 14 "14" 15 "15" 16 "16" 17 "17" 18 "18" 19 "19" 20 "20" 21 "21" 22 "22" 23 "23" 24 "24" 25 "25" 26 "26" 27 "27" 28 "28" 29 "29" 30 "30" 31 "31" 32 "32" 33 "Not used" 34 "Not used" 35 "Not used" 36 "Not used" 37 "Not used" 38 "Not used" 39 "Not used" 40 "Not used" 41 "Not used" 42 "Not used" 43 "Not used" 44 "Not used" 45 "Not used" 46 "Not used" 47 "Not used" 48 "Not used" 49 "Not used" 50 "Not used" 51 "Not used" 52 "Not used" 53 "Not used" 54 "Not used" 55 "Not used" 56 "Not used" 57 "Not used" 58 "Not used" 59 "Not used" 60 "Not used" 61 "Not used" 62 "Not used" 63 "Invalid";
VAL_ 1218 HVbatteryWarmingRequest_IVC 0 "No request" 1 "Battery warming OFF request" 2 "Battery warming ON request" 3 "Reset request";
VAL_ 1218 Heavy_crash_state 0 "Unavailable" 1 "Heavy crash operation end" 2 "SOS manual push" 3 "Not Used";
VAL_ 1218 DataIndex_IVC_ID 0 "0" 1 "1" 2 "2" 3 "3" 4 "4" 5 "5" 6 "Reserved" 7 "Reserved" 8 "Reserved" 9 "Reserved" 10 "Reserved" 11 "Reserved" 12 "Reserved" 13 "Reserved" 14 "Reserved" 15 "Invalid";
VAL_ 1225 PBD_LockAndCloseSWPressed 0 "Not Pressed" 1 "Pressed";
VAL_ 1225 PBD_MovementAuthorizationState 0 "Unavailable" 1 "All movement authorize" 2 "Close Authorize" 3 "Inhibit";
VAL_ 1225 PBD_LatchStatus 0 "Unavailable" 1 "Unlatched" 2 "Latched" 3 "Half Latched";
VAL_ 1225 PBD_FailureStatus 0 "No Failure" 1 "Motor Failure" 2 "Motor Overheating" 3 "Position Failure" 4 "Touch Sens Failure" 5 "ECU Failure" 6 "Supply Failure" 7 "Not Used";
VAL_ 1225 PBD_ZoningPosition 0 "Unavailable" 1 "Full Close" 2 "Mechanical Close" 3 "Middle" 4 "Soft Full Open" 5 "Mechanical Full Open" 6 "Not Used" 7 "Not Used";
VAL_ 1225 PBD_outerSW_Status 0 "Not Pressed" 1 "Pressed";
VAL_ 1225 PBD_InnerSW_Status 0 "Not Pressed" 1 "Pressed";
VAL_ 1225 PBD_Initialization_state 0 "Not Initialized" 1 "Initialized";
VAL_ 1239 SOCLearningRequest_48V_EVA 0 "No BMS request for SOC learning" 1 "SOC learning requested";
VAL_ 1239 CloggedBattAirInletDetection_EVA 0 "Not detected" 1 "Detected";
VAL_ 1239 SOCLearningFeedback_48V_EVA 0 "no request" 1 "SOC Learning accepted/initiated" 2 "SOC learning failed" 3 "Not Used";
VAL_ 1241 CustomerIdentType 0 "Card" 1 "Personal Device";
VAL_ 1247 RecordVideoQuality_HSL 0 "High" 1 "Standard" 2 "Long time" 3 "invalid value";
VAL_ 1247 DVR_CommandRespList_Passenger 0 "enter general video" 1 "stop recorded" 2 "enter emergency video" 3 "enter general video directory" 4 "enter emergency video directory" 5 "enter picture directory" 6 "format SD" 7 "factory reset" 8 "photograph" 9 "enter inner camera" 10 "deleted file" 11 "turn on video" 12 "play/pause" 13 "enter passenger monitor" 14 "play the previous file" 15 "play the next file" 16 "exit play" 17 "filesselected 1" 18 "filesselected 2" 19 "filesselected 3" 20 "filesselected 4" 21 "filesselected 5" 22 "filesselected 6" 23 "filesselected 7" 24 "filesselected 8" 25 "passenger monitor mute" 26 "select all" 27 "cancel" 28 "previous" 29 "next" 30 "Enable Updata" 31 "invalid value";
VAL_ 1252 SCR_QltyWarningBefDISDisplay_v2 0 "No Display" 1 "System warning before DIS" 2 "Urea quality warning before DIS" 3 "Urea consumption warning before DIS";
VAL_ 1252 SCR_WarningDISDisplay 0 "NO Warning in DIS" 1 "Warning Level in DIS" 2 "Warning Quality in DIS" 3 "Unavailable";
VAL_ 1252 SCR_DISFinalWarningDisplay 0 "NO Final Warning " 1 "Final Warning Level" 2 "Final Warning Quality" 3 "Unavailable";
VAL_ 1252 ParticulateFilterState 0 "No warning message" 1 "Warning clog up filter";
VAL_ 1252 DieselFilterWaterDetection 0 "no water detected in diesel" 1 "water detected in diesel";
VAL_ 1252 SCR_DISWarningDispReactivation 0 "No DIS Warning Display Reactivation" 1 "DIS Warning Display Reactivation";
VAL_ 1252 SCR_WarningBeforeDISDisplay 0 "No Warning before DIS" 1 "Warning Level 1 before DIS" 2 "Warning Level 2 before DIS" 3 "Unavailable";
VAL_ 1252 BSG_ModeRequestDisplay 0 "Neutral" 1 "Alternator" 2 "Recranking" 3 "Torque Assist" 4 "Reserved" 5 "Reserved" 6 "Reserved" 7 "Reserved";
VAL_ 1253 EVSEscheduleStatus_v2 0 "No Schedule transmitted" 1 "Schedule #1 transmission in progress" 2 "Schedule #2 transmission in progress" 3 "Schedule #3 transmission in progress" 4 "Transmission is finished" 5 "Error" 6 "Not Used" 7 "Not Used";
VAL_ 1255 IVI_VK_Menu_operation 0 "No operation" 1 "Menu operation" 2 "Operation cancel" 3 "Owner key registration start condition check" 4 "Owner key registration start" 5 "Owner key change start condition check" 6 "Owner key change start" 7 "Owner key termination start" 8 "Friend key ID1 termination start" 9 "Friend key ID2 termination start" 10 "Friend key ID3 termination start" 11 "Friend key ID4 termination start" 12 "Friend key ID5 termination start" 13 "Friend key all termination start" 14 "Friend key list" 15 "reserved" 16 "reserved" 17 "reserved" 18 "reserved" 19 "reserved" 20 "reserved" 21 "reserved" 22 "reserved" 23 "reserved" 24 "reserved" 25 "reserved" 26 "reserved" 27 "reserved" 28 "reserved" 29 "reserved" 30 "reserved" 31 "Unavailable value";
VAL_ 1262 CartoData_IVC 0 "Table Value409418";
VAL_ 1262 OSPDataType_IVC 0 "Reserved" 1 "POSITION" 2 "SEGMENT" 3 "STUB" 4 "PROFILE SHORT" 5 "PROFILE LONG" 6 "META-DATA" 7 "Reserved";
VAL_ 1265 HeatLoopWaterValveRequest_EVA 0 "Engine loop request" 1 "Short loop request";
VAL_ 1269 OBMParameter 0 "Table Value221921";
VAL_ 1276 ACC_Status_Slow 0 "ACC OFF" 1 "ACC in take off" 2 "ACC in stop" 3 "ACC waiting" 4 "ACC suspended" 5 "ACC in brake only mode" 6 "ACC regulation" 7 "ACC driver override" 8 "ACC in failure State" 9 "Not used" 10 "Not used" 11 "Not used" 12 "Not used" 13 "Not used" 14 "Not used" 15 "Unavailable";
VAL_ 1276 ACC_LCA_DeactivationType 0 "No display" 1 "ACC Deactivation level 1" 2 "ACC Deactivation level 2" 3 "ACC Disconnected level 1" 4 "ACC Disconnected level 2" 5 "LCA  Deactivation level 1" 6 "LCA  Disconnected level 1" 7 "Not used" 8 "Not used" 9 "Not used" 10 "Not used" 11 "Not used" 12 "Not used" 13 "Not used" 14 "Not used" 15 "Not used";
VAL_ 1277 CAV_Position_FeedBack_EVA 0 "unavailable" 1 "Position 1 - Closed" 2 "Position 2" 3 "Position 3" 4 "Position 4" 5 "Position 5" 6 "Position 6 - Open" 7 "Unknown position";
VAL_ 1277 DriveLineStatus_EVA 0 "Reverse 2" 1 "Reverse 1" 2 "Neutral" 3 "Driveline 1" 4 "Driveline 2" 5 "Driveline 3" 6 "Driveline 4" 7 "Driveline 5" 8 "Driveline 6" 9 "Driveline 7" 10 "Driveline 8" 11 "Driveline 9" 12 "Driveline 10" 13 "Driveline 11" 14 "Driveline 12" 15 "Driveline 13" 16 "Driveline 14" 17 "Driveline 15" 18 "Driveline 16" 19 "Driveline 17" 20 "Driveline 18" 21 "Driveline 19" 22 "Driveline 20" 23 "Driveline 21" 24 "Driveline 22" 25 "Driveline 23" 26 "Driveline 24" 27 "Driveline 25" 28 "Driveline 26" 29 "Driveline 27" 30 "Driveline 28" 31 "Driveline 29";
VAL_ 1281 VKM_Security_Log 0 "Table Value609473";
VAL_ 1282 FrontParkAssistState 0 "Front park assistance de-activated" 1 "Front park assistance activated";
VAL_ 1282 RearParkAssistState 0 "Rear park assistance de-activated" 1 "Rear park assistance activated";
VAL_ 1292 SportUsageRequest2 0 "No request" 1 "Auto request" 2 "Forced request" 3 "Reset request";
VAL_ 1294 PersonalDevice_LowBatteryDisplay 0 "No Alert" 1 "Personal Device Low Battery Display Requested";
VAL_ 1294 VirtualKeyMenuState 0 "Not used" 1 "Activate Menu" 2 "Deactivate Menu" 3 "Not used";
VAL_ 1296 V2L_FrequencySettingRequest_IVC 0 "No request" 1 "50 Hz" 2 "60 Hz" 3 "Reset request";
VAL_ 1296 TCU_DVR_Photo_Request 0 "no request" 1 "request";
VAL_ 1296 IVI_SafeMode 0 "Not activated" 1 "Activated";
VAL_ 1296 IVI_SafeModePersistentON 0 "Persistent mode disabled" 1 "Persistent mode enabled";
VAL_ 1296 IVI_SafeModeRebootReason 0 "No message to user" 1 "Display message 1" 2 "Display message 2" 3 "Display message 3" 4 "Display message 4" 5 "Display message 5" 6 "Display message 6" 7 "Display message 7";
VAL_ 1296 V2L_SettingModeRequest_IVC 0 "No request" 1 "All OFF" 2 "System OFF" 3 "System ON" 4 "Reset request" 5 "Not Used" 6 "Not Used" 7 "Not Used";
VAL_ 1296 Heavy_crash_activate 0 "Unavailable" 1 "Heavy crash activate";
VAL_ 1296 Privacy_Display_Request 0 "No display" 1 "Data sharing forbidden" 2 "Data sharing allowed" 3 "Geolocation sharing forbidden" 4 "Reserved" 5 "Reserved" 6 "Reserved" 7 "Unavailable";
VAL_ 1296 Privacy_Mode_State 0 "Data Sharing forbidden" 1 "Data Sharing allowed" 2 "Geolocation Sharing forbidden" 3 "Reserved" 4 "Reserved" 5 "Reserved" 6 "Reserved" 7 "Unavailable";
VAL_ 1296 V2X_SOClimitationLevelReq_IVC 126 "No request" 127 "Reset request";
VAL_ 1296 VirtualKeySuspendReq3 0 "No Request" 1 "VK Suspend" 2 "VK Resume" 3 "Not Used";
VAL_ 1300 EngContHighestReqEnergAuth_EVA 0 "No Highest Priority Request (inactive value)" 1 "Highest Priority Request Authorized" 2 "Highest Priority Request NOT Authorized" 3 "Not used";
VAL_ 1300 EngContCurrentFamilyReq_EVA 0 "NO « Engine Control » Request" 1 "First Catalyst Warm-up (step1 / Step2)" 2 "Catalyst Warm-up Maintain" 3 "ICE coolant temperature increase (ex EGVR extended)" 4 "GPF warm-up" 5 "GPF Cooling" 6 "GPF Forced Motoring" 7 "GPF runaway protection (FCOI)" 8 "OSC depoll learning" 9 "OBD with Combustion" 10 "OBD without combustion" 11 "Canister Charge learning" 12 "Torque Meter Fast Learning" 13 "Torque Meter Slow Learning" 14 "1st start factory" 15 "GPF after sale regeneration" 16 "Catalyst after sale diagnosis" 17 "Not Used" 18 "Not Used" 19 "Not Used" 20 "Not used" 21 "Not used" 22 "Not used" 23 "Not used" 24 "Not used" 25 "Not used" 26 "Not used" 27 "Not used" 28 "Not used" 29 "Not used" 30 "Not used" 31 "Not used";
VAL_ 1301 RemoteFunctionService_HFM_to_BLM 0 "Table Value29850";
VAL_ 1302 RemoteFunctionService_BLM_to_HFM 0 "Table Value29849";
VAL_ 1303 OverSpeedWarningSound 0 "Not requested" 1 "Requested";
VAL_ 1303 TSR_OSP_SpeedSignalZone1 254 "Free speed' Symbol" 255 "No Speed available show ---";
VAL_ 1303 TSR_OSP_SpeedSignalZone2 254 "Free speed' Symbol" 255 "No Speed available show ---";
VAL_ 1303 OSPOverSpeedDisplayRequest 0 "No Overspeed alert" 1 "OverSpeedAlert";
VAL_ 1303 TSR_OSP_FailureDisplay 0 "No display" 1 "Temporary failure display" 2 "Permanent failure display" 3 "Not used";
VAL_ 1306 HFM_BLM_pairing 0 "Table Value29848";
VAL_ 1308 BLM_HFM_pairing 0 "Table Value29845";
VAL_ 1319 DMC_AlertStatus 0 "No display" 1 "Blink(working)" 2 "Steady(failure)" 3 "Reserved";
VAL_ 1326 SmallCrash_Impact 0 "No Crash" 1 "Front impact" 2 "Left side impact" 3 "Right side impact" 4 "Rear crash impact" 5 "Not used" 6 "Not used" 7 "Not used";
VAL_ 1330 SDCardStatus 0 "SD insert" 1 "SD pull out" 2 "SD failure" 3 "SD full" 4 "emergency video full" 5 "photo full" 6 "emergency video and photo full" 7 "Need format";
VAL_ 1330 DVRWorkStatus 0 "general recording mode" 1 "stop recording mode" 2 "manually start emergency video mode" 3 "auto start emergency video mode" 4 "general video list mode" 5 "emergency video list mode" 6 "photo list mode" 7 "video file playing status" 8 "video file paused status" 9 "photo file playing status" 10 "video playing end" 11 "power off status" 12 "system failure" 13 "inside monitoring mode" 14 "file is exporting" 15 "invalid value";
VAL_ 1330 PhotoReady 0 "pictures are ready" 1 "No picture";
VAL_ 1330 CollideCheckStatus 0 "turn off collision detection" 1 "turn on collision detection" 2 "reserved" 3 "invalid value";
VAL_ 1330 ParkingMonitor 0 "turn off parking monitoring" 1 "turn on parking monitoring" 2 "reserved" 3 "invalid value";
VAL_ 1330 CollideSensitivityStatus 0 "low sensibility" 1 "medium sensibility" 2 "high sensibility" 3 "invalid value";
VAL_ 1330 MuteRecordStatus 0 "turn off recording" 1 "turn on recording" 2 "reserved" 3 "invalid value";
VAL_ 1330 RecordVideoQuality 0 "1080P-30fps" 1 "720P-30fps" 2 "reserved" 3 "invalid value";
VAL_ 1330 RecordTime 0 "1min" 1 "3min" 2 "5min" 3 "invalid value";
VAL_ 1330 DVR_Collision_Status 0 "Not collision" 1 "Collision";
VAL_ 1330 AutoACC2_ON_Request_DVR 0 "No request" 1 "AutoACC2 requested";
VAL_ 1331 DVR_CommandResult 0 "Command reception success" 1 "Command reception Failed" 2 "Successful implementation" 3 "Execution failure" 4 "reserved" 5 "reserved" 6 "reserved" 7 "invalid value";
VAL_ 1331 DVR_CommandRespList_2 0 "Taking inner camera photo" 1 "Taking inner camera video" 2 "Fast forward 10 sec" 3 "Fast forward 20 sec" 4 "Fast rewind 10 sec" 5 "Fast rewind 20 sec" 6 "Play back progress 0%" 7 "Play back progress 10%" 8 "Play back progress 20%" 9 "Play back progress 30%" 10 "Play back progress 40%" 11 "Play back progress 50%" 12 "Play back progress 60%" 13 "Play back progress 70%" 14 "Play back progress 80%" 15 "Play back progress 90%" 16 "Play back progress 100%" 17 "Not Used" 18 "Not Used" 19 "Not Used" 20 "Not Used" 21 "Not Used" 22 "Not Used" 23 "Not Used" 24 "Not Used" 25 "Not Used" 26 "Not Used" 27 "Not Used" 28 "Not Used" 29 "Not Used" 30 "Not Used" 31 "Not Used";
VAL_ 1331 DVR_RemoteCommandResult 0 "Successful implementation" 1 "Execution failure" 2 "reserved" 3 "invalid value";
VAL_ 1332 AIRBAGMalfunction 0 "no AIRBAG system malfunction" 1 "AIRBAG system malfunction";
VAL_ 1332 CrashDetectionOutOfOrder_v2 0 "Detection functional" 1 "Malfunction for rear crash" 2 "Malfunction for side or front crash" 3 "Malfunction for crash detection";
VAL_ 1332 CrashDetected_v2 0 "Reserved for safety" 1 "No crash detected" 2 "Crash detected" 3 "Reserved for safety";
VAL_ 1332 SecondRowCenterPresenceState 0 "Not monitored" 1 "Present" 2 "Absent" 3 "Unknown";
VAL_ 1332 RolloverDetectionMalfunction 0 "Normal rollover detection functional " 1 "Malfunction for rollover detection";
VAL_ 1332 PassengerSafetyBeltBuckleState 0 "SB Not monitored" 1 "SB unfastened" 2 "SB fastened" 3 "Unavailable";
VAL_ 1332 PassengerPresenceState 0 "Not monitored" 1 "Present" 2 "Absent" 3 "Unknown";
VAL_ 1332 SecondRowRightPresenceState 0 "Not monitored" 1 "Present" 2 "Absent" 3 "Unknown";
VAL_ 1332 SecondRowLeftSafetyBeltState 0 "SB not monitored" 1 "SB unfastened" 2 "SB fastened" 3 "Unavailable";
VAL_ 1332 SecondRowLeftPresenceState 0 "Not monitored" 1 "Present" 2 "Absent" 3 "Unknown";
VAL_ 1332 SecondRowCenterSafetyBeltState 0 "SB not monitored" 1 "SB unfastened" 2 "SB fastened" 3 "Unavailable";
VAL_ 1332 ThirdRowLeftPresenceState 0 "Not monitored" 1 "Present" 2 "Absent" 3 "Unknown";
VAL_ 1332 ThirdRowCenterSafetyBeltState 0 "SB not monitored" 1 "SB unfastened" 2 "SB fastened" 3 "Unavailable";
VAL_ 1332 ThirdRowCenterPresenceState 0 "Not monitored" 1 "Present" 2 "Absent" 3 "Unknown";
VAL_ 1332 SecondRowRightSafetyBeltState 0 "SB not monitored" 1 "SB unfastened" 2 "SB fastened" 3 "Unavailable";
VAL_ 1332 FirstRowCenterPresenceState 0 "Not monitored" 1 "Present" 2 "Absent" 3 "Unknown";
VAL_ 1332 ThirdRowRightSafetyBeltState 0 "SB not monitored" 1 "SB unfastened" 2 "SB fastened" 3 "Unavailable";
VAL_ 1332 ThirdRowRightPresenceState 0 "Not monitored" 1 "Present" 2 "Absent" 3 "Unknown";
VAL_ 1332 ThirdRowLeftSafetyBeltState 0 "SB not monitored" 1 "SB unfastened" 2 "SB fastened" 3 "Unavailable";
VAL_ 1332 PassengerAIRBAG_Inhibition_v2 0 "No display" 1 "Passenger AIRBAG not inhibited" 2 "Passenger AIRBAG inhibited" 3 "Not used";
VAL_ 1332 FirstRowCenterSafetyBeltState 0 "SB Not monitored" 1 "SB unfastened" 2 "SB fastened" 3 "Unavailable";
VAL_ 1339 TimeWeekDay 0 "Monday" 1 "Tuesday" 2 "Wednesday" 3 "Thursday" 4 "Friday" 5 "Saturday" 6 "Sunday" 7 "Unavailable";
VAL_ 1343 HEVC_PresoakRequest 0 "Immediat Presoak Request" 1 "Programmed Presoak Request" 2 "Presoak Stop" 3 "Unavailable";
VAL_ 1349 PnCactivationRequest_IVC 0 "No request" 1 "Activation request" 2 "Desactivation request" 3 "Not Used";
VAL_ 1354 PSD_R_ActivationState 0 "No activation" 1 "Opening_movement_ongoing" 2 "Closing_movement_ongoing" 3 "Movement_delayed" 4 "Antipinch_movement_ongoing" 5 "Not Used" 6 "Not Used" 7 "Not Used";
VAL_ 1358 ME_PwtThermalControlRequest_EVA 0 "Normal" 1 "Maximize powertrain thermal exchanges" 2 "Maximize powertrain thermal exchanges + generate losses" 3 "Improve powertrain thermal exchanges" 4 "Improve powertrain thermal exchanges + generate losses" 5 "Not Used" 6 "Not Used" 7 "Not Used";
VAL_ 1367 V2X_ID8_CLW_ActivationState 0 "Unactivated" 1 "Activated";
VAL_ 1367 V2X_Warning_VehicleType 0 "Invalid" 1 "Bus" 2 "Truck" 3 "Patrol Wagon" 4 "Ambulance" 5 "Fire Truck" 6 "Other Emergency Vehicle" 7 "CommonVehicle";
VAL_ 1367 V2X_LTA_WarningState 0 "Invalid" 1 "Warning Trigger";
VAL_ 1367 V2X_ICW_WarningState 0 "Invalid" 1 "Warning Trigger";
VAL_ 1367 V2X_CLW_WarningState 0 "Invalid" 1 "Warning Trigger";
VAL_ 1367 V2X_FCW_WarningState 0 "Invalid" 1 "Warning Trigger";
VAL_ 1367 V2X_ID12_VRUCW_ActivationState 0 "Unactivated" 1 "Activated";
VAL_ 1367 V2X_ID11_RLVW_ActivationState 0 "Unactivated" 1 "Activated";
VAL_ 1367 V2X_CLW_ControlLossType 0 "Invalid" 1 "ABS Loss Control" 2 "ESP Loss Control" 3 "TCS Loss Control" 4 "LDW Loss Control" 5 "Not used" 6 "Not used" 7 "Not used";
VAL_ 1367 V2X_RLVW_WarningState 0 "Invalid" 1 "Warning Trigger";
VAL_ 1367 V2X_VRUCW_WarningState 0 "Invalid" 1 "Warning Trigger";
VAL_ 1367 V2X_AVW_WarningState 0 "Invalid" 1 "Warning Trigger";
VAL_ 1367 V2X_MalfunctionState 0 "No Malfunction" 1 "Malfunction";
VAL_ 1367 V2X_ID16_GLOSA_ActivationState 0 "Unactivated" 1 "Activated";
VAL_ 1367 V2X_ID7_AVW_ActivationState 0 "Unactivated" 1 "Activated";
VAL_ 1367 V2X_ID3_LTA_ActivationState 0 "Unactivated" 1 "Activated";
VAL_ 1367 V2X_ID2_ICW_ActivationState 0 "Unactivated" 1 "Activated";
VAL_ 1367 V2X_ID1_FCW_ActivationState 0 "Unactivated" 1 "Activated";
VAL_ 1367 V2X_VRUCW_UserType 0 "Invalid" 1 "Pedestrian" 2 "Bike" 3 "Motorbike";
VAL_ 1367 V2X_SubFunctionSwitchState 0 "Table Value221794";
VAL_ 1367 PnCContCertifInstMng 0 "No request (Default value)" 1 "Install Contract Certificate #1" 2 "Install Contract Certificate #2" 3 "Install Contract Certificate #3" 4 "Install Contract Certificate #4" 5 "Install Contract Certificate #5" 6 "Install Contract Certificate #6" 7 "Install Contract Certificate #7" 8 "Install Contract Certificate #8" 9 "Install Contract Certificate #9" 10 "Install Contract Certificate #10" 11 "Uninstall Contract Certificate #1" 12 "Uninstall Contract Certificate #2" 13 "Uninstall Contract Certificate #3" 14 "Uninstall Contract Certificate #4" 15 "Uninstall Contract Certificate #5" 16 "Uninstall Contract Certificate #6" 17 "Uninstall Contract Certificate #7" 18 "Uninstall Contract Certificate #8" 19 "Uninstall Contract Certificate #9" 20 "Uninstall Contract Certificate #10" 21 "Not used" 22 "Not used" 23 "Not used" 24 "Not used" 25 "Not used" 26 "Not used" 27 "Not used" 28 "Not used" 29 "Not used" 30 "Not used" 31 "Unavailable";
VAL_ 1367 V2X_GLOSA_LeftTurnLightColor 0 "Invalid" 1 "Red Light" 2 "Green Light" 3 "Yellow Light" 4 "Yellow Light Flash" 5 "Not used" 6 "Not used" 7 "Not used";
VAL_ 1367 V2X_GLOSA_RightTurnLightColor 0 "Invalid" 1 "Red Light" 2 "Green Light" 3 "Yellow Light" 4 "Yellow Light Flash" 5 "Not used" 6 "Not used" 7 "Not used";
VAL_ 1367 V2X_MainFunctionSwitchState 0 "V2X Main SwitchState OFF" 1 "V2X Main SwitchState ON";
VAL_ 1367 PnCProV2GCertifInstMng 0 "No request (Default value)" 1 "Install Provisioning Certificate" 2 "Install V2G Root #1 Certificate" 3 "Install V2G Root #2 Certificate" 4 "Install V2G Root #3 Certificate" 5 "Install V2G Root #4 Certificate" 6 "Install V2G Root #5 Certificate" 7 "Uninstall Provisioning Certificate" 8 "Uninstall V2G Root #1 Certificate" 9 "Uninstall V2G Root #2 Certificate" 10 "Uninstall V2G Root #3 Certificate" 11 "Uninstall V2G Root #4 Certificate" 12 "Uninstall V2G Root #5 Certificate" 13 "Not used" 14 "Not used" 15 "Unavailable";
VAL_ 1369 OSE_RearRightDoorAlert 0 "No alert" 1 "Level1" 2 "Level2" 3 "Not Used";
VAL_ 1369 OSE_RearLeftDoorAlert 0 "No alert" 1 "Level1" 2 "Level2" 3 "Not Used";
VAL_ 1369 OSE_FrontLeftDoorAlert 0 "No alert" 1 "Level1" 2 "Level2" 3 "Not Used";
VAL_ 1369 OSE_FronRightDoorAlert 0 "No alert" 1 "Level1" 2 "Level2" 3 "Not Used";
VAL_ 1369 ELKA_AlertLeftRequest 0 "No Alert" 1 "Oncoming Alert level 1" 2 "Oncoming Alert level 2" 3 "Overtaking Alert level 1" 4 "Overtaking Alert level 2" 5 "Roadedge Alert level 1" 6 "Roadedge Alert level 2" 7 "Alert reminder";
VAL_ 1369 ELKA_AlertRightRequest 0 "No Alert" 1 "Oncoming Alert level 1" 2 "Oncoming Alert level 2" 3 "Overtaking Alert level 1" 4 "Overtaking Alert level 2" 5 "Roadedge Alert level 1" 6 "Roadedge Alert level 2" 7 "Alert reminder";
VAL_ 1369 ELKA_ActivationState 0 "Activated" 1 "Deactivated";
VAL_ 1373 PreSoakBatteryHeatingReq_IVC_v2 0 "No Request" 1 "Battery heating OFF request" 2 "Battery heating ON request" 3 "Not Used";
VAL_ 1373 PreSoakAirPurifierRequest_IVC_v2 0 "No Request" 1 "Air purifier OFF request" 2 "Air purifier ON request" 3 "Not Used";
VAL_ 1373 PreSoak_eACmodeRequest_IVC_v2 0 "No Request" 1 "Normal request" 2 "Quick request" 3 "Not Used";
VAL_ 1373 PreSoakFRseatRequest_IVC_v2 0 "No Request" 1 "Heater OFF request" 2 "Heater ON request" 3 "Ventilated OFF request" 4 "Ventilated ON request" 5 "Not Used" 6 "Not Used" 7 "Not Used";
VAL_ 1373 PreSoakFrontDefrostReq_IVC_v2 0 "No Request" 1 "Front defrost OFF request" 2 "Front defrost ON request" 3 "Not Used";
VAL_ 1373 PreSoakFLseatRequest_IVC_v2 0 "No Request" 1 "Heater OFF request" 2 "Heater ON request" 3 "Ventilated OFF request" 4 "Ventilated ON request" 5 "Not Used" 6 "Not Used" 7 "Not Used";
VAL_ 1373 PreSoakSecondRLseatReq_IVC_v2 0 "No Request" 1 "Heater OFF request" 2 "Heater ON request" 3 "Ventilated OFF request" 4 "Ventilated ON request" 5 "Not Used" 6 "Not Used" 7 "Not Used";
VAL_ 1373 PreSoakHeatedStrgWheelReq_IVC_v2 0 "No Request" 1 "Heated steering wheel OFF request" 2 "Heated steering wheel ON request" 3 "Not Used";
VAL_ 1373 PreSoakSecondRCseatReq_IVC_v2 0 "No Request" 1 "Heater OFF request" 2 "Heater ON request" 3 "Ventilated OFF request" 4 "Ventilated ON request" 5 "Not Used" 6 "Not Used" 7 "Not Used";
VAL_ 1373 PreSoakThirdRLseatRequest_IVC_v2 0 "No Request" 1 "Heater OFF request" 2 "Heater ON request" 3 "Ventilated OFF request" 4 "Ventilated ON request" 5 "Not Used" 6 "Not Used" 7 "Not Used";
VAL_ 1373 PreSoakHVACfunctionsReq_IVC_v2 0 "No Request" 1 "Cabin air conditioning/heating OFF request" 2 "Cabin air conditioning/heating ON request" 3 "Not Used";
VAL_ 1373 PreSoakSecondRRseatReq_IVC_v2 0 "No Request" 1 "Heater OFF request" 2 "Heater ON request" 3 "Ventilated OFF request" 4 "Ventilated ON request" 5 "Not Used" 6 "Not Used" 7 "Not Used";
VAL_ 1373 PreSoakRearDefrostRequest_IVC_v2 0 "No Request" 1 "Rear defrost OFF request" 2 "Rear defrost ON request" 3 "Not Used";
VAL_ 1373 PreSoakThirdRRseatRequest_IVC_v2 0 "No Request" 1 "Heater OFF request" 2 "Heater ON request" 3 "Ventilated OFF request" 4 "Ventilated ON request" 5 "Not Used" 6 "Not Used" 7 "Not Used";
VAL_ 1376 RE_InverterFaultType 0 "No Fault Type" 1 "Fault Type 1" 2 "Fault Type 2" 3 "Fault Type 3" 4 "Fault Type 4" 5 "Fault Type 5" 6 "Fault Type 6" 7 "Not Used";
VAL_ 1376 ChargeTimeDisplayAtEPrct 0 "No Display";
VAL_ 1376 ME_InverterFaultType 0 "No Fault type" 1 "Fault type 1" 2 "Fault type 2" 3 "Safety Reserved" 4 "Fault type 3" 5 "Fault type 4" 6 "Fault type 5" 7 "Fault type 6";
VAL_ 1380 TripUnitConsumption 0 "L / 100 km and kWh/100km" 1 "Km / L and km/kWh" 2 "MPGus and M/kWh (MPGe)" 3 "MPGuk and M/kWh (MPGe)" 4 "KWh / 100 Km" 5 "KWh / 100 miles" 6 "MPGe (US)" 7 "MPGe (UK)";
VAL_ 1380 TripUnitDistance 0 "Km" 1 "Miles" 2 "not used" 3 "not used";
VAL_ 1381 CTA_AlertStatus 0 "No alert" 1 "Right alert" 2 "Left alert" 3 "Right and Left alert";
VAL_ 1384 MexModeState_v3 0 "Unavailable" 1 "MEX MODE ECO" 2 "MEX MODE MUD" 3 "MEX MODE MY SENSE" 4 "MEX MODE SPORT" 5 "Reserved" 6 "MEX MODE ECOPLUS" 7 "MEX MODE SNOW" 8 "MEX MODE OFFROAD" 9 "MEX MODE ALLROADS" 10 "MEX MODE PERSO" 11 "MEX MODE SAND" 12 "MEX MODE RACE" 13 "MEX MODE NORMAL" 14 "MEX MODE EXTREM" 15 "MEX MODE PERFO";
VAL_ 1386 PresoakProg_HVACmode 0 "No Presoak Programmed" 1 "Presoak programmed in progress" 2 "Not used" 3 "Unavailable";
VAL_ 1390 BusbarUnscrewingAlert 0 "No busbar unscrewing alert" 1 "Busbar unscrewing alert";
VAL_ 1392 IVI_SafeModeAck 0 "Not activated" 1 "Activated";
VAL_ 1392 WDA_ActivationRequest2 0 "No request" 1 "Activation request" 2 "Deactivation request" 3 "Reset request";
VAL_ 1392 VirtualKeySuspendReq2 0 "No Request" 1 "VK Suspend" 2 "VK Resume" 3 "VK Factory Reset (Switch to Default VK State)";
VAL_ 1395 ePedalModeDisplayRequest 0 "No display" 1 "ePedal Mode Active ON";
VAL_ 1398 ChargingStationComType 0 "AC Basic" 1 "AC HLC ISO15118" 2 "DC Combo basic" 3 "DC Combo HLC ISO15118" 4 "DC CHAdeMO" 5 "DC GB/T" 6 "AC BPT Dynamic" 7 "Unavailable";
VAL_ 1398 V2G_ActivationState 0 "Charge Service not activated" 1 "Charge Service activated" 2 "Charge Service deactivated due to an error" 3 "Charge Service deactivated due to certificate error" 4 "Charge Service deactivated due to durability inhibition" 5 "Charge Service activated and V2G session ongoing" 6 "unavailable" 7 "Charge service activated and waiting for resume";
VAL_ 1399 RE_ElecPowertrainMngtState_EVA 0 "INITIALIZING" 1 "STANDBY (Idle Mode + Disconnected)" 2 "TORQUE CONTROL" 3 "SHIFTING IN PROGRESS" 4 "ZERO TORQUE" 5 "FAILSAFE" 6 "Not used" 7 "Unavailable Value";
VAL_ 1399 RE_DeactivationStatus_48V_EVA 0 "ME Stopped" 1 "Normal" 2 "Zero-torque regulation" 3 "Invalid";
VAL_ 1399 RE_GearKinematicStateTarget_EVA 0 "Neutral" 1 "GearRatio 1" 2 "GearRatio 2" 3 "Invalid";
VAL_ 1399 RE_GearKinematicStateCurrent_EVA 0 "Neutral" 1 "Gear 1 engaged" 2 "Gear 2 engaged" 3 "Shifting in Progress" 4 "Invalid" 5 "Not used" 6 "Not used" 7 "Not used";
VAL_ 1399 RE_MajorElecFailureDisplay_EVA 0 "No Alert" 1 "Alert";
VAL_ 1402 LDW_SensibilityState 0 "Unavailable" 1 "Low sensibility" 2 "Middle sensibility" 3 "High sensibility";
VAL_ 1402 LDW_ActivationState_v3 0 "Unavailable" 1 "Activated" 2 "Deactivated" 3 "Not used";
VAL_ 1402 LDW_StatusDisplay_v2 0 "No display" 1 "Not operational" 2 "Operational" 3 "Temporary failure" 4 "Permanent failure" 5 "OFF Value" 6 "Not Used" 7 "Not Used";
VAL_ 1402 EcallRequest 0 "No request" 1 "Request";
VAL_ 1405 RPK_VKActivateRequest 0 "No Request" 1 "VK Activate Request";
VAL_ 1405 RPK_ModeRequest 0 "Normal Mode Request" 1 "RPK Mode Request" 2 "RPK Register Mode Request" 3 "Not Used";
VAL_ 1415 FAPK_SelectedManeuverTypeRequest 0 "no request" 1 "park in / parallel" 2 "park in / perpendicular" 3 "park in / angled" 4 "park out" 5 "mode auto" 6 "Not Used" 7 "Not Used";
VAL_ 1415 Distract_ShieldActivationState2 0 "Deactivated" 1 "Activated";
VAL_ 1415 AVM_LayoutDisplayRequest_3 0 "no message" 1 "Layout 1" 2 "Layout 2" 3 "Layout 3" 4 "Layout 4" 5 "Layout 5" 6 "Layout 6" 7 "Layout 7" 8 "Layout 8" 9 "Layout 9" 10 "Layout 10" 11 "Layout 11" 12 "Layout 12" 13 "Layout 13" 14 "Layout 14" 15 "Layout 15" 16 "Layout 16" 17 "Layout 17" 18 "Layout 18" 19 "Layout 19" 20 "Layout 20" 21 "Layout 21" 22 "Layout 22" 23 "Layout 23" 24 "Layout 24" 25 "Layout 25" 26 "Layout 26" 27 "Layout 27" 28 "Layout 28" 29 "Layout 29" 30 "Layout 30" 31 "Layout 31";
VAL_ 1415 Fatigue_ShieldActivationState2 0 "Deactivated" 1 "Activated";
VAL_ 1415 AVM_LayoutVideoStatus_3 0 "No display (unavailable)" 1 "Layout 1" 2 "Layout 2" 3 "Layout 3" 4 "Layout 4" 5 "Layout 5" 6 "Layout 6" 7 "Layout 7" 8 "Layout 8" 9 "Layout 9" 10 "Layout 10" 11 "Layout 11" 12 "Layout 12" 13 "Layout 13" 14 "Layout 14" 15 "Layout 15" 16 "Layout 16" 17 "Layout 17" 18 "Layout 18" 19 "Layout 19" 20 "Layout 20" 21 "Layout 21" 22 "Layout 22" 23 "Layout 23" 24 "Layout 24" 25 "Layout 25" 26 "Layout 26" 27 "Layout 27" 28 "Layout 28" 29 "Layout 29" 30 "Layout 30" 31 "Layout 31";
VAL_ 1422 MC_ActivationState 0 "Magic Cockpit OFF" 1 "Magic Cockpit ON";
VAL_ 1422 MC_TutorialState 0 "Not Done" 1 "Done";
VAL_ 1436 HFP_SelectedManeuverType 0 "unavailable" 1 "park in / parallel" 2 "park in / perpendicular" 3 "park in / angled" 4 "park out" 5 "Not used" 6 "Not used" 7 "Not used";
VAL_ 1436 HFP_DefaultManeuverType 0 "unavailable" 1 "park in / parallel" 2 "park in / perpendicular" 3 "park in / angled" 4 "park out" 5 "Not used" 6 "Not used" 7 "Not used";
VAL_ 1436 HFP_MapContentDisplay 0 "Empty Display" 1 "scanning Display" 2 "parkOutConfirmation Display" 3 "guidance Display" 4 "Not used" 5 "Not used" 6 "Not used" 7 "unavailable";
VAL_ 1436 HFP_ExtendedInstrContentDisplay 0 "instruction 1" 1 "instruction 2" 2 "instruction 3" 3 "instruction 4" 4 "instruction 5" 5 "instruction 6" 6 "instruction 7" 7 "instruction 8" 8 "instruction 9" 9 "instruction 10" 10 "instruction 11" 11 "instruction 12" 12 "instruction 13" 13 "instruction 14" 14 "Instruction 15" 15 "Instruction 16" 16 "Instruction 17" 17 "Instruction 18" 18 "Instruction 19" 19 "instruction 20" 20 "Instruction 21" 21 "Instruction 22" 22 "Instruction 23" 23 "Instruction 24" 24 "Instruction 25" 25 "Instruction 26" 26 "Instruction 27" 27 "Instruction 28" 28 "Instruction 29" 29 "Instruction 30" 30 "Instruction 31" 31 "Unavailable";
VAL_ 1455 VirtualKey_LowBatteryDisplay 0 "No Request" 1 "Display Request";
VAL_ 1455 VirtualKeyGen2MenuState 0 "No display request" 1 "Go back to top menu" 2 "Cancel operation" 3 "Registration Start Condition not satisfied - pairing password" 4 "Registration Start Condition not satisfied - key fob" 5 "Registration Start Condition satisfied" 6 "Display pairing password for Owner Key Registration" 7 "Registration communication not started" 8 "Paring password not correct (Owner Key Registration)" 9 "Registration communication in progress" 10 "Registration communication error detected" 11 "Registration completed" 12 "Unpairing Start Condition not satisfied" 13 "Unpairing completed" 14 "Owner Key Change Start Condition not satisfied - pairing password" 15 "Owner Key Change Start Condition not satisfied - key fob" 16 "Owner Key Change Start Condition satisfied" 17 "Display pairing password for Owner Key Change" 18 "Owner Key Change communication not started" 19 "Paring password not correct (Owner Key Change)" 20 "Owner Key Change communication in progress" 21 "Owner Key Change communication error detected" 22 "Owner Key Change completed" 23 "Friend key termination Start Condition not satisfied" 24 "FriendKey1 termination completed" 25 "FriendKey2 termination completed" 26 "FriendKey3 termination completed" 27 "FriendKey4 termination completed" 28 "FriendKey5 termination completed" 29 "All Friend key termination completed" 30 "Display friend key list for owner" 31 "Display friend key list for friend" 32 "Reserved" 33 "Reserved" 34 "Reserved" 35 "Reserved" 36 "Reserved" 37 "Reserved" 38 "Reserved" 39 "Reserved" 40 "Reserved" 41 "Reserved" 42 "Reserved" 43 "Reserved" 44 "Reserved" 45 "Reserved" 46 "Reserved" 47 "Reserved" 48 "Reserved" 49 "Reserved" 50 "Reserved" 51 "Reserved" 52 "Reserved" 53 "Reserved" 54 "Reserved" 55 "Reserved" 56 "Reserved" 57 "Reserved" 58 "Reserved" 59 "Reserved" 60 "Reserved" 61 "Reserved" 62 "Reserved" 63 "Unavailable value";
VAL_ 1455 VK_AuthInformation 0 "Not used" 1 "Authentication OK" 2 "Authentication NG" 3 "Unavailable";
VAL_ 1455 VK_RegistInformation 0 "Not used" 1 "VK Registered" 2 "VK Unregistered" 3 "Unavailable";
VAL_ 1455 VKM_RPKMode 0 "RPK Mode OFF" 1 "RPK Mode ON";
VAL_ 1456 State_of_ImmediateChargingSW 0 "Not activated immediate charging SW" 1 "Activated immediate charging SW";
VAL_ 1458 HVB_OverChargingAlert 0 "No Alert" 1 "Battery over-charging alert";
VAL_ 1458 HVB_CellUnderVoltageAlert 0 "Normal" 1 "Cell undervoltage alert";
VAL_ 1458 HVB_CellOverVoltageAlert 0 "Normal" 1 "Cell overvoltage alert";
VAL_ 1458 PnCHEVCauthorizationReq 0 "EIM session requested" 1 "PnC session requested" 2 "Not Used" 3 "Unavailable";
VAL_ 1458 RE_ElecSysFailureDisplay_EVA 0 "No Alert" 1 "Alert";
VAL_ 1458 SportUsageMPUState 0 "MPU disable" 1 "MPU enable";
VAL_ 1458 SportUsageActivationState 0 "Auto requested" 1 "Forced requested";
VAL_ 1458 SportDrivingDetection 0 "No detection / Not available" 1 "Sporty driving detected";
VAL_ 1458 SportModeThmgtRequest 0 "No sport mode activation request" 1 "sport mode activation boost 1" 2 "sport mode activation boost 2" 3 "Not used";
VAL_ 1459 AVM_LayoutVideoStatus 0 "No display (unavailable)" 1 "Layout1" 2 "Layout2" 3 "Layout3" 4 "Layout4" 5 "Layout5" 6 "Layout6" 7 "Layout7" 8 "Layout8" 9 "Layout9" 10 "Layout10" 11 "Layout11" 12 "Layout12" 13 "Layout13" 14 "Layout14" 15 "Layout15" 16 "Layout16" 17 "Layout17" 18 "Layout18" 19 "Layout19" 20 "Layout20" 21 "Layout21" 22 "Layout22" 23 "Layout23" 24 "Layout24" 25 "Layout25" 26 "Layout26" 27 "Layout27" 28 "Layout28" 29 "Layout29" 30 "Layout30" 31 "Layout31";
VAL_ 1459 AVM_LayoutDisplayRequest 0 "No message" 1 "Layout 1" 2 "Layout 2" 3 "Layout 3" 4 "Layout 4" 5 "Layout 5" 6 "Layout 6" 7 "Layout 7" 8 "Layout 8" 9 "Layout 9" 10 "Layout 10" 11 "Layout 11" 12 "Layout 12" 13 "Layout 13" 14 "Layout 14" 15 "Layout 15" 16 "Layout 16" 17 "Layout 17" 18 "Layout 18" 19 "Layout 19" 20 "Layout 20" 21 "Layout 21" 22 "Layout 22" 23 "Layout 23" 24 "Layout 24" 25 "Layout 25" 26 "Layout 26" 27 "Layout 27" 28 "Layout 28" 29 "Layout 29" 30 "Layout 30" 31 "Layout 31";
VAL_ 1462 ClimFrontDefrostDisplay 0 "No display" 1 "Front defrost ON" 2 "Front defrost OFF" 3 "Not Used";
VAL_ 1464 DriverSeatMemoRecallReq 0 "No recall" 1 "Recall of memorization 1" 2 "Recall of memorization 2" 3 "Recall of memorization 3" 4 "Recall of memorization 4" 5 "Recall of memorization 5" 6 "Recall of memorization 6" 7 "Reset Request";
VAL_ 1464 DriverSeatMemoRequest 0 "No request of memorization" 1 "Request of memorization 1" 2 "Request of memorization 2" 3 "Request of memorization 3" 4 "Request of memorization 4" 5 "Request of memorization 5" 6 "Request of memorization 6" 7 "Reset Request";
VAL_ 1464 DriverEasyAccessRequest2 0 "No request" 1 "Easy access activation requested" 2 "Easy access de-activation requested" 3 "Reset Request";
VAL_ 1465 FrontRightSeatRequest 0 "No request" 1 "OFF request" 2 "Heater Low request" 3 "Heater Middle request" 4 "Heater High request" 5 "Ventilated Low request" 6 "Ventilated Middle request" 7 "Ventilated High request" 8 "Reset request" 9 "Not Used" 10 "Not Used" 11 "Not Used" 12 "Not Used" 13 "Not Used" 14 "Not Used" 15 "Not Used";
VAL_ 1465 FrontLeftSeatRequest 0 "No request" 1 "OFF request" 2 "Heater Low request" 3 "Heater Middle request" 4 "Heater High request" 5 "Ventilated Low request" 6 "Ventilated Middle request" 7 "Ventilated High request" 8 "Reset request" 9 "Not Used" 10 "Not Used" 11 "Not Used" 12 "Not Used" 13 "Not Used" 14 "Not Used" 15 "Not Used";
VAL_ 1468 DriverMassageVelocityState 0 "No velocity" 1 "velocity 1" 2 "velocity 2" 3 "velocity 3" 4 "velocity 4" 5 "velocity 5" 6 "Not Used" 7 "Not Used";
VAL_ 1468 DriverMassageIntensityState 0 "No intensity" 1 "Intensity 1" 2 "Intensity 2" 3 "Intensity 3" 4 "Intensity 4" 5 "Intensity 5" 6 "Not Used" 7 "Not Used";
VAL_ 1468 DriverMassageActivationState 0 "Massage OFF" 1 "Massage ON";
